VERSION "HNNBNNNYNNNNNNNNNNNNNNNNNNNNNNNNNNNNNNNNNN/4/%%%/4/'%**4NNN///"

NS_ :

BS_:

BU_: Airbag_MQB BAP_Tester_MQB BMS_MQB Datenlogger_MQB Gateway_MQB Getriebe_DQ_Hybrid_MQB Getriebe_DQ_MQB LEH_MQB Motor_Diesel_MQB Motor_Hybrid_MQB Motor_Otto_MQB SAK_MQB Waehlhebel_MQB

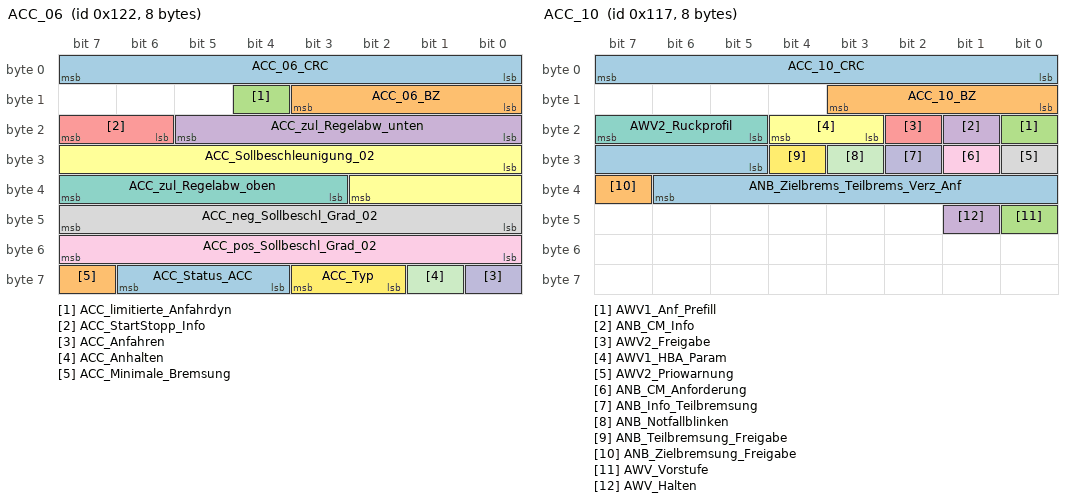
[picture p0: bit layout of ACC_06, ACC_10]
BO_ 290 ACC_06: 8 Gateway_MQB
 SG_ ACC_06_CRC : 0|8@1+ (1,0) [0|255] ""  Getriebe_DQ_Hybrid_MQB,Getriebe_DQ_MQB,Motor_Diesel_MQB,Motor_Hybrid_MQB,Motor_Otto_MQB
 SG_ ACC_06_BZ : 8|4@1+ (1,0) [0|15] ""  Getriebe_DQ_Hybrid_MQB,Getriebe_DQ_MQB,Motor_Diesel_MQB,Motor_Hybrid_MQB,Motor_Otto_MQB
 SG_ ACC_limitierte_Anfahrdyn : 12|1@1+ (1,0) [0|1] ""  Motor_Diesel_MQB,Motor_Hybrid_MQB,Motor_Otto_MQB
 SG_ ACC_zul_Regelabw_unten : 16|6@1+ (0.024,0) [0|1.512] "Unit_MeterPerSeconSquar"  Getriebe_DQ_Hybrid_MQB,Getriebe_DQ_MQB,Motor_Diesel_MQB,Motor_Hybrid_MQB,Motor_Otto_MQB
 SG_ ACC_StartStopp_Info : 22|2@1+ (1,0) [0|3] ""  Motor_Diesel_MQB,Motor_Otto_MQB
 SG_ ACC_Sollbeschleunigung_02 : 24|11@1+ (0.005,-7.22) [-7.22|3.005] "Unit_MeterPerSeconSquar"  Getriebe_DQ_Hybrid_MQB,Getriebe_DQ_MQB,Motor_Diesel_MQB,Motor_Hybrid_MQB,Motor_Otto_MQB
 SG_ ACC_zul_Regelabw_oben : 35|5@1+ (0.0625,0) [0|1.9375] "Unit_MeterPerSeconSquar"  Getriebe_DQ_Hybrid_MQB,Getriebe_DQ_MQB,Motor_Diesel_MQB,Motor_Hybrid_MQB,Motor_Otto_MQB
 SG_ ACC_neg_Sollbeschl_Grad_02 : 40|8@1+ (0.05,0) [0|12.75] "Unit_MeterPerCubicSecon"  Motor_Diesel_MQB,Motor_Hybrid_MQB,Motor_Otto_MQB
 SG_ ACC_pos_Sollbeschl_Grad_02 : 48|8@1+ (0.05,0) [0|12.75] "Unit_MeterPerCubicSecon"  Motor_Diesel_MQB,Motor_Hybrid_MQB,Motor_Otto_MQB
 SG_ ACC_Anfahren : 56|1@1+ (1,0) [0|1] ""  Getriebe_DQ_Hybrid_MQB,Getriebe_DQ_MQB,Motor_Diesel_MQB,Motor_Hybrid_MQB,Motor_Otto_MQB
 SG_ ACC_Anhalten : 57|1@1+ (1,0) [0|1] ""  Getriebe_DQ_Hybrid_MQB,Getriebe_DQ_MQB,Motor_Diesel_MQB,Motor_Hybrid_MQB,Motor_Otto_MQB
 SG_ ACC_Typ : 58|2@1+ (1,0) [0|3] ""  Motor_Diesel_MQB,Motor_Hybrid_MQB,Motor_Otto_MQB
 SG_ ACC_Status_ACC : 60|3@1+ (1,0) [0|7] ""  Getriebe_DQ_Hybrid_MQB,Getriebe_DQ_MQB,Motor_Diesel_MQB,Motor_Hybrid_MQB,Motor_Otto_MQB
 SG_ ACC_Minimale_Bremsung : 63|1@1+ (1,0) [0|1] ""  Motor_Diesel_MQB,Motor_Hybrid_MQB,Motor_Otto_MQB

BO_ 279 ACC_10: 8 Gateway_MQB
 SG_ ACC_10_CRC : 0|8@1+ (1,0) [0|255] ""  Airbag_MQB
 SG_ ACC_10_BZ : 8|4@1+ (1,0) [0|15] ""  Airbag_MQB
 SG_ AWV1_Anf_Prefill : 16|1@1+ (1,0) [0|1] ""  Airbag_MQB
 SG_ ANB_CM_Info : 17|1@1+ (1,0) [0|1] "" Vector__XXX
 SG_ AWV2_Freigabe : 18|1@1+ (1,0) [0|1] ""  Airbag_MQB
 SG_ AWV1_HBA_Param : 19|2@1+ (1,0) [0|3] "" Vector__XXX
 SG_ AWV2_Ruckprofil : 21|3@1+ (1,0) [0|7] "" Vector__XXX
 SG_ AWV2_Priowarnung : 24|1@1+ (1,0) [0|1] "" Vector__XXX
 SG_ ANB_CM_Anforderung : 25|1@1+ (1,0) [0|1] ""  Airbag_MQB
 SG_ ANB_Info_Teilbremsung : 26|1@1+ (1,0) [0|1] "" Vector__XXX
 SG_ ANB_Notfallblinken : 27|1@1+ (1,0) [0|1] "" Vector__XXX
 SG_ ANB_Teilbremsung_Freigabe : 28|1@1+ (1,0) [0|1] ""  Airbag_MQB
 SG_ ANB_Zielbrems_Teilbrems_Verz_Anf : 29|10@1+ (0.024,-20.016) [-20.016|4.536] "Unit_MeterPerSeconSquar"  Airbag_MQB
 SG_ ANB_Zielbremsung_Freigabe : 39|1@1+ (1,0) [0|1] ""  Airbag_MQB
 SG_ AWV_Vorstufe : 40|1@1+ (1,0) [0|1] "" Vector__XXX
 SG_ AWV_Halten : 41|1@1+ (1,0) [0|1] "" Vector__XXX

BO_ 64 Airbag_01: 8 Airbag_MQB
 SG_ Airbag_01_CRC : 0|8@1+ (1,0) [0|255] ""  BMS_MQB,Gateway_MQB,LEH_MQB,Motor_Diesel_MQB,Motor_Hybrid_MQB,Motor_Otto_MQB
 SG_ Airbag_01_BZ : 8|4@1+ (1,0) [0|15] ""  BMS_MQB,Gateway_MQB,LEH_MQB,Motor_Diesel_MQB,Motor_Hybrid_MQB,Motor_Otto_MQB
 SG_ AB_RGS_Anst : 12|4@1+ (1,0) [0|15] ""  Gateway_MQB
 SG_ AB_Front_Crash : 16|1@1+ (1,0) [0|1] ""  Gateway_MQB
 SG_ AB_Heck_Crash : 17|1@1+ (1,0) [0|1] ""  Gateway_MQB
 SG_ AB_SF_Crash : 18|1@1+ (1,0) [0|1] ""  Gateway_MQB
 SG_ AB_SB_Crash : 19|1@1+ (1,0) [0|1] ""  Gateway_MQB
 SG_ AB_Rollover_Crash : 20|1@1+ (1,0) [0|1] ""  Gateway_MQB
 SG_ AB_Crash_Int : 21|3@1+ (1,0) [0|7] ""  BMS_MQB,Gateway_MQB,LEH_MQB,Motor_Diesel_MQB,Motor_Hybrid_MQB,Motor_Otto_MQB
 SG_ AB_Lampe : 24|1@1+ (1,0) [0|1] ""  Gateway_MQB
 SG_ AB_Deaktiviert : 25|1@1+ (1,0) [0|1] ""  Gateway_MQB
 SG_ AB_VB_deaktiviert : 26|1@1+ (1,0) [0|1] ""  Gateway_MQB
 SG_ AB_Systemfehler : 27|1@1+ (1,0) [0|1] ""  BMS_MQB,Gateway_MQB,LEH_MQB
 SG_ AB_Diagnose : 28|1@1+ (1,0) [0|1] ""  Gateway_MQB
 SG_ AB_Stellgliedtest : 29|1@1+ (1,0) [0|1] ""  BMS_MQB,Gateway_MQB,Motor_Diesel_MQB,Motor_Hybrid_MQB,Motor_Otto_MQB
 SG_ AB_Erh_Auf_VB : 30|2@1+ (1,0) [0|3] ""  Gateway_MQB
 SG_ AB_Gurtwarn_VF : 32|1@1+ (1,0) [0|1] ""  Gateway_MQB
 SG_ AB_Gurtwarn_VB : 33|1@1+ (1,0) [0|1] ""  Gateway_MQB
 SG_ AB_Anzeige_Fussg : 34|2@1+ (1,0) [0|3] ""  Gateway_MQB
 SG_ AB_Texte_AKS : 36|2@1+ (1,0) [0|3] ""  Gateway_MQB
 SG_ AB_PAO_Leuchte_Anf : 38|1@1+ (1,0) [0|1] ""  Gateway_MQB
 SG_ AB_MKB_gueltig : 39|1@1+ (1,0) [0|1] ""  Gateway_MQB
 SG_ AB_MKB_Anforderung : 40|1@1+ (1,0) [0|1] ""  Gateway_MQB
 SG_ AB_Versorgungsspannung : 41|1@1+ (1,0) [0|1] ""  Gateway_MQB

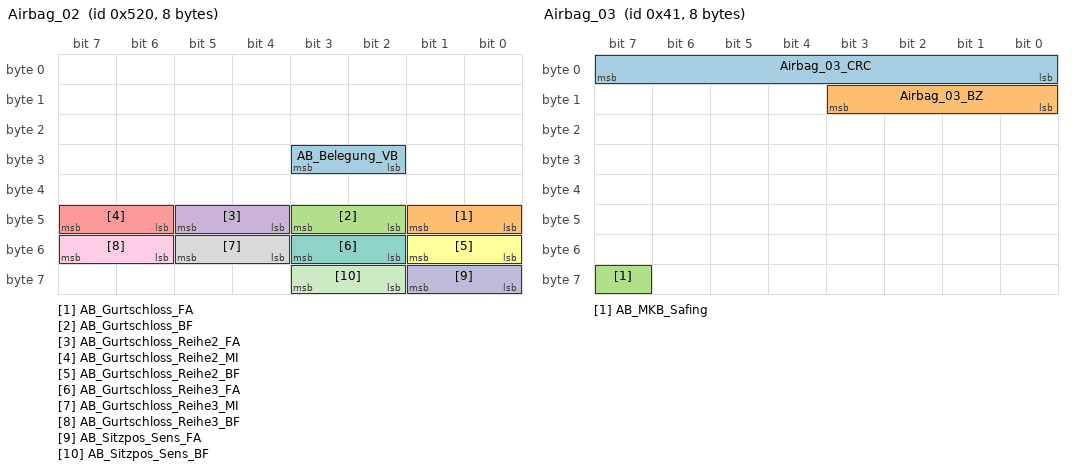
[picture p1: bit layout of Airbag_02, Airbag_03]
BO_ 1312 Airbag_02: 8 Airbag_MQB
 SG_ AB_Belegung_VB : 26|2@1+ (1,0) [0|3] ""  Gateway_MQB
 SG_ AB_Gurtschloss_FA : 40|2@1+ (1,0) [0|3] ""  Gateway_MQB,Motor_Diesel_MQB,Motor_Otto_MQB
 SG_ AB_Gurtschloss_BF : 42|2@1+ (1,0) [0|3] ""  Gateway_MQB
 SG_ AB_Gurtschloss_Reihe2_FA : 44|2@1+ (1,0) [0|3] ""  Gateway_MQB
 SG_ AB_Gurtschloss_Reihe2_MI : 46|2@1+ (1,0) [0|3] ""  Gateway_MQB
 SG_ AB_Gurtschloss_Reihe2_BF : 48|2@1+ (1,0) [0|3] ""  Gateway_MQB
 SG_ AB_Gurtschloss_Reihe3_FA : 50|2@1+ (1,0) [0|3] ""  Gateway_MQB
 SG_ AB_Gurtschloss_Reihe3_MI : 52|2@1+ (1,0) [0|3] ""  Gateway_MQB
 SG_ AB_Gurtschloss_Reihe3_BF : 54|2@1+ (1,0) [0|3] ""  Gateway_MQB
 SG_ AB_Sitzpos_Sens_FA : 56|2@1+ (1,0) [0|3] ""  Gateway_MQB
 SG_ AB_Sitzpos_Sens_BF : 58|2@1+ (1,0) [0|3] ""  Gateway_MQB

BO_ 65 Airbag_03: 8 Airbag_MQB
 SG_ Airbag_03_CRC : 0|8@1+ (1,0) [0|255] ""  Gateway_MQB
 SG_ Airbag_03_BZ : 8|4@1+ (1,0) [0|15] ""  Gateway_MQB
 SG_ AB_MKB_Safing : 63|1@1+ (1,0) [0|1] ""  Gateway_MQB

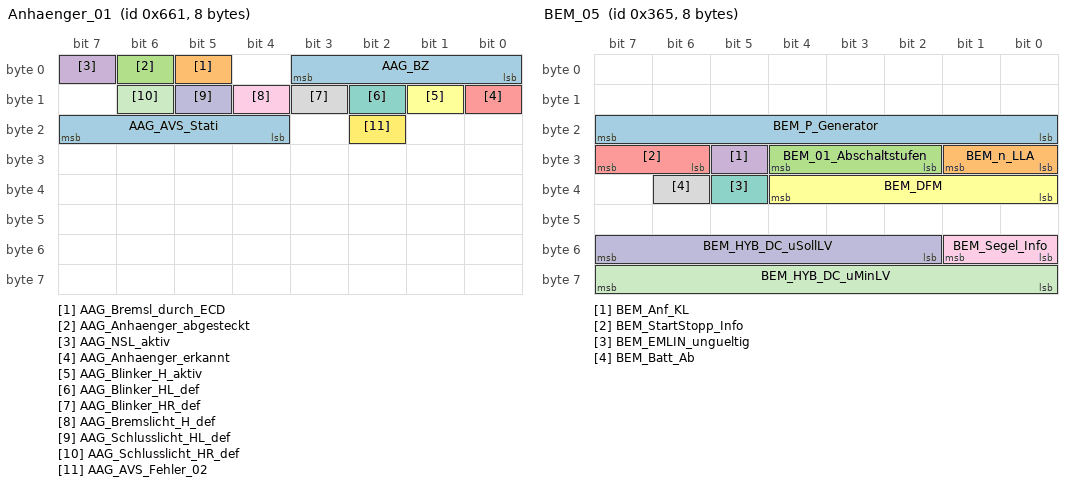
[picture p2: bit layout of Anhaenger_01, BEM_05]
BO_ 1633 Anhaenger_01: 8 Gateway_MQB
 SG_ AAG_BZ : 0|4@1+ (1,0) [0|15] ""  Motor_Diesel_MQB,Motor_Hybrid_MQB,Motor_Otto_MQB
 SG_ AAG_Bremsl_durch_ECD : 5|1@1+ (1,0) [0|1] ""  Motor_Diesel_MQB,Motor_Hybrid_MQB,Motor_Otto_MQB
 SG_ AAG_Anhaenger_abgesteckt : 6|1@1+ (1,0) [0|1] "" Vector__XXX
 SG_ AAG_NSL_aktiv : 7|1@1+ (1,0) [0|1] "" Vector__XXX
 SG_ AAG_Anhaenger_erkannt : 8|1@1+ (1,0) [0|1] ""  Motor_Diesel_MQB,Motor_Hybrid_MQB,Motor_Otto_MQB
 SG_ AAG_Blinker_H_aktiv : 9|1@1+ (1,0) [0|1] "" Vector__XXX
 SG_ AAG_Blinker_HL_def : 10|1@1+ (1,0) [0|1] "" Vector__XXX
 SG_ AAG_Blinker_HR_def : 11|1@1+ (1,0) [0|1] "" Vector__XXX
 SG_ AAG_Bremslicht_H_def : 12|1@1+ (1,0) [0|1] ""  Motor_Diesel_MQB,Motor_Hybrid_MQB,Motor_Otto_MQB
 SG_ AAG_Schlusslicht_HL_def : 13|1@1+ (1,0) [0|1] "" Vector__XXX
 SG_ AAG_Schlusslicht_HR_def : 14|1@1+ (1,0) [0|1] "" Vector__XXX
 SG_ AAG_AVS_Fehler_02 : 18|1@1+ (1,0) [0|1] "" Vector__XXX
 SG_ AAG_AVS_Stati : 20|4@1+ (1,0) [0|15] "" Vector__XXX

BO_ 2536767264 BAP_Debug_Cmd: 8 BAP_Tester_MQB
 SG_ BAP_Debug_Cmd : 0|16@1+ (1,0) [0|65535] ""  Airbag_MQB,Motor_Hybrid_MQB

BO_ 2536767280 BAP_Debug_Data: 8 Airbag_MQB
 SG_ BAP_Debug_Data : 0|64@1+ (1,0) [0|4294967295] ""  BAP_Tester_MQB

BO_ 2536709120 BAP_Hybrid_ASG_01: 8 Gateway_MQB
 SG_ BAP_Hybrid_FSG_01_Header : 0|8@1+ (1,0) [0|255] ""  Motor_Hybrid_MQB

BO_ 2536709121 BAP_Hybrid_ASG_02: 8 Gateway_MQB
 SG_ BAP_Hybrid_ASG_02_Header : 0|8@1+ (1,0) [0|255] ""  Motor_Hybrid_MQB

BO_ 2536709136 BAP_Hybrid_FSG_01: 8 Motor_Hybrid_MQB
 SG_ BAP_Hybrid_FSG_01_Header : 0|8@1+ (1,0) [0|255] ""  Gateway_MQB

BO_ 2536709888 BAP_RGS_ASG_01: 8 Gateway_MQB
 SG_ BAP_RGS_ASG_01_Header : 0|8@1+ (1,0) [0|255] ""  Airbag_MQB

BO_ 2536709904 BAP_RGS_FSG_01: 8 Airbag_MQB
 SG_ BAP_RGS_FSG_01_Header : 0|8@1+ (1,0) [0|255] ""  Gateway_MQB

BO_ 1626 BCM_01: 8 Gateway_MQB
 SG_ BCM_Bremsbelag_Sensor : 12|1@1+ (1,0) [0|1] "" Vector__XXX
 SG_ BCM_Bremsfluessigkeit_Sensor : 13|1@1+ (1,0) [0|1] "" Vector__XXX
 SG_ BCM1_Licht_Warn : 14|1@1+ (1,0) [0|1] "" Vector__XXX
 SG_ BCM_Waschwasser_Sensor : 15|1@1+ (1,0) [0|1] "" Vector__XXX
 SG_ BCM_Kuehlmittel_Sensor : 16|1@1+ (1,0) [0|1] ""  Motor_Diesel_MQB,Motor_Otto_MQB
 SG_ BCM1_Kl_15_HW_erkannt : 17|1@1+ (1,0) [0|1] "" Vector__XXX
 SG_ BCM_Eis_Offroad_Taste : 18|1@1+ (1,0) [0|1] ""  Getriebe_DQ_Hybrid_MQB,Getriebe_DQ_MQB,Motor_Diesel_MQB,Motor_Otto_MQB
 SG_ ZZH_Endlage_oben : 19|1@1+ (1,0) [0|1] "" Vector__XXX
 SG_ ZZH_Endlage_unten : 20|1@1+ (1,0) [0|1] "" Vector__XXX
 SG_ ZZH_Endlage_unplausibel : 21|1@1+ (1,0) [0|1] "" Vector__XXX
 SG_ BCM2_EZS_gedrueckt : 22|1@1+ (1,0) [0|1] "" Vector__XXX
 SG_ BCM2_SST_gedrueckt : 23|1@1+ (1,0) [0|1] "" Vector__XXX
 SG_ BCM_Hybrid_StartStopp_Taste : 24|1@1+ (1,0) [0|1] ""  Getriebe_DQ_Hybrid_MQB,Getriebe_DQ_MQB,Motor_Diesel_MQB,Motor_Hybrid_MQB,Motor_Otto_MQB
 SG_ BCM1_Warnblink_Taster : 25|1@1+ (1,0) [0|1] "" Vector__XXX
 SG_ BCM1_Valet_Parking_Taster : 26|1@1+ (1,0) [0|1] "" Vector__XXX
 SG_ BCM_Remotestart_Betrieb : 27|1@1+ (1,0) [0|1] ""  Motor_Diesel_MQB,Motor_Otto_MQB
 SG_ BCM1_HSK_Taster : 28|1@1+ (1,0) [0|1] "" Vector__XXX
 SG_ BCM1_Heckrollo_Taster : 29|1@1+ (1,0) [0|1] "" Vector__XXX
 SG_ BCM1_Rueckfahrlicht_Schalter : 30|1@1+ (1,0) [0|1] ""  Getriebe_DQ_Hybrid_MQB,Getriebe_DQ_MQB,Motor_Diesel_MQB,Motor_Hybrid_MQB,Motor_Otto_MQB
 SG_ BCM1_MH_Schalter : 31|1@1+ (1,0) [0|1] ""  Motor_Diesel_MQB,Motor_Otto_MQB
 SG_ BCM1_MH_WIV_Schalter : 32|1@1+ (1,0) [0|1] ""  Motor_Diesel_MQB,Motor_Hybrid_MQB,Motor_Otto_MQB
 SG_ BCM_Eco_Charisma_Taste : 33|1@1+ (1,0) [0|1] ""  Getriebe_DQ_Hybrid_MQB,Getriebe_DQ_MQB
 SG_ BCM_Thermomanagement : 34|2@1+ (1,0) [0|3] ""  Motor_Diesel_MQB,Motor_Hybrid_MQB,Motor_Otto_MQB
 SG_ BCM_Thermomanagement_Fehler : 36|1@1+ (1,0) [0|1] ""  Motor_Diesel_MQB,Motor_Hybrid_MQB,Motor_Otto_MQB
 SG_ BCM_Thermomanagement_gueltig : 37|1@1+ (1,0) [0|1] ""  Motor_Diesel_MQB,Motor_Hybrid_MQB,Motor_Otto_MQB
 SG_ BCM1_Lichtwarn_Texte : 38|2@1+ (1,0) [0|3] "" Vector__XXX

BO_ 869 BEM_05: 8 Gateway_MQB
 SG_ BEM_P_Generator : 16|8@1+ (50,0) [0|12700] "Unit_Watt"  Motor_Diesel_MQB,Motor_Hybrid_MQB,Motor_Otto_MQB
 SG_ BEM_n_LLA : 24|2@1+ (1,0) [0|3] ""  Motor_Diesel_MQB,Motor_Hybrid_MQB,Motor_Otto_MQB
 SG_ BEM_01_Abschaltstufen : 26|3@1+ (1,0) [0|7] ""  Motor_Diesel_MQB,Motor_Hybrid_MQB,Motor_Otto_MQB
 SG_ BEM_Anf_KL : 29|1@1+ (1,0) [0|1] ""  Motor_Diesel_MQB,Motor_Hybrid_MQB,Motor_Otto_MQB
 SG_ BEM_StartStopp_Info : 30|2@1+ (1,0) [0|3] ""  Motor_Diesel_MQB,Motor_Otto_MQB
 SG_ BEM_DFM : 32|5@1+ (3.225,0.025) [0.025|100] ""  Motor_Diesel_MQB,Motor_Hybrid_MQB,Motor_Otto_MQB
 SG_ BEM_EMLIN_ungueltig : 37|1@1+ (1,0) [0|1] ""  Motor_Diesel_MQB,Motor_Hybrid_MQB,Motor_Otto_MQB
 SG_ BEM_Batt_Ab : 38|1@1+ (1,0) [0|1] ""  Motor_Diesel_MQB,Motor_Hybrid_MQB,Motor_Otto_MQB
 SG_ BEM_Segel_Info : 48|2@1+ (1,0) [0|3] ""  Getriebe_DQ_Hybrid_MQB,Getriebe_DQ_MQB,Motor_Diesel_MQB,Motor_Hybrid_MQB,Motor_Otto_MQB
 SG_ BEM_HYB_DC_uSollLV : 50|6@1+ (0.1,10.6) [10.6|16] "Unit_Volt"  LEH_MQB
 SG_ BEM_HYB_DC_uMinLV : 56|8@1+ (0.1,0) [0|25.3] "Unit_Volt"  LEH_MQB

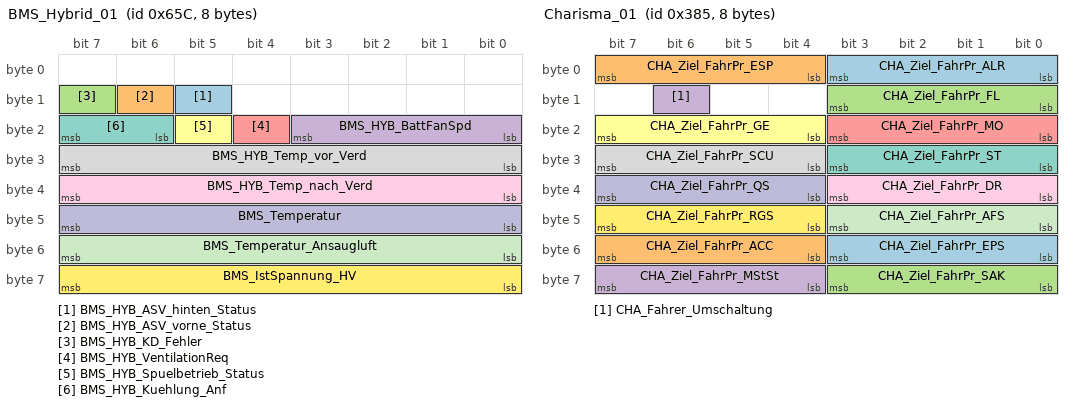
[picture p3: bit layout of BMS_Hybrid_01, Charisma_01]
BO_ 1628 BMS_Hybrid_01: 8 BMS_MQB
 SG_ BMS_HYB_ASV_hinten_Status : 13|1@1+ (1,0) [0|1] ""  Gateway_MQB
 SG_ BMS_HYB_ASV_vorne_Status : 14|1@1+ (1,0) [0|1] ""  Gateway_MQB
 SG_ BMS_HYB_KD_Fehler : 15|1@1+ (1,0) [0|1] ""  Gateway_MQB
 SG_ BMS_HYB_BattFanSpd : 16|4@1+ (10,0) [0|100] "Unit_PerCent"  Gateway_MQB
 SG_ BMS_HYB_VentilationReq : 20|1@1+ (1,0) [0|1] ""  Gateway_MQB
 SG_ BMS_HYB_Spuelbetrieb_Status : 21|1@1+ (1,0) [0|1] ""  Gateway_MQB
 SG_ BMS_HYB_Kuehlung_Anf : 22|2@1+ (1,0) [0|3] ""  Gateway_MQB
 SG_ BMS_HYB_Temp_vor_Verd : 24|8@1+ (0.5,-40) [-40|86.5] "Unit_DegreCelsi"  Gateway_MQB
 SG_ BMS_HYB_Temp_nach_Verd : 32|8@1+ (0.5,-40) [-40|86.5] "Unit_DegreCelsi"  Gateway_MQB
 SG_ BMS_Temperatur : 40|8@1+ (0.5,-40) [-40|86.5] "Unit_DegreCelsi"  Gateway_MQB
 SG_ BMS_Temperatur_Ansaugluft : 48|8@1+ (0.5,-40) [-40|86.5] "Unit_DegreCelsi"  Gateway_MQB
 SG_ BMS_IstSpannung_HV : 56|8@1+ (1,100) [100|350] "Unit_Volt"  Gateway_MQB

BO_ 2617236992 CCP_BMS_CRO_01: 8 Vector__XXX
 SG_ CCP_BMS_CRO_01_Data : 0|64@1+ (1,0) [0|1] ""  BMS_MQB

BO_ 2281692672 CCP_BMS_CRO_02: 8 Vector__XXX
 SG_ CCP_BMS_CRO_02_Data : 0|64@1+ (1,0) [0|1] ""  BMS_MQB

BO_ 2617236993 CCP_BMS_DTO_01: 8 BMS_MQB
 SG_ CCP_BMS_DTO_01_Data : 0|64@1+ (1,0) [0|1] "" Vector__XXX

BO_ 2281692673 CCP_BMS_DTO_02: 8 BMS_MQB
 SG_ CCP_BMS_DTO_02_Data : 0|64@1+ (1,0) [0|1] "" Vector__XXX

BO_ 2281684480 CCP_Getriebe_CRO_01: 8 Vector__XXX
 SG_ CCP_Getriebe_CRO_01_Data : 0|64@1+ (1,0) [0|4294967295] ""  Getriebe_DQ_Hybrid_MQB,Getriebe_DQ_MQB

BO_ 2281684481 CCP_Getriebe_DTO_01: 8 Getriebe_DQ_Hybrid_MQB
 SG_ CCP_Getriebe_DTO_01_Data : 0|64@1+ (1,0) [0|4294967295] "" Vector__XXX

BO_ 2281684482 CCP_Getriebe_DTO_02: 8 Getriebe_DQ_Hybrid_MQB
 SG_ CCP_Getriebe_DTO_02_Data : 0|64@1+ (1,0) [0|4294967295] "" Vector__XXX

BO_ 2281684483 CCP_Getriebe_DTO_03: 8 Getriebe_DQ_Hybrid_MQB
 SG_ CCP_Getriebe_DTO_03_Data : 0|64@1+ (1,0) [0|4294967295] "" Vector__XXX

BO_ 2281684484 CCP_Getriebe_DTO_04: 8 Getriebe_DQ_Hybrid_MQB
 SG_ CCP_Getriebe_DTO_04_Data : 0|64@1+ (1,0) [0|4294967295] "" Vector__XXX

BO_ 2617226752 CCP_Motor_CRO_01: 8 Gateway_MQB
 SG_ CCP_Motor_CRO_01_Data : 0|64@1+ (1,0) [0|4294967295] ""  Motor_Diesel_MQB,Motor_Hybrid_MQB,Motor_Otto_MQB

BO_ 2617226753 CCP_Motor_DTO_01: 8 Motor_Diesel_MQB
 SG_ CCP_Motor_DTO_01_Data : 0|64@1+ (1,0) [0|4294967295] ""  Gateway_MQB

BO_ 2617226754 CCP_Motor_DTO_02: 8 Motor_Diesel_MQB
 SG_ CCP_Motor_DTO_02_Data : 0|64@1+ (1,0) [0|4294967295] ""  Gateway_MQB

BO_ 2617226755 CCP_Motor_DTO_03: 8 Motor_Diesel_MQB
 SG_ CCP_Motor_DTO_03_Data : 0|64@1+ (1,0) [0|4294967295] ""  Gateway_MQB

BO_ 2617042432 CCP_Soundaktor_CRO_01: 8 Gateway_MQB
 SG_ CCP_Soundaktor_CRO_01_Data : 0|64@1+ (1,0) [0|4294967295] ""  SAK_MQB

BO_ 2617042433 CCP_Soundaktor_DTO_01: 8 SAK_MQB
 SG_ CCP_Soundaktor_DTO_01_Data : 0|64@1+ (1,0) [0|4294967295] ""  Gateway_MQB

BO_ 901 Charisma_01: 8 Gateway_MQB
 SG_ CHA_Ziel_FahrPr_ALR : 0|4@1+ (1,0) [0|15] "" Vector__XXX
 SG_ CHA_Ziel_FahrPr_ESP : 4|4@1+ (1,0) [0|15] "" Vector__XXX
 SG_ CHA_Ziel_FahrPr_FL : 8|4@1+ (1,0) [0|15] "" Vector__XXX
 SG_ CHA_Fahrer_Umschaltung : 14|1@1+ (1,0) [0|1] ""  Airbag_MQB,Getriebe_DQ_Hybrid_MQB,Getriebe_DQ_MQB,Motor_Diesel_MQB,Motor_Hybrid_MQB,Motor_Otto_MQB,SAK_MQB
 SG_ CHA_Ziel_FahrPr_MO : 16|4@1+ (1,0) [0|15] ""  Motor_Diesel_MQB,Motor_Hybrid_MQB,Motor_Otto_MQB
 SG_ CHA_Ziel_FahrPr_GE : 20|4@1+ (1,0) [0|15] ""  Getriebe_DQ_Hybrid_MQB,Getriebe_DQ_MQB
 SG_ CHA_Ziel_FahrPr_ST : 24|4@1+ (1,0) [0|15] "" Vector__XXX
 SG_ CHA_Ziel_FahrPr_SCU : 28|4@1+ (1,0) [0|15] "" Vector__XXX
 SG_ CHA_Ziel_FahrPr_DR : 32|4@1+ (1,0) [0|15] "" Vector__XXX
 SG_ CHA_Ziel_FahrPr_QS : 36|4@1+ (1,0) [0|15] "" Vector__XXX
 SG_ CHA_Ziel_FahrPr_AFS : 40|4@1+ (1,0) [0|15] "" Vector__XXX
 SG_ CHA_Ziel_FahrPr_RGS : 44|4@1+ (1,0) [0|15] ""  Airbag_MQB
 SG_ CHA_Ziel_FahrPr_EPS : 48|4@1+ (1,0) [0|15] "" Vector__XXX
 SG_ CHA_Ziel_FahrPr_ACC : 52|4@1+ (1,0) [0|15] "" Vector__XXX
 SG_ CHA_Ziel_FahrPr_SAK : 56|4@1+ (1,0) [0|15] ""  SAK_MQB
 SG_ CHA_Ziel_FahrPr_MStSt : 60|4@1+ (1,0) [0|15] "" Vector__XXX

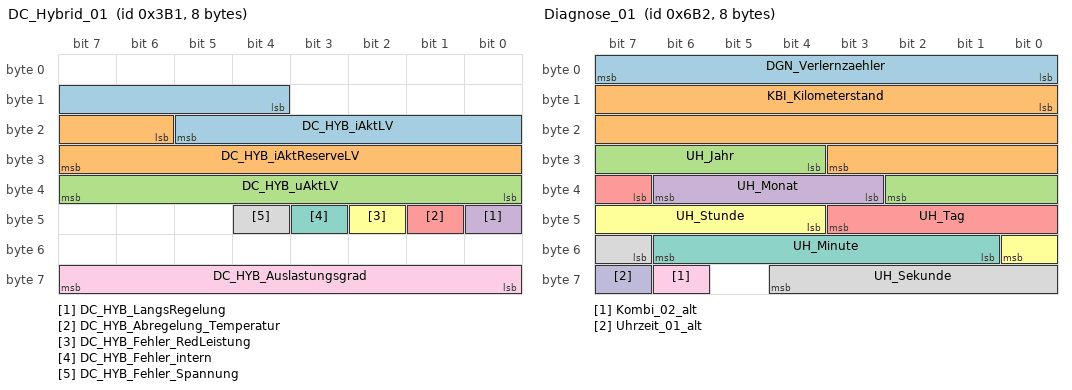
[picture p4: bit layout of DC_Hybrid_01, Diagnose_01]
BO_ 945 DC_Hybrid_01: 8 LEH_MQB
 SG_ DC_HYB_iAktLV : 12|10@1+ (1,-511) [-511|510] "Unit_Amper"  Gateway_MQB
 SG_ DC_HYB_iAktReserveLV : 22|10@1+ (1,-511) [-511|510] "Unit_Amper"  Gateway_MQB
 SG_ DC_HYB_uAktLV : 32|8@1+ (0.1,0) [0|25.3] "Unit_Volt"  Gateway_MQB
 SG_ DC_HYB_LangsRegelung : 40|1@1+ (1,0) [0|1] ""  Gateway_MQB
 SG_ DC_HYB_Abregelung_Temperatur : 41|1@1+ (1,0) [0|1] ""  Gateway_MQB
 SG_ DC_HYB_Fehler_RedLeistung : 42|1@1+ (1,0) [0|1] ""  Gateway_MQB
 SG_ DC_HYB_Fehler_intern : 43|1@1+ (1,0) [0|1] ""  Gateway_MQB
 SG_ DC_HYB_Fehler_Spannung : 44|1@1+ (1,0) [0|1] ""  Gateway_MQB
 SG_ DC_HYB_Auslastungsgrad : 56|8@1+ (0.4,0) [0|100] "Unit_PerCent"  Gateway_MQB

BO_ 2617235968 DEV_BMS_Resp_00: 8 BMS_MQB
 SG_ DEV_BMS_Resp_00_Data : 0|64@1+ (1,0) [0|4294967295] "" Vector__XXX

BO_ 2617235969 DEV_BMS_Resp_01: 8 BMS_MQB
 SG_ DEV_BMS_Resp_01_Data : 0|64@1+ (1,0) [0|4294967295] "" Vector__XXX

BO_ 2617235970 DEV_BMS_Resp_02: 8 BMS_MQB
 SG_ DEV_BMS_Resp_02_Data : 0|64@1+ (1,0) [0|4294967295] "" Vector__XXX

BO_ 2617235971 DEV_BMS_Resp_03: 8 BMS_MQB
 SG_ DEV_BMS_Resp_03_Data : 0|64@1+ (1,0) [0|4294967295] "" Vector__XXX

BO_ 2617235972 DEV_BMS_Resp_04: 8 BMS_MQB
 SG_ DEV_BMS_Resp_04_Data : 0|64@1+ (1,0) [0|4294967295] "" Vector__XXX

BO_ 2617235973 DEV_BMS_Resp_05: 8 BMS_MQB
 SG_ DEV_BMS_Resp_05_Data : 0|64@1+ (1,0) [0|4294967295] "" Vector__XXX

BO_ 2617235974 DEV_BMS_Resp_06: 8 BMS_MQB
 SG_ DEV_BMS_Resp_06_Data : 0|64@1+ (1,0) [0|4294967295] "" Vector__XXX

BO_ 2617235975 DEV_BMS_Resp_07: 8 BMS_MQB
 SG_ DEV_BMS_Resp_07_Data : 0|64@1+ (1,0) [0|4294967295] "" Vector__XXX

BO_ 2617227776 DEV_Getriebe_Resp_00: 8 Getriebe_DQ_Hybrid_MQB
 SG_ DEV_Getriebe_Resp_00_Data : 0|64@1+ (1,0) [0|4294967295] "" Vector__XXX

BO_ 2617227777 DEV_Getriebe_Resp_01: 8 Getriebe_DQ_Hybrid_MQB
 SG_ DEV_Getriebe_Resp_01_Data : 0|64@1+ (1,0) [0|4294967295] "" Vector__XXX

BO_ 2617227778 DEV_Getriebe_Resp_02: 8 Getriebe_DQ_Hybrid_MQB
 SG_ DEV_Getriebe_Resp_02_Data : 0|64@1+ (1,0) [0|4294967295] "" Vector__XXX

BO_ 2617227779 DEV_Getriebe_Resp_03: 8 Getriebe_DQ_Hybrid_MQB
 SG_ DEV_Getriebe_Resp_03_Data : 0|64@1+ (1,0) [0|4294967295] "" Vector__XXX

BO_ 2617227780 DEV_Getriebe_Resp_04: 8 Getriebe_DQ_Hybrid_MQB
 SG_ DEV_Getriebe_Resp_04_Data : 0|64@1+ (1,0) [0|4294967295] "" Vector__XXX

BO_ 2617227781 DEV_Getriebe_Resp_05: 8 Getriebe_DQ_Hybrid_MQB
 SG_ DEV_Getriebe_Resp_05_Data : 0|64@1+ (1,0) [0|4294967295] "" Vector__XXX

BO_ 2617227782 DEV_Getriebe_Resp_06: 8 Getriebe_DQ_Hybrid_MQB
 SG_ DEV_Getriebe_Resp_06_Data : 0|64@1+ (1,0) [0|4294967295] "" Vector__XXX

BO_ 2617227783 DEV_Getriebe_Resp_07: 8 Getriebe_DQ_Hybrid_MQB
 SG_ DEV_Getriebe_Resp_07_Data : 0|64@1+ (1,0) [0|4294967295] "" Vector__XXX

BO_ 2617154048 DEV_Waehlhebel_Resp_00: 8 Waehlhebel_MQB
 SG_ DEV_Waehlhebel_Resp_00_Data : 0|64@1+ (1,0) [0|4294967295] "" Vector__XXX

BO_ 2617154049 DEV_Waehlhebel_Resp_01: 8 Waehlhebel_MQB
 SG_ DEV_Waehlhebel_Resp_01_Data : 0|64@1+ (1,0) [0|4294967295] "" Vector__XXX

BO_ 2617154050 DEV_Waehlhebel_Resp_02: 8 Waehlhebel_MQB
 SG_ DEV_Waehlhebel_Resp_02_Data : 0|64@1+ (1,0) [0|4294967295] "" Vector__XXX

BO_ 2617154051 DEV_Waehlhebel_Resp_03: 8 Waehlhebel_MQB
 SG_ DEV_Waehlhebel_Resp_03_Data : 0|64@1+ (1,0) [0|4294967295] "" Vector__XXX

BO_ 2617154052 DEV_Waehlhebel_Resp_04: 8 Waehlhebel_MQB
 SG_ DEV_Waehlhebel_Resp_04_Data : 0|64@1+ (1,0) [0|4294967295] "" Vector__XXX

BO_ 2617154053 DEV_Waehlhebel_Resp_05: 8 Waehlhebel_MQB
 SG_ DEV_Waehlhebel_Resp_05_Data : 0|64@1+ (1,0) [0|4294967295] "" Vector__XXX

BO_ 1714 Diagnose_01: 8 Gateway_MQB
 SG_ DGN_Verlernzaehler : 0|8@1+ (1,0) [0|254] ""  Airbag_MQB,BMS_MQB,Getriebe_DQ_Hybrid_MQB,Getriebe_DQ_MQB,LEH_MQB,SAK_MQB
 SG_ KBI_Kilometerstand : 8|20@1+ (1,0) [0|1048573] "Unit_KiloMeter"  Airbag_MQB,BMS_MQB,Getriebe_DQ_Hybrid_MQB,Getriebe_DQ_MQB,LEH_MQB,Motor_Diesel_MQB,Motor_Hybrid_MQB,Motor_Otto_MQB,SAK_MQB
 SG_ UH_Jahr : 28|7@1+ (1,2000) [2000|2127] "Unit_Year"  Airbag_MQB,BMS_MQB,Getriebe_DQ_Hybrid_MQB,Getriebe_DQ_MQB,LEH_MQB,Motor_Diesel_MQB,Motor_Hybrid_MQB,Motor_Otto_MQB,SAK_MQB
 SG_ UH_Monat : 35|4@1+ (1,0) [1|12] "Unit_Month"  Airbag_MQB,BMS_MQB,Getriebe_DQ_Hybrid_MQB,Getriebe_DQ_MQB,LEH_MQB,Motor_Diesel_MQB,Motor_Hybrid_MQB,Motor_Otto_MQB,SAK_MQB
 SG_ UH_Tag : 39|5@1+ (1,0) [1|31] "Unit_Day"  Airbag_MQB,BMS_MQB,Getriebe_DQ_Hybrid_MQB,Getriebe_DQ_MQB,LEH_MQB,Motor_Diesel_MQB,Motor_Hybrid_MQB,Motor_Otto_MQB,SAK_MQB
 SG_ UH_Stunde : 44|5@1+ (1,0) [0|23] "Unit_Hours"  Airbag_MQB,BMS_MQB,Getriebe_DQ_Hybrid_MQB,Getriebe_DQ_MQB,LEH_MQB,Motor_Diesel_MQB,Motor_Hybrid_MQB,Motor_Otto_MQB,SAK_MQB
 SG_ UH_Minute : 49|6@1+ (1,0) [0|59] "Unit_Minut"  Airbag_MQB,BMS_MQB,Getriebe_DQ_Hybrid_MQB,Getriebe_DQ_MQB,LEH_MQB,Motor_Diesel_MQB,Motor_Hybrid_MQB,Motor_Otto_MQB,SAK_MQB
 SG_ UH_Sekunde : 55|6@1+ (1,0) [0|59] "Unit_Secon"  Airbag_MQB,BMS_MQB,Getriebe_DQ_Hybrid_MQB,Getriebe_DQ_MQB,LEH_MQB,Motor_Diesel_MQB,Motor_Hybrid_MQB,Motor_Otto_MQB,SAK_MQB
 SG_ Kombi_02_alt : 62|1@1+ (1,0) [0|1] ""  Airbag_MQB,BMS_MQB,LEH_MQB
 SG_ Uhrzeit_01_alt : 63|1@1+ (1,0) [0|1] ""  Airbag_MQB,BMS_MQB,LEH_MQB

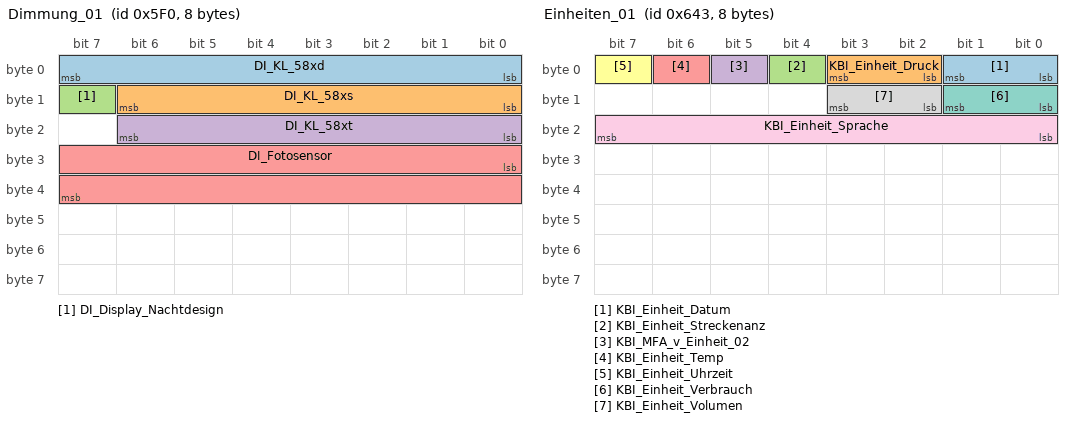
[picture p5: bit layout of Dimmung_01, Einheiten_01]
BO_ 1520 Dimmung_01: 8 Gateway_MQB
 SG_ DI_KL_58xd : 0|8@1+ (1,0) [0|253] ""  Airbag_MQB
 SG_ DI_KL_58xs : 8|7@1+ (1,0) [0|100] "Unit_PerCent" Vector__XXX
 SG_ DI_Display_Nachtdesign : 15|1@1+ (1,0) [0|1] "" Vector__XXX
 SG_ DI_KL_58xt : 16|7@1+ (1,0) [0|100] "Unit_PerCent" Vector__XXX
 SG_ DI_Fotosensor : 24|16@1+ (1,0) [0|65535] "" Vector__XXX

BO_ 1603 Einheiten_01: 8 Gateway_MQB
 SG_ KBI_Einheit_Datum : 0|2@1+ (1,0) [0|3] "" Vector__XXX
 SG_ KBI_Einheit_Druck : 2|2@1+ (1,0) [0|3] "" Vector__XXX
 SG_ KBI_Einheit_Streckenanz : 4|1@1+ (1,0) [0|1] ""  Motor_Diesel_MQB
 SG_ KBI_MFA_v_Einheit_02 : 5|1@1+ (1,0) [0|1] "" Vector__XXX
 SG_ KBI_Einheit_Temp : 6|1@1+ (1,0) [0|1] "" Vector__XXX
 SG_ KBI_Einheit_Uhrzeit : 7|1@1+ (1,0) [0|1] "" Vector__XXX
 SG_ KBI_Einheit_Verbrauch : 8|2@1+ (1,0) [0|3] "" Vector__XXX
 SG_ KBI_Einheit_Volumen : 10|2@1+ (1,0) [0|3] "" Vector__XXX
 SG_ KBI_Einheit_Sprache : 16|8@1+ (1,0) [0|255] "" Vector__XXX

BO_ 260 EPB_01: 8 Gateway_MQB
 SG_ EPB_01_CRC : 0|8@1+ (1,0) [0|255] ""  Getriebe_DQ_Hybrid_MQB,Getriebe_DQ_MQB,Motor_Diesel_MQB,Motor_Hybrid_MQB,Motor_Otto_MQB
 SG_ EPB_01_BZ : 8|4@1+ (1,0) [0|15] ""  Getriebe_DQ_Hybrid_MQB,Getriebe_DQ_MQB,Motor_Diesel_MQB,Motor_Hybrid_MQB,Motor_Otto_MQB
 SG_ EPB_QBit_Laengsbeschleunigung : 12|1@1+ (1,0) [0|1] "" Vector__XXX
 SG_ EPB_QBit_Pedalweg_Kuppl : 13|1@1+ (1,0) [0|1] "" Vector__XXX
 SG_ EPB_BCM2_Motor_Wakeup : 14|1@1+ (1,0) [0|1] "" Vector__XXX
 SG_ EPB_Freig_Verzoeg_Anf : 15|1@1+ (1,0) [0|1] ""  Motor_Diesel_MQB,Motor_Hybrid_MQB,Motor_Otto_MQB
 SG_ EPB_Verzoeg_Anf : 16|8@1+ (0.048,-7.968) [-7.968|4.224] "Unit_MeterPerSeconSquar" Vector__XXX
 SG_ EPB_Laengsbeschleunigung : 24|8@1+ (1,-128) [-128|126] "Unit_PerCentOfForceOfGravi" Vector__XXX
 SG_ EPB_Pedalweg_Kuppl : 32|8@1+ (0.4,0) [8|92] "Unit_PerCent" Vector__XXX
 SG_ EPB_Anfahrwunsch_erkannt : 48|1@1+ (1,0) [0|1] "" Vector__XXX
 SG_ EPB_DAA_Randbed_erf : 49|1@1+ (1,0) [0|1] ""  Getriebe_DQ_Hybrid_MQB,Getriebe_DQ_MQB
 SG_ EPB_Fehlerstatus : 50|2@1+ (1,0) [0|3] "" Vector__XXX
 SG_ EPB_Schalterposition : 52|2@1+ (1,0) [0|3] ""  Motor_Diesel_MQB,Motor_Hybrid_MQB,Motor_Otto_MQB
 SG_ EPB_QBit_Schalterpos : 54|1@1+ (1,0) [0|1] ""  Motor_Diesel_MQB,Motor_Hybrid_MQB,Motor_Otto_MQB
 SG_ EPB_Konsistenz_ACC : 55|1@1+ (1,0) [0|1] "" Vector__XXX
 SG_ EPB_Spannkraft : 56|5@1+ (1,0) [0|29] "Unit_KiloNewto"  Getriebe_DQ_Hybrid_MQB,Getriebe_DQ_MQB
 SG_ EPB_Status : 61|2@1+ (1,0) [0|3] ""  Getriebe_DQ_Hybrid_MQB,Getriebe_DQ_MQB,Motor_Diesel_MQB,Motor_Hybrid_MQB,Motor_Otto_MQB

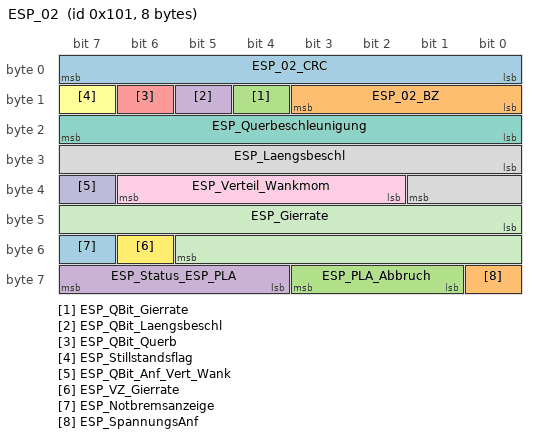
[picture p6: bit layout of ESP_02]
BO_ 257 ESP_02: 8 Gateway_MQB
 SG_ ESP_02_CRC : 0|8@1+ (1,0) [0|255] ""  Airbag_MQB,Getriebe_DQ_Hybrid_MQB,Getriebe_DQ_MQB,Motor_Diesel_MQB,Motor_Hybrid_MQB,Motor_Otto_MQB
 SG_ ESP_02_BZ : 8|4@1+ (1,0) [0|15] ""  Airbag_MQB,Getriebe_DQ_Hybrid_MQB,Getriebe_DQ_MQB,Motor_Diesel_MQB,Motor_Hybrid_MQB,Motor_Otto_MQB
 SG_ ESP_QBit_Gierrate : 12|1@1+ (1,0) [0|1] ""  Airbag_MQB,Getriebe_DQ_Hybrid_MQB,Getriebe_DQ_MQB
 SG_ ESP_QBit_Laengsbeschl : 13|1@1+ (1,0) [0|1] ""  Airbag_MQB,Getriebe_DQ_Hybrid_MQB,Getriebe_DQ_MQB,Motor_Diesel_MQB,Motor_Hybrid_MQB,Motor_Otto_MQB
 SG_ ESP_QBit_Querb : 14|1@1+ (1,0) [0|1] ""  Airbag_MQB,Getriebe_DQ_Hybrid_MQB,Getriebe_DQ_MQB,Motor_Diesel_MQB,Motor_Hybrid_MQB,Motor_Otto_MQB
 SG_ ESP_Stillstandsflag : 15|1@1+ (1,0) [0|1] "" Vector__XXX
 SG_ ESP_Querbeschleunigung : 16|8@1+ (0.01,-1.27) [-1.27|1.27] "Unit_ForceOfGravi"  Airbag_MQB,Getriebe_DQ_Hybrid_MQB,Getriebe_DQ_MQB,Motor_Diesel_MQB,Motor_Hybrid_MQB,Motor_Otto_MQB
 SG_ ESP_Laengsbeschl : 24|10@1+ (0.03125,-16) [-16|15.90625] "Unit_MeterPerSeconSquar"  Airbag_MQB,Getriebe_DQ_Hybrid_MQB,Getriebe_DQ_MQB,Motor_Diesel_MQB,Motor_Hybrid_MQB,Motor_Otto_MQB
 SG_ ESP_Verteil_Wankmom : 34|5@1+ (0.1,-1) [-1|1] "" Vector__XXX
 SG_ ESP_QBit_Anf_Vert_Wank : 39|1@1+ (1,0) [0|1] "" Vector__XXX
 SG_ ESP_Gierrate : 40|14@1+ (0.01,0) [0|163.82] "Unit_DegreOfArcPerSecon"  Airbag_MQB,Getriebe_DQ_Hybrid_MQB,Getriebe_DQ_MQB
 SG_ ESP_VZ_Gierrate : 54|1@1+ (1,0) [0|1] ""  Airbag_MQB,Getriebe_DQ_Hybrid_MQB,Getriebe_DQ_MQB
 SG_ ESP_Notbremsanzeige : 55|1@1+ (1,0) [0|1] ""  Airbag_MQB
 SG_ ESP_SpannungsAnf : 56|1@1+ (1,0) [0|1] "" Vector__XXX
 SG_ ESP_PLA_Abbruch : 57|3@1+ (1,0) [0|7] "" Vector__XXX
 SG_ ESP_Status_ESP_PLA : 60|4@1+ (1,0) [0|15] ""  Getriebe_DQ_Hybrid_MQB,Getriebe_DQ_MQB

BO_TX_BU_ 2536767280 : Airbag_MQB,Motor_Hybrid_MQB;
BO_TX_BU_ 2281684481 : Getriebe_DQ_Hybrid_MQB,Getriebe_DQ_MQB;
BO_TX_BU_ 2281684482 : Getriebe_DQ_Hybrid_MQB,Getriebe_DQ_MQB;
BO_TX_BU_ 2281684483 : Getriebe_DQ_Hybrid_MQB,Getriebe_DQ_MQB;
BO_TX_BU_ 2281684484 : Getriebe_DQ_Hybrid_MQB,Getriebe_DQ_MQB;
BO_TX_BU_ 2617226753 : Motor_Diesel_MQB,Motor_Hybrid_MQB,Motor_Otto_MQB;
BO_TX_BU_ 2617226754 : Motor_Diesel_MQB,Motor_Hybrid_MQB,Motor_Otto_MQB;
BO_TX_BU_ 2617226755 : Motor_Diesel_MQB,Motor_Hybrid_MQB,Motor_Otto_MQB;
BO_TX_BU_ 2617227776 : Getriebe_DQ_Hybrid_MQB,Getriebe_DQ_MQB;
BO_TX_BU_ 2617227777 : Getriebe_DQ_Hybrid_MQB,Getriebe_DQ_MQB;
BO_TX_BU_ 2617227778 : Getriebe_DQ_Hybrid_MQB,Getriebe_DQ_MQB;
BO_TX_BU_ 2617227779 : Getriebe_DQ_Hybrid_MQB,Getriebe_DQ_MQB;
BO_TX_BU_ 2617227780 : Getriebe_DQ_Hybrid_MQB,Getriebe_DQ_MQB;
BO_TX_BU_ 2617227781 : Getriebe_DQ_Hybrid_MQB,Getriebe_DQ_MQB;
BO_TX_BU_ 2617227782 : Getriebe_DQ_Hybrid_MQB,Getriebe_DQ_MQB;
BO_TX_BU_ 2617227783 : Getriebe_DQ_Hybrid_MQB,Getriebe_DQ_MQB;

CM_ "Modified by dbc-patcher V1.0F © 2009 Ingo Müller";
CM_ BO_ 290 "ab MQB";
CM_ SG_ 290 ACC_06_CRC "Für MLB:
Berechnung siehe Lastenheft 'Kommunikationsabsicherung für FlexRay und CAN''

Ab MQB und MLBevo:
Berechnung siehe Lastenheft 'End-to-End Kommunikationsabsicherung''

Endwerte siehe Begleitdokument 'S-PDU Kennungsfolgen'";
CM_ SG_ 290 ACC_limitierte_Anfahrdyn "Info für den Motor, dass beim ACC-Anfahren mit Zielfahrzeug seitens ACC eine limitierte Fahrpedalkennlinie gefordert wird.";
CM_ SG_ 290 ACC_zul_Regelabw_unten "Anforderung an den Triebstrangkoordinator. Zulässiger Betrag der Abweichung zwischen angeforderter 'ACC_Sollbeschleunigung(_02)' und umzusetzender Sollbeschleunigung  im TSK. Im TSK wird, abhängig vom Arbeitspunkt die Toleranz und die Sollbeschleunigung f";
CM_ SG_ 290 ACC_StartStopp_Info "Freigabe bzw. Startanforderung für Start/Stopp";
CM_ SG_ 290 ACC_Sollbeschleunigung_02 "Anforderung an den Triebstrangkoordinator , eine 'ACC_Sollbeschleunigung' umzusetzen.";
CM_ SG_ 290 ACC_zul_Regelabw_oben "Anforderung an den Triebstrangkoordinator. Zulässiger Betrag der Abweichung zwischen angeforderter 'ACC_Sollbeschleunigung(_02)' und umzusetzender Sollbeschleunigung  im TSK. Im TSK wird, abhängig vom Arbeitspunkt die Toleranz und die Sollbeschleunigung f";
CM_ SG_ 290 ACC_neg_Sollbeschl_Grad_02 "Empfehlung an den Triebstrangkoordinator , mit welchem betragsmäßig maximalen negativen Gradienten eine ACC-Anforderung 'ACC_Sollbeschleunigung_02' einzuregeln ist.";
CM_ SG_ 290 ACC_pos_Sollbeschl_Grad_02 "Empfehlung an den Triebstrangkoordinator , mit welchem betragsmäßig maximalen positiven Gradienten eine ACC-Anforderung 'ACC_Sollbeschleunigung_02' einzuregeln ist.";
CM_ SG_ 290 ACC_Anfahren "Anforderung Anfahren";
CM_ SG_ 290 ACC_Anhalten "Im Falle eines gesetzten Bits wird vom ACC ein Anhalten bis in den Stand gewünscht. Das Bit wird von ACC nur unterhalb einer appl. Geschwindigkeitsschwelle gesetzt. Notwendig für die ACCplus-Funktionalität. Nicht für B8 relevant, jedoch im Vorgriff auf di";
CM_ SG_ 290 ACC_Typ "Motor plausibilisiert seine eigene Kodierung";
CM_ SG_ 290 ACC_Status_ACC "ACC-Status für Handshake mit Triebstrangkoordinator.
";
CM_ SG_ 290 ACC_Minimale_Bremsung "Im Falle eines gesetzten Bits wird vom ACC dem TSK angezeigt, dass es sich im Resume_Suspend_Mode befindet. In diesem Mode darf der TSK keine ECD-Bremsung anfordern, unabhängig von der 'ACC_Sollbeschleunigungsanforderung'. Eine Fahrzeugverzögerung darf nu";
CM_ BO_ 279 "ersetzt AWV_01";
CM_ SG_ 279 ACC_10_CRC "Für MLB:
Berechnung siehe Lastenheft 'Kommunikationsabsicherung für FlexRay und CAN''

Ab MQB und MLBevo:
Berechnung siehe Lastenheft 'End-to-End Kommunikationsabsicherung''

Endwerte siehe Begleitdokument 'S-PDU Kennungsfolgen'";
CM_ SG_ 279 AWV1_Anf_Prefill "Anforderung an ESP, dass die Prefill-Funktion aktiviert werden soll.
Nur Audi B8: Umsetzung der Prefill-Anforderung im ESP nur in Verbindung mit gesetztem Bit 'AWV1_Freigabe'.";
CM_ SG_ 279 ANB_CM_Info "Information über die ANB_CM-Ausprägung";
CM_ SG_ 279 AWV2_Freigabe "Freigabit für die Warnruck-Anforderung an das ESP";
CM_ SG_ 279 AWV1_HBA_Param "Anforderung an ESP, welcher HBA-Parametersatz verwendet werden soll. Die Festlegung der Empfindlichkeitsschwellen der verschiedenen Parametersätze erfolgt mit der Applikation des Gesamtsystems ESP/ACC bzw. des HBA.
Nur Audi B8: Umsetzung der Anforderung ";
CM_ SG_ 279 AWV2_Ruckprofil "Anforderung an ESP, welcher Ruck aus einer Auswahl von max. 7 verschiedenen Ruckprofilen verwendet werden soll. Eine Umsetzung der Ruckanforderung im ESP erfolgt nur mit gesetztem Bit 'AWV2 Freigabe'.";
CM_ SG_ 279 AWV2_Priowarnung "Im Falle einer AWV2-Vorwarnung (optisch/akustisch) oder eines AWV2-Bremsruckes soll im LDW eine Fahrerwarnung bzgl. Verlassen der Fahrspur unterdrückt werden. (AWV2 hat Priorität. Eine gleichzeitige LDW-Warnung könnte den Fahrer irritieren.) 
";
CM_ SG_ 279 ANB_CM_Anforderung "ANB_CM-Anforderungsbit an das ESP";
CM_ SG_ 279 ANB_Info_Teilbremsung "Über das Signal s_ANB_Info_Teilbremsung muss das ACC-SG dem ESP-SG dauerhaft beginnend mit einer Teilbremsung-Anforderung mitteilen welche Ausprägung angefordert wird.

Signaldefinition: 
0x0 = Ausprägung 'Standard'
0x1 = Ausprägung 'Erweitert'";
CM_ SG_ 279 ANB_Notfallblinken "Info an das BCM_2 die Warnblinkanlage anzusteuern";
CM_ SG_ 279 ANB_Teilbremsung_Freigabe "Freigabe-Bit der Teilbremsung an das ESP";
CM_ SG_ 279 ANB_Zielbrems_Teilbrems_Verz_Anf "Verzögerungsanforderung der Funktionen Zielbremsung und Teibremsung an das ESP";
CM_ SG_ 279 ANB_Zielbremsung_Freigabe "Freigabe-Bit der Zielbremsung an das ESP";
CM_ SG_ 279 AWV_Vorstufe "Info an das Restfahrzeug, dass in Kürze eine Notbremsung/schnelles Ausweichmanöver erfolgt (Info wird u.a. in Dämpferregelung zur Anpassung der Regelung verwendet)";
CM_ SG_ 279 AWV_Halten "Anforderung an das ESP, das Fahrzeug nach erfolgter automatischer Bremsung bis in den Stillstand im Stillstand zu halten und eine Fahrer-Überwachung zu aktivieren.";
CM_ BO_ 64 "ab MQB mit CRC-8";
CM_ SG_ 64 Airbag_01_CRC "Für MLB:
Berechnung siehe Lastenheft 'Kommunikationsabsicherung für FlexRay und CAN''

Ab MQB und MLBevo:
Berechnung siehe Lastenheft 'End-to-End Kommunikationsabsicherung''

Endwerte siehe Begleitdokument 'S-PDU Kennungsfolgen'";
CM_ SG_ 64 AB_RGS_Anst "PreCrash-Ansteuerung reversibler Gurtstraffer (Aktivierung und Kraftniveau)

10xx = deaktiviert";
CM_ SG_ 64 AB_Front_Crash "Bit wird bei Überschreitung der Gurtstraffer-, US- und RdW-Schwelle gesetzt";
CM_ SG_ 64 AB_Heck_Crash "Wird für alle neu anlaufenden Projekte umgesetzt: AB8.4, Audi8/VW8";
CM_ SG_ 64 AB_SF_Crash "Z.Zt. nur in Verbindung mit Crash-Intensität >= 100b (Kraftstoffpumpenabschaltung) verwendet.";
CM_ SG_ 64 AB_SB_Crash "Z.Zt. nur in Verbindung mit Crash-Intensität >= 100b (Kraftstoffpumpenabschaltung) verwendet.
";
CM_ SG_ 64 AB_Rollover_Crash "Wird im B6/B7 Cabrio und New Beetle Cabrio bedient. ";
CM_ SG_ 64 AB_Crash_Int "Crash_Intensität_1 = fahrzeugabhängige Reaktionen im Crash
Crash_Intensität_2 = fahrzeugabhängige Reaktionen im Crash
Crash_Intensität_3 = fahrzeugabhängige Reaktionen im Crash

Die jeweiligen fahrzeugabhängigen Reaktionen im Crash sind in einem separ";
CM_ SG_ 64 AB_Lampe "Sicherheitswarnlampe im Kombi wird vom Airbag-SG angesteuert; Zustand der Lampe wird auf dem CAN-Bus ausgegeben (auch Blinkinformation).";
CM_ SG_ 64 AB_Deaktiviert "Airbag oder Gurtstraffer wurden per Anpassung deaktiviert: Aktualisierung erst nach Selbsttest";
CM_ SG_ 64 AB_VB_deaktiviert "Als Option vorgehalten, Beifahrerairbag wurden per Schlüsselschalter oder Insassenerkennung deaktiviert";
CM_ SG_ 64 AB_Systemfehler "Systemfehler Ggf. wird Warnlampe dauernd eingeschaltet.";
CM_ SG_ 64 AB_Diagnose "Airbag in Diagnose";
CM_ SG_ 64 AB_Stellgliedtest "Information, ob Airbag im Stellgliedtest ist, um eine Notrufauflösung beim Stellgliedtest zu verhindern";
CM_ SG_ 64 AB_Erh_Auf_VB "Der Fahrer soll bei einem Statuswechsel des Beifahrerairbags (ausgelöst durch die Beifahrerinsassenerkennung oder den Schlüsselschloßschalter) aufmerksam gemacht werden durch eine Anzeige im Kombi. Nur Audi: gültig für: AB2 (4-Türer AU352), B7, C6, D3";
CM_ SG_ 64 AB_Gurtwarn_VF "Fahrer hat Gurt nicht gesteckt, Anzeige im Kombi";
CM_ SG_ 64 AB_Gurtwarn_VB "Beifahrer hat Gurt nicht gesteckt, Anzeige im Kombi";
CM_ SG_ 64 AB_Anzeige_Fussg "Anzeige für ausgelöste Fussgängerschutz-Aktuatorik";
CM_ SG_ 64 AB_Texte_AKS "Textanzeige für pyrotechnische Auslösung der aktiven Kopfstütze (AKS)";
CM_ SG_ 64 AB_PAO_Leuchte_Anf "Anforderung an die Passenger-Airbag-Off Leuchte in der Dachkonsole (ein / aus), Einsatz nur bei PAG";
CM_ SG_ 64 AB_MKB_gueltig "Multi-Kollisions-Bremsung im Airbag freigeschaltet";
CM_ SG_ 64 AB_MKB_Anforderung "Anforderung Multi-Kollisions-Bremsung";
CM_ SG_ 64 AB_Versorgungsspannung "Übertragung der Plausibilitätsinformation Kl.15-Last vs. Kl.15-CAN.
Bedienung im Fall Kl.15-Last 'EIN' und Kl.15-CAN 'AUS' mit Ausgabe Warnung/Akustik im Kombi.";
CM_ SG_ 1312 AB_Belegung_VB "Belegungserkennung vorne Beifahrer. Wird in US-Steuergeräten über Bladder-Matte bedient, optional bei RdW, falls SBE_EuroNCAP entschieden wird.";
CM_ SG_ 1312 AB_Gurtschloss_FA "Gurtschlosstatatus Fahrerseite";
CM_ SG_ 1312 AB_Gurtschloss_BF "Gurtschlossstatus Beifahrerseite";
CM_ SG_ 1312 AB_Gurtschloss_Reihe2_FA "Gurtschlossstatus 2. Reihe Fahrerseite, Mehrausstattung";
CM_ SG_ 1312 AB_Gurtschloss_Reihe2_MI "Gurtschlossstatus 2. Reihe Mitte,  Mehrausstattung";
CM_ SG_ 1312 AB_Gurtschloss_Reihe2_BF "Gurtschlossstatus 2. Reihe Beifahrerseite,  Mehrausstattung";
CM_ SG_ 1312 AB_Gurtschloss_Reihe3_FA "Gurtschlossstatus 3. Reihe Fahrerseite,  Mehrausstattung";
CM_ SG_ 1312 AB_Gurtschloss_Reihe3_MI "Gurtschlossstatus 3. Reihe Mitte,  Mehrausstattung";
CM_ SG_ 1312 AB_Gurtschloss_Reihe3_BF "Gurtschlossstatus 3. Reihe Beifahrerseite,  Mehrausstattung";
CM_ SG_ 1312 AB_Sitzpos_Sens_FA "Ausgabe Sitzposition Fahrer";
CM_ SG_ 1312 AB_Sitzpos_Sens_BF "Ausgabe Sitzposition Beifahrer";
CM_ SG_ 65 Airbag_03_CRC "Für MLB:
Berechnung siehe Lastenheft 'Kommunikationsabsicherung für FlexRay und CAN''

Ab MQB und MLBevo:
Berechnung siehe Lastenheft 'End-to-End Kommunikationsabsicherung''

Endwerte siehe Begleitdokument 'S-PDU Kennungsfolgen'";
CM_ SG_ 65 AB_MKB_Safing "Safing für Multi-Kollisions-Bremsung";
CM_ BO_ 1633 "ab MQB 7.2";
CM_ SG_ 1633 AAG_BZ "4bit-Botschaftszaehler, wird in jeder Sendebotschaft inkrementiert

";
CM_ SG_ 1633 AAG_Bremsl_durch_ECD "Bremslicht durch ECD aktiv";
CM_ SG_ 1633 AAG_Anhaenger_abgesteckt "Anhaenger wurde bei Kl. 15 aus abgesteckt";
CM_ SG_ 1633 AAG_NSL_aktiv "Anhaenger Nebelschlusslicht aktiv";
CM_ SG_ 1633 AAG_Anhaenger_erkannt "Erkennung Anhaenger ";
CM_ SG_ 1633 AAG_Blinker_H_aktiv "Status: Anhaenger Blinker aktiv";
CM_ SG_ 1633 AAG_Blinker_HL_def "Anhaenger Blinker links defekt";
CM_ SG_ 1633 AAG_Blinker_HR_def "Anhaenger Blinker rechts defekt";
CM_ SG_ 1633 AAG_Bremslicht_H_def "Anhaenger Bremslicht defekt";
CM_ SG_ 1633 AAG_Schlusslicht_HL_def "Anhaenger Schlußlicht links defekt";
CM_ SG_ 1633 AAG_Schlusslicht_HR_def "Anhaenger Schlußlicht rechts defekt";
CM_ SG_ 1633 AAG_AVS_Fehler_02 "Fehler AVS";
CM_ SG_ 1633 AAG_AVS_Stati "Status AVS (bei abnehmbarer oder mech.schwenkbarer Anhängerkupplung ist der Status immer 0)
";
CM_ BO_ 2536767264 "BAP-Msg vom Funktionssteuergerät";
CM_ BO_ 2536767280 "BAP-Msg vom Funktionssteuergerät";
CM_ SG_ 1626 BCM_Bremsbelag_Sensor "Sensorsignal der Stromschleife  für Bremsbelagverschleiß aktuell, entstört, unbewertet";
CM_ SG_ 1626 BCM_Bremsfluessigkeit_Sensor "Kontaktsignal des Sensorschalters für die Bremsflüssigkeitsreserve aktuell, entstört, unbewertet";
CM_ SG_ 1626 BCM1_Licht_Warn "Lichtwarnung";
CM_ SG_ 1626 BCM_Waschwasser_Sensor "Signal der Sensorelektroden für die Waschwasserreserve aktuell, entstört, bewertet (OK/Mangel)";
CM_ SG_ 1626 BCM_Kuehlmittel_Sensor "Signal der Sensorelektroden für die Kühlmittelreserve aktuell, entstört, bewertet (OK/Mangel)";
CM_ SG_ 1626 BCM1_Kl_15_HW_erkannt "Erkennung Klemme 15 (Hardware) vom BCM1
";
CM_ SG_ 1626 BCM_Eis_Offroad_Taste "Betaetigung Taste 'Eis' oder alternativ Taste 'Offroad'";
CM_ SG_ 1626 ZZH_Endlage_oben "obere Endlagenerkennung ZZH
";
CM_ SG_ 1626 ZZH_Endlage_unten "untere Endlagenerkennung ZZH
";
CM_ SG_ 1626 ZZH_Endlage_unplausibel "Erkennungung unplausible Endlage ZZH
";
CM_ SG_ 1626 BCM2_EZS_gedrueckt "Betätigung EZS";
CM_ SG_ 1626 BCM2_SST_gedrueckt "Betätigung Start-Stop-Taster (Kessy-Fahrzeug)";
CM_ SG_ 1626 BCM_Hybrid_StartStopp_Taste "Betaetigung Taster 'Hybrid' oder alternativ Taster 'Start/Stopp Deaktivierung', je nach Verbau";
CM_ SG_ 1626 BCM1_Warnblink_Taster "Warnblinktaster";
CM_ SG_ 1626 BCM1_Valet_Parking_Taster "Valet Parking Taster ";
CM_ SG_ 1626 BCM_Remotestart_Betrieb "Anforderung Remotestartbetrieb";
CM_ SG_ 1626 BCM1_HSK_Taster "Taster für Entriegelung Handschuhkasten
";
CM_ SG_ 1626 BCM1_Heckrollo_Taster "Betätigung Taster Heckrollo
";
CM_ SG_ 1626 BCM1_Rueckfahrlicht_Schalter "Rückfahrlichtschalter
Die Ganginformation wird unentprellt übertragen, im AT-Getriebe wird evtl. kurzzeitig der R-Gang angezeigt.
Eine Entprellung muß im Empfänger erfolgen (typisch 400ms).";
CM_ SG_ 1626 BCM1_MH_Schalter "Motorhaubenkontakt";
CM_ SG_ 1626 BCM1_MH_WIV_Schalter "Bewerteter Motorhaubenkontakt fuer WIV";
CM_ SG_ 1626 BCM_Eco_Charisma_Taste "Betätigung Taster ECO alias BlueKey oder Charisma";
CM_ SG_ 1626 BCM_Thermomanagement "Nur bei Verbau eines unvernetzten Heizungsbedienteil: Heizungsanforderung zur Berücksichtigung im Thermomanagement (Stellung des Kalt-Warm-Stellers wird in diesem Fall vom BCM eingelesen)";
CM_ SG_ 1626 BCM_Thermomanagement_Fehler "Fehler-Bit: Das BCM hat bei Verbau eines Heizungsbedienteils einen Fehler im Spannungssignal des Kalt-Warm-Stellers erkannt (Out-of-Range)
";
CM_ SG_ 1626 BCM_Thermomanagement_gueltig "Gueltig-Bit, mit dem das BCM  den Verbau eines Heizungsbedienteils kennzeichnet. Die Heizungsanforderung wird dann in BCM_Thermomanagement übertragen.";
CM_ SG_ 1626 BCM1_Lichtwarn_Texte "Anforderung von Lichtwarnungen vom BCM1 zum Kombi";
CM_ BO_ 869 "ab MQB";
CM_ SG_ 869 BEM_P_Generator "Es gilt: Signalspec BEM_P_Generator v1.0

Mechanische Generatorleistung dient dem Motorsteuergerät zur Berechnung der Motorlast; Genauigkeit ca. +/- (500W + 20% vom Messwert)";
CM_ SG_ 869 BEM_n_LLA "Es gilt: Signalspec BEM_n_LLA v1.0

Anforderung einer Leerlaufdrehzahlanhebung in drei Stufen. Die Höhe der jeweiligen LL-Drehzahlstufe ist im Motorsteuergerät appliziert.



";
CM_ SG_ 869 BEM_01_Abschaltstufen "Signal inhaltlich identisch mit BEM_02_Abschaltstufen. Namentliche Umbenennung wegen Standard-SW im Gateway-BEM im B8 (Handling gleicher Signalnamen im Source-Code).
Abschaltstufen des Ruhestrommanagements 
(Initialisierungswert aus EEPROM)";
CM_ SG_ 869 BEM_Anf_KL "Es gilt: Signalspec BEM_Anf_KL v1.1
Das BEM fordert über das MSG den Kühlerlüfter-Betrieb an; hierzu wird ein minimaler Leistungswert im MSG appliziert. 
Szenario: bei erkannter abgetrennten Batterie soll durch Ansteuerung des Kühlerlüfters das Energien";
CM_ SG_ 869 BEM_StartStopp_Info "Stopp-Freigabe und Start-Anforderung an den Start-Stopp-Koordinator";
CM_ SG_ 869 BEM_DFM "Generatorauslastungsgrad, vom Generator über LIN an das Gateway gesandt. Das Motorsteuergerät regelt auf dieses Signal die PTC, das Energiemanagement im BSG/BCM kalkuliert die Bordnetzauslastung";
CM_ SG_ 869 BEM_EMLIN_ungueltig "Energie-Lin - Signale sind ungültig vom Slave Batteriedatenmodul oder Generator
0 = Signale gültig
1 = Signale ungültig";
CM_ SG_ 869 BEM_Batt_Ab "Batterieverbindungskontrolle:
0x0: Batterie am Bordnetz
0x1: Batterie ab erkannt";
CM_ SG_ 869 BEM_Segel_Info "0: keine Anforderung 
(Segeln ist ohne Einschänkung erlaubt)
1: Mindestdrehzahl 1 
(Segeln ist mit Einschänkung erlaubt)
2: Mindestdrehzahl 2
(Segeln ist mit Einschänkung erlaubt)
3: Segelveto
(Segeln ist nicht  erlaubt)";
CM_ SG_ 869 BEM_HYB_DC_uSollLV "Sollwert für die Bordnetzspannung im Tiefsetzbetrieb vom Traktionsnetz ins Bordnetz (Hybrid)";
CM_ SG_ 869 BEM_HYB_DC_uMinLV "Abregelgrenze: minimal erlaubte Bordnetzspannung im Hochsetzbetrieb (Hybrid)";
CM_ SG_ 1628 BMS_HYB_ASV_hinten_Status "Status Absperrventil des Kältemittelkreislaufs zur Batteriekühlung";
CM_ SG_ 1628 BMS_HYB_ASV_vorne_Status "Status Absperrventil des Kältemittelkreislaufs zur Innenraumklimatisierung";
CM_ SG_ 1628 BMS_HYB_KD_Fehler "Bei gesetztem Bit ist mindestens ein Kundendienstfehler eingetragen";
CM_ SG_ 1628 BMS_HYB_BattFanSpd "Relativwert der Batterielüfter-Ansteuerung bezogen auf Maximalwert";
CM_ SG_ 1628 BMS_HYB_VentilationReq "BMS fordert bei Climatronic die Öffnung der Umluftklappe an";
CM_ SG_ 1628 BMS_HYB_Spuelbetrieb_Status "Status Betriebsart der Batterielüftung (Umluft-/Spülbetrieb)";
CM_ SG_ 1628 BMS_HYB_Kuehlung_Anf "Anforderung für aktive Batteriekühlung in vier Stufen:
Stufe 0: keine Kühlanforderung
Stufe 1: 10 °C Verdampfertemperatur Klima
Stufe 2: 3 °C Verdampfertemperatur Klima
Stufe 3: maximale Kühlleistung Klima";
CM_ SG_ 1628 BMS_HYB_Temp_vor_Verd "Lufttemperatur im Klimagerät BMS vor Verdampfer";
CM_ SG_ 1628 BMS_HYB_Temp_nach_Verd "Lufttemperatur im Klimagerät BMS nach Verdampfer";
CM_ SG_ 1628 BMS_Temperatur "battery temperature / Momentanwert: Temperatur der Traktionsbatterie";
CM_ SG_ 1628 BMS_Temperatur_Ansaugluft "Temperature of inlet air / Momentanwert: Ansauglufttemperatur der Batteriekühlung";
CM_ SG_ 1628 BMS_IstSpannung_HV "HV Spannungswert";
CM_ BO_ 901 "ab MQB ohne CHK und mit geänderter Sendeart";
CM_ SG_ 901 CHA_Ziel_FahrPr_ALR "Anforderung Ziel-Fahrprogramm Allrad";
CM_ SG_ 901 CHA_Ziel_FahrPr_ESP "Anforderung Ziel-Fahrprogramm ESP";
CM_ SG_ 901 CHA_Ziel_FahrPr_FL "Anforderung Ziel-Fahrprogramm Funktion Freilauf";
CM_ SG_ 901 CHA_Fahrer_Umschaltung "Die manuelle Umschaltung durch den Fahrer soll signalisiert werden, um zu automatischen Umschaltungen (z.B. Retries) differenzieren zu können.";
CM_ SG_ 901 CHA_Ziel_FahrPr_MO "Anforderung Ziel-Fahrprogramm Motor";
CM_ SG_ 901 CHA_Ziel_FahrPr_GE "Anforderung Ziel-Fahrprogramm Getriebe";
CM_ SG_ 901 CHA_Ziel_FahrPr_ST "Anforderung Ziel-Fahrprogramm ServoTronic";
CM_ SG_ 901 CHA_Ziel_FahrPr_SCU "Anforderung Ziel-Fahrprogramm SCU";
CM_ SG_ 901 CHA_Ziel_FahrPr_DR "Anforderung Ziel-Fahrprogramm Dämpfer";
CM_ SG_ 901 CHA_Ziel_FahrPr_QS "Anforderung Ziel-Fahrprogramm Quattro Sport";
CM_ SG_ 901 CHA_Ziel_FahrPr_AFS "Anforderung Ziel-Fahrprogramm AFS";
CM_ SG_ 901 CHA_Ziel_FahrPr_RGS "Anforderung Ziel-Fahrprogramm Funktion Reversibler Gurtstraffer";
CM_ SG_ 901 CHA_Ziel_FahrPr_EPS "Anforderung Ziel-Fahrprogramm Elekrische Lenkhilfe";
CM_ SG_ 901 CHA_Ziel_FahrPr_ACC "Anforderung Ziel-Fahrprogramm ACC";
CM_ SG_ 901 CHA_Ziel_FahrPr_SAK "Anforderung Ziel-Fahrprogramm Soundaktuator";
CM_ SG_ 901 CHA_Ziel_FahrPr_MStSt "Anforderung Ziel-Fahrprogramm Funktion Motor Start-Stopp";
CM_ SG_ 945 DC_HYB_iAktLV "Momentanwert: Strom vom DC/DC-Wandler in das Bordnetz";
CM_ SG_ 945 DC_HYB_iAktReserveLV "Momentanwert: Stromreserve vom DC/DC-Wandler in Richtung 12V-Bordnetz";
CM_ SG_ 945 DC_HYB_uAktLV "Momentanwert: NV-Bordnetzspannung am DC/DC-Wandler";
CM_ SG_ 945 DC_HYB_LangsRegelung "aktueller Regelmode des DC/DC-Wandlers.
0: normale Regelung
1: langsame Regelung";
CM_ SG_ 945 DC_HYB_Abregelung_Temperatur "Abregelung aufgrund Übertemperatur im Leistungsteil (Hochtemperatur-Abregelung)";
CM_ SG_ 945 DC_HYB_Fehler_RedLeistung "Fehler: eingeschränkte Leistungsfähigkeit des DC/DC-Wandlers aufgrund eines internen Fehlers";
CM_ SG_ 945 DC_HYB_Fehler_intern "Fehler: DC/DC-Wandler ist aufgrund eines internen Hardware-Fehlers abgeschaltet";
CM_ SG_ 945 DC_HYB_Fehler_Spannung "Abschaltung aufgrund Unter-/Überspannung auf der Ein-/Ausgangsseite";
CM_ SG_ 945 DC_HYB_Auslastungsgrad "Momentanwert: Auslastung DC/DC (DFM Signal), entspricht I_akt / I_max
(Vorhalt für MQB)";
CM_ SG_ 1714 DGN_Verlernzaehler "wrap around 254 --> 0";
CM_ SG_ 1714 KBI_Kilometerstand "Fehler wird ausgegeben, falls Kilometerstand nicht restaurierbar
";
CM_ SG_ 1714 UH_Monat "0x0D, 0xF =  Werte ungültig
0x0E = reserviert (nur VW)";
CM_ SG_ 1714 UH_Tag "0x0: reserviert bei VW";
CM_ SG_ 1714 UH_Stunde "0x18 - 0x1F = Werte ungültig";
CM_ SG_ 1714 UH_Minute "0x3C- 0x3f = Werte ungültig";
CM_ SG_ 1714 UH_Sekunde "0x3C- 0x3f = Werte ungültig";
CM_ SG_ 1714 Kombi_02_alt "Veraltet Bit für die Signale:

Botschaft Diagnose_01:
KBI_Kilometerstand";
CM_ SG_ 1714 Uhrzeit_01_alt "Veraltet Bit für die Signale:

Botschaft Diagnose_01:
UH_Jahr
UH_Monat
UH_Tag
UH_Stunde
";
CM_ BO_ 1520 "ab MQB nach abgestimmten FLH Dimmung";
CM_ SG_ 1520 DI_KL_58xd "Klemme 58xd Display- und Funktionsbeleuchtung
Mit der Klemme 58xd wird die Helligkeit der Display- und der Funktionsbeleuchtungen der Schalter gesteuert.
Im Detail beschrieben im 'Funktionslastenheft Dimmung MQB'.";
CM_ SG_ 1520 DI_KL_58xs "Suchbeleuchtung Schalter
EIN-AUS-Schaltalgorithmus der allgemeinen Schaltersuchbeleuchtung. 
Im Detail beschrieben im 'Funktionslastenheft Dimmung MQB'.
";
CM_ SG_ 1520 DI_Display_Nachtdesign "Für Displays sind oft  automatische Umschaltungen von Tag-/Nachtdesign vorgesehen.
Es gibt jedoch Zustände, an denen auch tagsüber das Abblendlicht eingeschaltet ist.
z.B. Dauerfahrlicht, Geschwindigkeitsabhängiges 'Licht-An-Bei-Autobahn', 'Regenlicht',";
CM_ SG_ 1520 DI_KL_58xt "Timergesteuerte Suchbeleuchtung
Der EIN-AUS-Schaltalgorithmus für die vor- und nachlaufende Schaltersuchbeleuchtungen beim Ein- & Aussteigen; z.B.: Start/Stop-Taster.
Im Detail beschrieben im 'Funktionslastenheft Dimmung MQB'.";
CM_ SG_ 1520 DI_Fotosensor "Helligkeitswert Fotosensor
Für die Dimmung relevanter Wert zur Sensierung der Umgebungshelligkeit
Im Detail beschrieben im 'Funktionslastenheft Dimmung MQB'.";
CM_ BO_ 1603 "MQB mit 8 Byte";
CM_ SG_ 1603 KBI_Einheit_Datum "Anzeigevariante des Datums";
CM_ SG_ 1603 KBI_Einheit_Druck "Einheit des Druckes";
CM_ SG_ 1603 KBI_Einheit_Streckenanz "Einheit der Streckenanzeige";
CM_ SG_ 1603 KBI_MFA_v_Einheit_02 "Einheit der Geschwindigkeit, die vom Fahrer im Car-Menü gewählt wurde. Veränderliche Grösse, im Gegensatz zur Einheit des Tachokranzes.

Redundant in der Einheiten_01 Botschaft definiert, um Konsistenz zur BAP-Festlegung zu haben.";
CM_ SG_ 1603 KBI_Einheit_Temp "Einheit der Temperatur";
CM_ SG_ 1603 KBI_Einheit_Uhrzeit "Anzeigevariante der Uhrzeit";
CM_ SG_ 1603 KBI_Einheit_Verbrauch "Einheit der Verbrauchs";
CM_ SG_ 1603 KBI_Einheit_Volumen "Einheit des Volumens";
CM_ SG_ 1603 KBI_Einheit_Sprache "Siehe BAP-Datenfestlegung UnitMaster";
CM_ BO_ 260 "ab MQB mit CRC-8";
CM_ SG_ 260 EPB_01_CRC "Für MLB:
Berechnung siehe Lastenheft 'Kommunikationsabsicherung für FlexRay und CAN''

Ab MQB und MLBevo:
Berechnung siehe Lastenheft 'End-to-End Kommunikationsabsicherung''

Endwerte siehe Begleitdokument 'S-PDU Kennungsfolgen'";
CM_ SG_ 260 EPB_QBit_Laengsbeschleunigung "Mitteilung z.Zt. für ACC, um unter bestimmten Zuständen mitzuteilen, daß Längsbeschleunigung temporär ungültig ist. Bsp.: Selbsttest Längsbeschleunigungssensor.";
CM_ SG_ 260 EPB_BCM2_Motor_Wakeup "EPB setzt dieses Bit, wenn EPB ein Nachwecken des ACAN fordert. Die Wakeup-Ursache des Car-Wakeup wird im NM high von den SG nicht ausgewertet, weswegen die Car-Wakeup-Information in einer konventionellen Applikationsbotschaft zum BCM2 gesendet werden. Da";
CM_ SG_ 260 EPB_Freig_Verzoeg_Anf "Verzögerungsanforderung	";
CM_ SG_ 260 EPB_Verzoeg_Anf "Steuerungsanforderung an andere Systeme (z.B. ESP), um während der Fahrt, durch den Handbremsschalter ausgelöst, zu bremsen (ECD-Funktion)";
CM_ SG_ 260 EPB_Laengsbeschleunigung "Längsbeschleunigungssignal (Sensor im AUDI D4 entfallen)
Achtung misst auch die Erdebeschleuinigung (stehend am Hang Wert !=0)

Entspricht bei kleinen Winkel dem Neigungswinkelsignal (<30%).

";
CM_ SG_ 260 EPB_Pedalweg_Kuppl "Signal entspricht Tastverhältnis des PWM. Gesamtweg Kupplungspedal 10% bis 90%, damit zu erwartende Werte 25 bis 225. 25 bei Kupplungspedal nicht getreten, 225 bei Kupplungspedal voll durchgetreten.
2% Toleranz wird im Wertebereich ermöglicht (8%-92%).
";
CM_ SG_ 260 EPB_Anfahrwunsch_erkannt "Nur im Colorado_NF zu verwenden: Die EPB zeigt mit diesem Signal einen erkannten Anfahrwunsch an. Das Signal kann genutzt werden um einem SG, welches ein Spannen über CAN anfordert (z.B. ESP-SG), mitzuteilen, dass ein Anfahrwunsch besteht und die EPB löse";
CM_ SG_ 260 EPB_DAA_Randbed_erf "Die Randbedingungen zum automatischen Öffnen der EPB (Funktion DAA) sind erfüllt und ein Betätigen des Fahrpedals führt zum Öffnen der EPB.";
CM_ SG_ 260 EPB_Schalterposition "Spiegelt die Schalterstellung wieder.

0x3 = Schalterfehler ";
CM_ SG_ 260 EPB_Konsistenz_ACC "EPB hat einen Fehler erkannt bzgl. der ACC-Botschaften (Timeout, BZ, CHK, DLC)";
CM_ SG_ 260 EPB_Spannkraft "Erzeugte Spannkraft. Bezieht sich auf die Aktuatoren.";
CM_ SG_ 260 EPB_Status "Gibt den Zustand der EPB-Aktuatoren an.

";
CM_ BO_ 257 "ab MQB wg. CRC8";
CM_ SG_ 257 ESP_02_CRC "Für MLB:
Berechnung siehe Lastenheft 'Kommunikationsabsicherung für FlexRay und CAN''

Ab MQB und MLBevo:
Berechnung siehe Lastenheft 'End-to-End Kommunikationsabsicherung''

Endwerte siehe Begleitdokument 'S-PDU Kennungsfolgen'";
CM_ SG_ 257 ESP_QBit_Gierrate "QBit der Gierrate. Gesetzt bei Ersatzwert, Init oder Fehler. 
";
CM_ SG_ 257 ESP_QBit_Laengsbeschl "QBit der Längsbeschleunigung. Gesetzt bei Ersatzwert, Init oder Fehler. 
";
CM_ SG_ 257 ESP_QBit_Querb "QBit der Querbeschleunigung. Gesetzt bei Ersatzwert, Init oder Fehler. ";
CM_ SG_ 257 ESP_Stillstandsflag "Bei RB-Projekten wird das Stillstandsflag gesetzt, wenn der absolute Stillstand der Raddrehzahlsensoren erkannt wurde, d.h. kein Zahn bewegt sich mehr. Dieses Bit wird bspw. im MOST für TV-Tuner-Abschaltung Australien verwendet, d.h. leichte Erschütterung";
CM_ SG_ 257 ESP_Querbeschleunigung "Beschleunigungswert in y-Achse

MLB: Gemessener Wert
0xFF = Fehler (wie bereits im Wertebereich spezifizert)
Bei ESP-Abschaltung durch modellgestützte Überwachung wird das Signal weiterhin ausgegeben.
Im AU64x und AU57x erfolgt die Bereitstellung der";
CM_ SG_ 257 ESP_Laengsbeschl "Beschleunigungswert in x-Achse

MLB: Im AU64x und AU57x erfolgt die Bereitstellung der Sensorwerte durch SARA-SG! Im AU64x und AU57x wird bei ESP-Abschaltung durch modellgestützte Überwachung das Signal weiterhin ausgegeben.

MQB: Sensorrohwert Längsb";
CM_ SG_ 257 ESP_Verteil_Wankmom "Anforderung einer Wankmomentenverteilung an CDC (Exklusivnutzung!)

-1...-0,1 = Fahrzeug untersteuernd (Anforderung Dämpfer vorne weich / hinten hart)
0 = Fahrzeug neutral, keine Dämpferansteuerung erforderlich
+0,1...+1 = Fahrzeug übersteuernd: Anfor";
CM_ SG_ 257 ESP_QBit_Anf_Vert_Wank "QBit der Wankmomentenverteilung. Gesetzt bei Ersatzwert, Init oder Fehler.";
CM_ SG_ 257 ESP_Gierrate "Winkelgeschwindigkeit um die z-Achse

MLB: gemessener Wert
tatsächliche Auflösung Bosch ESP: 0,27 Grad/s

Ab Au64x Auflösung wie die tatsächliche Skalierung 0,01. Im AU64x und AU57x wird bei ESP-Abschaltung durch modellgestützte Überwachung das Signa";
CM_ SG_ 257 ESP_VZ_Gierrate "Vorzeichen der Gierrate";
CM_ SG_ 257 ESP_Notbremsanzeige "ABS/ASR oder ESP hat Notbremssituation erkannt.
Weiterführende Informationen im Lastenheft spezifiziert und in der entsprechenden Fachabteilung zu erfragen.

";
CM_ SG_ 257 ESP_SpannungsAnf "Die Rekuperation kann mit der Anforderung einer höheren Spannung eingeschränkt werden.";
CM_ SG_ 257 ESP_PLA_Abbruch "Wenn der Bremseingriff abgebrochen wurde, wird in diesem Signal der Grund des Abbruchs dargestellt.
Dies ist nur gültig, wenn der Status ESP_Status_ESP_PLA = '0xA' ist.";
CM_ SG_ 257 ESP_Status_ESP_PLA "Zustand der Statusmaschine der Bremse für die korrespondierende Statusmaschien in dem PLA-SG";
BA_DEF_  "GenNWMApBusSleep" STRING ;
BA_DEF_  "GenNWMApCanNormal" STRING ;
BA_DEF_  "GenNWMApCanOff" STRING ;
BA_DEF_  "GenNWMApCanOn" STRING ;
BA_DEF_  "GenNWMApCanSleep" STRING ;
BA_DEF_  "GenNWMApCanWakeUp" STRING ;
BA_DEF_  "GenNWMGotoMode_Awake" STRING ;
BA_DEF_  "GenNWMGotoMode_BusSleep" STRING ;
BA_DEF_  "GenNWMSleepTime" INT 0 1000000;
BA_DEF_  "GenNWMTalkNM" STRING ;
BA_DEF_  "Manufacturer" STRING ;
BA_DEF_  "NmhBaseAddress" HEX 0 536870911;
BA_DEF_  "NmhMessageCount" INT 0 256;
BA_DEF_  "NmType" STRING ;
BA_DEF_  "VAGTP20_SetupMessageCount" INT 0 255;
BA_DEF_  "VAGTP20_SetupStartAddress" HEX 0 2047;
BA_DEF_  "VersionDay" INT 1 31;
BA_DEF_  "VersionMonth" INT 1 12;
BA_DEF_  "VersionWeek" INT 1 52;
BA_DEF_  "VersionYear" INT 0 99;
BA_DEF_  "VersionNumber" INT 0 65535;
BA_DEF_  "Baudrate" INT 0 1000000;
BA_DEF_  "SamplePointMin" INT 1 100;
BA_DEF_  "SamplePointMax" INT 1 100;
BA_DEF_  "SyncJumpWidthMin" INT 1 4;
BA_DEF_  "SyncJumpWidthMax" INT 1 4;
BA_DEF_  "NmhTimeoutTimer" INT 0 65535;
BA_DEF_  "NmhWaitBusSleepTimer" INT 0 65535;
BA_DEF_  "NmhPrepareBusSleepTimer" INT 0 65535;
BA_DEF_  "NmhLongTimer" INT 0 65535;
BA_DEF_  "NmhNStart" INT 0 255;
BA_DEF_ BU_  "GenNodAutoGenDsp" ENUM  "No","Yes";
BA_DEF_ BU_  "GenNodAutoGenSnd" ENUM  "No","Yes";
BA_DEF_ BU_  "GenNodSleepTime" INT 0 1000000;
BA_DEF_ BU_  "ILUsed" ENUM  "No","Yes";
BA_DEF_ BU_  "ECUVariantDefault" ENUM  "No","Yes";
BA_DEF_ BU_  "ECUVariantGroup" STRING ;
BA_DEF_ BU_  "NodeLayerModules" STRING ;
BA_DEF_ BU_  "NmhNode" ENUM  "No","Yes";
BA_DEF_ BU_  "NmNode" ENUM  "No","Yes";
BA_DEF_ BO_  "GenMsgPDUConstants" STRING ;
BA_DEF_ BO_  "GenMsgAutoGenDsp" ENUM  "No","Yes";
BA_DEF_ BO_  "GenMsgAutoGenSnd" ENUM  "No","Yes";
BA_DEF_ BO_  "GenMsgCycleTime" INT 0 65535;
BA_DEF_ BO_  "GenMsgCycleTimeFast" INT 0 65535;
BA_DEF_ BO_  "GenMsgDelayTime" INT 0 100000;
BA_DEF_ BO_  "GenMsgILSupport" ENUM  "No","Yes";
BA_DEF_ BO_  "GenMsgNrOfRepetition" INT 0 100;
BA_DEF_ BO_  "GenMsgSendType" ENUM  "Cyclic","not_used","not_used","not_used","not_used","not_used","not_used","IfActive","NoMsgSendType";
BA_DEF_ BO_  "GenMsgStartDelayTime" INT 0 100000;
BA_DEF_ BO_  "NmMessage" ENUM  "No","Yes";
BA_DEF_ BO_  "NmhMessage" ENUM  "No","Yes";
BA_DEF_ BO_  "VAGTP20_API" HEX 0 255;
BA_DEF_ BO_  "VAGTP20_DynConnection" ENUM  "No","Yes";
BA_DEF_ BO_  "VAGTP20_DynSetup" ENUM  "No","Yes";
BA_DEF_ BO_  "VAGTP20_StatConnection" ENUM  "No","Yes";
BA_DEF_ BO_  "Timeoutzeit" INT 0 1000000;
BA_DEF_ BO_  "DiagRequest" ENUM  "No","Yes";
BA_DEF_ BO_  "DiagResponse" ENUM  "No","Yes";
BA_DEF_ BO_  "DiagState" ENUM  "No","Yes";
BA_DEF_ BO_  "GenMsgChkConstant" HEX 0 4095;
BA_DEF_ SG_  "GenSigAutoGenDsp" ENUM  "No","Yes";
BA_DEF_ SG_  "GenSigAutoGenSnd" ENUM  "No","Yes";
BA_DEF_ SG_  "GenSigEnvVarType" ENUM  "int","float","undef";
BA_DEF_ SG_  "GenSigInactiveValue" INT -2147483648 2147483647;
BA_DEF_ SG_  "GenSigSendType" ENUM  "Cyclic","OnWrite","OnWriteWithRepetition","OnChange","OnChangeWithRepetition","IfActive","IfActiveWithRepetition","NoSigSendType","OnChangeAndIfActive","OnChangeAndIfActiveWithRepetition";
BA_DEF_ SG_  "GenSigStartValue" INT -2147483648 2147483647;
BA_DEF_ SG_  "NWM-WakeupAllowed" ENUM  "No","Yes";
BA_DEF_ SG_  "GenSigFuncType" ENUM  "NoFunction","MsgCounter","CRC-8","XOR","XOR-2","DatedBit","SW-Kl15","CHK","Constant","Protocol";
BA_DEF_ SG_  "GenSigSwitchedByIgnition" ENUM  "No","Yes";
BA_DEF_ SG_  "Fehlerwert" HEX 0 2147483647;
BA_DEF_ SG_  "GenSigMissingSourceValue" HEX 0 2147483647;
BA_DEF_REL_ BU_SG_REL_  "GenSigTimeoutTime" INT 0 65535;
BA_DEF_DEF_  "GenNWMApBusSleep" "";
BA_DEF_DEF_  "GenNWMApCanNormal" "";
BA_DEF_DEF_  "GenNWMApCanOff" "";
BA_DEF_DEF_  "GenNWMApCanOn" "";
BA_DEF_DEF_  "GenNWMApCanSleep" "";
BA_DEF_DEF_  "GenNWMApCanWakeUp" "";
BA_DEF_DEF_  "GenNWMGotoMode_Awake" "";
BA_DEF_DEF_  "GenNWMGotoMode_BusSleep" "";
BA_DEF_DEF_  "GenNWMSleepTime" 0;
BA_DEF_DEF_  "GenNWMTalkNM" "";
BA_DEF_DEF_  "Manufacturer" "";
BA_DEF_DEF_  "NmhBaseAddress" 0;
BA_DEF_DEF_  "NmhMessageCount" 1;
BA_DEF_DEF_  "NmType" "None";
BA_DEF_DEF_  "VAGTP20_SetupMessageCount" 0;
BA_DEF_DEF_  "VAGTP20_SetupStartAddress" 0;
BA_DEF_DEF_  "VersionDay" 28;
BA_DEF_DEF_  "VersionMonth" 1;
BA_DEF_DEF_  "VersionWeek" 4;
BA_DEF_DEF_  "VersionYear" 10;
BA_DEF_DEF_  "VersionNumber" 0;
BA_DEF_DEF_  "Baudrate" 0;
BA_DEF_DEF_  "SamplePointMin" 1;
BA_DEF_DEF_  "SamplePointMax" 1;
BA_DEF_DEF_  "SyncJumpWidthMin" 1;
BA_DEF_DEF_  "SyncJumpWidthMax" 1;
BA_DEF_DEF_  "NmhTimeoutTimer" 0;
BA_DEF_DEF_  "NmhWaitBusSleepTimer" 0;
BA_DEF_DEF_  "NmhPrepareBusSleepTimer" 0;
BA_DEF_DEF_  "NmhLongTimer" 0;
BA_DEF_DEF_  "NmhNStart" 0;
BA_DEF_DEF_  "GenNodAutoGenDsp" "Yes";
BA_DEF_DEF_  "GenNodAutoGenSnd" "Yes";
BA_DEF_DEF_  "GenNodSleepTime" 0;
BA_DEF_DEF_  "ILUsed" "Yes";
BA_DEF_DEF_  "ECUVariantDefault" "Yes";
BA_DEF_DEF_  "ECUVariantGroup" "";
BA_DEF_DEF_  "NodeLayerModules" "";
BA_DEF_DEF_  "NmhNode" "Yes";
BA_DEF_DEF_  "NmNode" "No";
BA_DEF_DEF_  "GenMsgPDUConstants" "";
BA_DEF_DEF_  "GenMsgAutoGenDsp" "Yes";
BA_DEF_DEF_  "GenMsgAutoGenSnd" "Yes";
BA_DEF_DEF_  "GenMsgCycleTime" 0;
BA_DEF_DEF_  "GenMsgCycleTimeFast" 0;
BA_DEF_DEF_  "GenMsgDelayTime" 0;
BA_DEF_DEF_  "GenMsgILSupport" "No";
BA_DEF_DEF_  "GenMsgNrOfRepetition" 0;
BA_DEF_DEF_  "GenMsgSendType" "NoMsgSendType";
BA_DEF_DEF_  "GenMsgStartDelayTime" 0;
BA_DEF_DEF_  "NmMessage" "No";
BA_DEF_DEF_  "NmhMessage" "No";
BA_DEF_DEF_  "VAGTP20_API" 0;
BA_DEF_DEF_  "VAGTP20_DynConnection" "No";
BA_DEF_DEF_  "VAGTP20_DynSetup" "No";
BA_DEF_DEF_  "VAGTP20_StatConnection" "No";
BA_DEF_DEF_  "Timeoutzeit" 0;
BA_DEF_DEF_  "DiagRequest" "No";
BA_DEF_DEF_  "DiagResponse" "No";
BA_DEF_DEF_  "DiagState" "No";
BA_DEF_DEF_  "GenMsgChkConstant" 0;
BA_DEF_DEF_  "GenSigAutoGenDsp" "No";
BA_DEF_DEF_  "GenSigAutoGenSnd" "No";
BA_DEF_DEF_  "GenSigEnvVarType" "undef";
BA_DEF_DEF_  "GenSigInactiveValue" 0;
BA_DEF_DEF_  "GenSigSendType" "NoSigSendType";
BA_DEF_DEF_  "GenSigStartValue" 0;
BA_DEF_DEF_  "NWM-WakeupAllowed" "No";
BA_DEF_DEF_  "GenSigFuncType" "NoFunction";
BA_DEF_DEF_  "GenSigSwitchedByIgnition" "Yes";
BA_DEF_DEF_  "Fehlerwert" 0;
BA_DEF_DEF_  "GenSigMissingSourceValue" 0;
BA_DEF_DEF_REL_ "GenSigTimeoutTime" 0;
BA_ "NmhNStart" 20;
BA_ "NmhLongTimer" 200;
BA_ "NmhPrepareBusSleepTimer" 500;
BA_ "NmhWaitBusSleepTimer" 750;
BA_ "NmhTimeoutTimer" 1000;
BA_ "SyncJumpWidthMax" 3;
BA_ "SamplePointMax" 84;
BA_ "SamplePointMin" 80;
BA_ "Baudrate" 500000;
BA_ "VersionNumber" 4;
BA_ "VAGTP20_SetupStartAddress" 512;
BA_ "VAGTP20_SetupMessageCount" 128;
BA_ "NmType" "NM-High";
BA_ "NmhMessageCount" 256;
BA_ "NmhBaseAddress" 452984832;
BA_ "Manufacturer" "VAG";
BA_ "GenNWMTalkNM" "Nmh_ReqNetOn()";
BA_ "GenNWMSleepTime" 4000;
BA_ "GenNWMGotoMode_BusSleep" "Nmh_ReqNetOff()";
BA_ "GenNWMGotoMode_Awake" "Nmh_ReqNetOn()";
BA_ "GenNWMApCanWakeUp" "apCanWakeUp()";
BA_ "GenNWMApCanSleep" "apCanSleep()";
BA_ "GenNWMApCanOn" "NMIndnetOn()";
BA_ "GenNWMApCanOff" "NMIndnetOff()";
BA_ "GenNWMApCanNormal" "apCanNormal()";
BA_ "GenNWMApBusSleep" "NMIndNetSDN()";
BA_ "NodeLayerModules" BU_ Airbag_MQB "NMHigh.DLL";
BA_ "ECUVariantGroup" BU_ Airbag_MQB "Airbag";
BA_ "NmhNode" BU_ BAP_Tester_MQB 0;
BA_ "ECUVariantGroup" BU_ BAP_Tester_MQB "BAP";
BA_ "NodeLayerModules" BU_ BMS_MQB "NMHigh.DLL";
BA_ "ECUVariantGroup" BU_ BMS_MQB "BMS";
BA_ "GenNodSleepTime" BU_ BMS_MQB 4000;
BA_ "NmhNode" BU_ Datenlogger_MQB 0;
BA_ "ECUVariantGroup" BU_ Datenlogger_MQB "Datenlogger";
BA_ "NodeLayerModules" BU_ Gateway_MQB "NMHigh.DLL";
BA_ "ECUVariantGroup" BU_ Gateway_MQB "Gateway";
BA_ "GenNodSleepTime" BU_ Gateway_MQB 4000;
BA_ "NodeLayerModules" BU_ Getriebe_DQ_Hybrid_MQB "NMHigh.DLL";
BA_ "ECUVariantGroup" BU_ Getriebe_DQ_Hybrid_MQB "Getriebe";
BA_ "ECUVariantDefault" BU_ Getriebe_DQ_Hybrid_MQB 0;
BA_ "GenNodSleepTime" BU_ Getriebe_DQ_Hybrid_MQB 4000;
BA_ "NodeLayerModules" BU_ Getriebe_DQ_MQB "NMHigh.DLL";
BA_ "ECUVariantGroup" BU_ Getriebe_DQ_MQB "Getriebe";
BA_ "GenNodSleepTime" BU_ Getriebe_DQ_MQB 4000;
BA_ "NodeLayerModules" BU_ LEH_MQB "NMHigh.DLL";
BA_ "ECUVariantGroup" BU_ LEH_MQB "EMotor";
BA_ "ECUVariantDefault" BU_ LEH_MQB 0;
BA_ "GenNodSleepTime" BU_ LEH_MQB 4000;
BA_ "NodeLayerModules" BU_ Motor_Diesel_MQB "NMHigh.DLL";
BA_ "ECUVariantGroup" BU_ Motor_Diesel_MQB "Motor";
BA_ "GenNodSleepTime" BU_ Motor_Diesel_MQB 4000;
BA_ "NodeLayerModules" BU_ Motor_Hybrid_MQB "NMHigh.DLL";
BA_ "ECUVariantGroup" BU_ Motor_Hybrid_MQB "Motor";
BA_ "ECUVariantDefault" BU_ Motor_Hybrid_MQB 0;
BA_ "GenNodSleepTime" BU_ Motor_Hybrid_MQB 4000;
BA_ "NodeLayerModules" BU_ Motor_Otto_MQB "NMHigh.DLL";
BA_ "ECUVariantGroup" BU_ Motor_Otto_MQB "Motor";
BA_ "ECUVariantDefault" BU_ Motor_Otto_MQB 0;
BA_ "GenNodSleepTime" BU_ Motor_Otto_MQB 4000;
BA_ "NmhNode" BU_ SAK_MQB 0;
BA_ "ECUVariantGroup" BU_ SAK_MQB "SAK";
BA_ "GenNodSleepTime" BU_ SAK_MQB 4000;
BA_ "NmhNode" BU_ Waehlhebel_MQB 0;
BA_ "ECUVariantGroup" BU_ Waehlhebel_MQB "Waehlhebel";
BA_ "GenMsgPDUConstants" BO_ 290 "0x37,0x7d,0xf3,0xa9,0x18,0x46,0x6d,0x4d,0x3d,0x71,0x92,0x9c,0xe5,0x32,0x10,0xb9";
BA_ "GenMsgChkConstant" BO_ 290 8;
BA_ "GenMsgSendType" BO_ 290 0;
BA_ "GenMsgILSupport" BO_ 290 1;
BA_ "GenMsgCycleTime" BO_ 290 20;
BA_ "GenMsgPDUConstants" BO_ 279 "0x16,0x16,0x16,0x16,0x16,0x16,0x16,0x16,0x16,0x16,0x16,0x16,0x16,0x16,0x16,0x16";
BA_ "GenMsgChkConstant" BO_ 279 22;
BA_ "GenMsgSendType" BO_ 279 0;
BA_ "GenMsgILSupport" BO_ 279 1;
BA_ "GenMsgCycleTime" BO_ 279 20;
BA_ "GenMsgPDUConstants" BO_ 64 "0x40,0x40,0x40,0x40,0x40,0x40,0x40,0x40,0x40,0x40,0x40,0x40,0x40,0x40,0x40,0x40";
BA_ "GenMsgChkConstant" BO_ 64 64;
BA_ "GenMsgSendType" BO_ 64 0;
BA_ "GenMsgILSupport" BO_ 64 1;
BA_ "GenMsgDelayTime" BO_ 64 10;
BA_ "GenMsgCycleTime" BO_ 64 50;
BA_ "GenMsgSendType" BO_ 1312 0;
BA_ "GenMsgILSupport" BO_ 1312 1;
BA_ "GenMsgCycleTime" BO_ 1312 200;
BA_ "GenMsgNrOfRepetition" BO_ 65 5;
BA_ "GenMsgCycleTimeFast" BO_ 65 10;
BA_ "GenMsgPDUConstants" BO_ 65 "0x93,0xb0,0x9d,0xf1,0x09,0xe8,0x88,0x5e,0x36,0xfa,0xa8,0xa1,0x67,0x84,0xca,0x4f";
BA_ "GenMsgSendType" BO_ 65 0;
BA_ "GenMsgILSupport" BO_ 65 1;
BA_ "GenMsgDelayTime" BO_ 65 10;
BA_ "GenMsgCycleTime" BO_ 65 1000;
BA_ "GenMsgSendType" BO_ 1633 0;
BA_ "GenMsgILSupport" BO_ 1633 1;
BA_ "GenMsgCycleTime" BO_ 1633 100;
BA_ "GenMsgAutoGenSnd" BO_ 2536767264 0;
BA_ "GenMsgAutoGenDsp" BO_ 2536767264 0;
BA_ "GenMsgAutoGenSnd" BO_ 2536767280 0;
BA_ "GenMsgAutoGenDsp" BO_ 2536767280 0;
BA_ "GenMsgSendType" BO_ 2536709120 7;
BA_ "GenMsgAutoGenSnd" BO_ 2536709120 0;
BA_ "GenMsgAutoGenDsp" BO_ 2536709120 0;
BA_ "GenMsgSendType" BO_ 2536709121 7;
BA_ "GenMsgAutoGenSnd" BO_ 2536709121 0;
BA_ "GenMsgAutoGenDsp" BO_ 2536709121 0;
BA_ "GenMsgSendType" BO_ 2536709136 7;
BA_ "GenMsgAutoGenSnd" BO_ 2536709136 0;
BA_ "GenMsgAutoGenDsp" BO_ 2536709136 0;
BA_ "GenMsgSendType" BO_ 2536709888 7;
BA_ "GenMsgAutoGenSnd" BO_ 2536709888 0;
BA_ "GenMsgAutoGenDsp" BO_ 2536709888 0;
BA_ "GenMsgSendType" BO_ 2536709904 7;
BA_ "GenMsgAutoGenSnd" BO_ 2536709904 0;
BA_ "GenMsgAutoGenDsp" BO_ 2536709904 0;
BA_ "GenMsgSendType" BO_ 1626 0;
BA_ "GenMsgILSupport" BO_ 1626 1;
BA_ "GenMsgDelayTime" BO_ 1626 100;
BA_ "GenMsgCycleTime" BO_ 1626 1000;
BA_ "GenMsgSendType" BO_ 869 0;
BA_ "GenMsgILSupport" BO_ 869 1;
BA_ "GenMsgCycleTime" BO_ 869 50;
BA_ "GenMsgSendType" BO_ 1628 0;
BA_ "GenMsgILSupport" BO_ 1628 1;
BA_ "GenMsgCycleTime" BO_ 1628 500;
BA_ "GenMsgSendType" BO_ 901 0;
BA_ "GenMsgILSupport" BO_ 901 1;
BA_ "GenMsgDelayTime" BO_ 901 20;
BA_ "GenMsgCycleTime" BO_ 901 1000;
BA_ "Timeoutzeit" BO_ 945 1000;
BA_ "GenMsgSendType" BO_ 945 0;
BA_ "GenMsgILSupport" BO_ 945 1;
BA_ "GenMsgCycleTime" BO_ 945 100;
BA_ "GenMsgSendType" BO_ 1714 0;
BA_ "GenMsgILSupport" BO_ 1714 1;
BA_ "GenMsgCycleTime" BO_ 1714 1000;
BA_ "GenMsgSendType" BO_ 1520 0;
BA_ "GenMsgILSupport" BO_ 1520 1;
BA_ "GenMsgDelayTime" BO_ 1520 50;
BA_ "GenMsgCycleTime" BO_ 1520 200;
BA_ "GenMsgSendType" BO_ 1603 0;
BA_ "GenMsgILSupport" BO_ 1603 1;
BA_ "GenMsgDelayTime" BO_ 1603 100;
BA_ "GenMsgCycleTime" BO_ 1603 1000;
BA_ "GenMsgPDUConstants" BO_ 260 "0x05,0x05,0x05,0x05,0x05,0x05,0x05,0x05,0x05,0x05,0x05,0x05,0x05,0x05,0x05,0x05";
BA_ "GenMsgChkConstant" BO_ 260 5;
BA_ "GenMsgSendType" BO_ 260 0;
BA_ "GenMsgILSupport" BO_ 260 1;
BA_ "GenMsgCycleTime" BO_ 260 20;
BA_ "GenMsgPDUConstants" BO_ 257 "0xaa,0xaa,0xaa,0xaa,0xaa,0xaa,0xaa,0xaa,0xaa,0xaa,0xaa,0xaa,0xaa,0xaa,0xaa,0xaa";
BA_ "GenMsgChkConstant" BO_ 257 170;
BA_ "GenMsgSendType" BO_ 257 0;
BA_ "GenMsgILSupport" BO_ 257 1;
BA_ "GenMsgCycleTime" BO_ 257 20;
BA_ "GenSigFuncType" SG_ 290 ACC_06_CRC 2;
BA_ "GenSigSendType" SG_ 290 ACC_06_CRC 0;
BA_ "GenSigEnvVarType" SG_ 290 ACC_06_CRC 0;
BA_ "GenSigAutoGenSnd" SG_ 290 ACC_06_CRC 1;
BA_ "GenSigAutoGenDsp" SG_ 290 ACC_06_CRC 1;
BA_ "GenSigFuncType" SG_ 290 ACC_06_BZ 1;
BA_ "GenSigSendType" SG_ 290 ACC_06_BZ 0;
BA_ "GenSigEnvVarType" SG_ 290 ACC_06_BZ 0;
BA_ "GenSigAutoGenSnd" SG_ 290 ACC_06_BZ 1;
BA_ "GenSigAutoGenDsp" SG_ 290 ACC_06_BZ 1;
BA_ "GenSigSendType" SG_ 290 ACC_limitierte_Anfahrdyn 0;
BA_ "GenSigAutoGenSnd" SG_ 290 ACC_limitierte_Anfahrdyn 1;
BA_ "GenSigAutoGenDsp" SG_ 290 ACC_limitierte_Anfahrdyn 1;
BA_ "GenSigSendType" SG_ 290 ACC_zul_Regelabw_unten 0;
BA_ "GenSigEnvVarType" SG_ 290 ACC_zul_Regelabw_unten 1;
BA_ "GenSigAutoGenSnd" SG_ 290 ACC_zul_Regelabw_unten 1;
BA_ "GenSigAutoGenDsp" SG_ 290 ACC_zul_Regelabw_unten 1;
BA_ "GenSigSendType" SG_ 290 ACC_StartStopp_Info 0;
BA_ "GenSigAutoGenSnd" SG_ 290 ACC_StartStopp_Info 1;
BA_ "GenSigAutoGenDsp" SG_ 290 ACC_StartStopp_Info 1;
BA_ "Fehlerwert" SG_ 290 ACC_Sollbeschleunigung_02 2047;
BA_ "GenSigStartValue" SG_ 290 ACC_Sollbeschleunigung_02 2046;
BA_ "GenSigSendType" SG_ 290 ACC_Sollbeschleunigung_02 0;
BA_ "GenSigEnvVarType" SG_ 290 ACC_Sollbeschleunigung_02 1;
BA_ "GenSigAutoGenSnd" SG_ 290 ACC_Sollbeschleunigung_02 1;
BA_ "GenSigAutoGenDsp" SG_ 290 ACC_Sollbeschleunigung_02 1;
BA_ "GenSigSendType" SG_ 290 ACC_zul_Regelabw_oben 0;
BA_ "GenSigEnvVarType" SG_ 290 ACC_zul_Regelabw_oben 1;
BA_ "GenSigAutoGenSnd" SG_ 290 ACC_zul_Regelabw_oben 1;
BA_ "GenSigAutoGenDsp" SG_ 290 ACC_zul_Regelabw_oben 1;
BA_ "GenSigSendType" SG_ 290 ACC_neg_Sollbeschl_Grad_02 0;
BA_ "GenSigEnvVarType" SG_ 290 ACC_neg_Sollbeschl_Grad_02 1;
BA_ "GenSigAutoGenSnd" SG_ 290 ACC_neg_Sollbeschl_Grad_02 1;
BA_ "GenSigAutoGenDsp" SG_ 290 ACC_neg_Sollbeschl_Grad_02 1;
BA_ "GenSigSendType" SG_ 290 ACC_pos_Sollbeschl_Grad_02 0;
BA_ "GenSigEnvVarType" SG_ 290 ACC_pos_Sollbeschl_Grad_02 1;
BA_ "GenSigAutoGenSnd" SG_ 290 ACC_pos_Sollbeschl_Grad_02 1;
BA_ "GenSigAutoGenDsp" SG_ 290 ACC_pos_Sollbeschl_Grad_02 1;
BA_ "GenSigSendType" SG_ 290 ACC_Anfahren 0;
BA_ "GenSigAutoGenSnd" SG_ 290 ACC_Anfahren 1;
BA_ "GenSigAutoGenDsp" SG_ 290 ACC_Anfahren 1;
BA_ "GenSigSendType" SG_ 290 ACC_Anhalten 0;
BA_ "GenSigEnvVarType" SG_ 290 ACC_Anhalten 0;
BA_ "GenSigAutoGenSnd" SG_ 290 ACC_Anhalten 1;
BA_ "GenSigAutoGenDsp" SG_ 290 ACC_Anhalten 1;
BA_ "GenSigFuncType" SG_ 290 ACC_Typ 8;
BA_ "GenSigSendType" SG_ 290 ACC_Typ 0;
BA_ "GenSigAutoGenSnd" SG_ 290 ACC_Typ 1;
BA_ "GenSigAutoGenDsp" SG_ 290 ACC_Typ 1;
BA_ "GenSigSendType" SG_ 290 ACC_Status_ACC 0;
BA_ "GenSigEnvVarType" SG_ 290 ACC_Status_ACC 0;
BA_ "GenSigAutoGenSnd" SG_ 290 ACC_Status_ACC 1;
BA_ "GenSigAutoGenDsp" SG_ 290 ACC_Status_ACC 1;
BA_ "GenSigSendType" SG_ 290 ACC_Minimale_Bremsung 0;
BA_ "GenSigEnvVarType" SG_ 290 ACC_Minimale_Bremsung 0;
BA_ "GenSigAutoGenSnd" SG_ 290 ACC_Minimale_Bremsung 1;
BA_ "GenSigAutoGenDsp" SG_ 290 ACC_Minimale_Bremsung 1;
BA_ "GenSigFuncType" SG_ 279 ACC_10_CRC 2;
BA_ "GenSigSendType" SG_ 279 ACC_10_CRC 0;
BA_ "GenSigEnvVarType" SG_ 279 ACC_10_CRC 0;
BA_ "GenSigAutoGenSnd" SG_ 279 ACC_10_CRC 1;
BA_ "GenSigAutoGenDsp" SG_ 279 ACC_10_CRC 1;
BA_ "GenSigFuncType" SG_ 279 ACC_10_BZ 1;
BA_ "GenSigSendType" SG_ 279 ACC_10_BZ 0;
BA_ "GenSigEnvVarType" SG_ 279 ACC_10_BZ 0;
BA_ "GenSigAutoGenSnd" SG_ 279 ACC_10_BZ 1;
BA_ "GenSigAutoGenDsp" SG_ 279 ACC_10_BZ 1;
BA_ "GenSigSendType" SG_ 279 AWV1_Anf_Prefill 0;
BA_ "GenSigEnvVarType" SG_ 279 AWV1_Anf_Prefill 0;
BA_ "GenSigAutoGenSnd" SG_ 279 AWV1_Anf_Prefill 1;
BA_ "GenSigAutoGenDsp" SG_ 279 AWV1_Anf_Prefill 1;
BA_ "GenSigSwitchedByIgnition" SG_ 279 ANB_CM_Info 0;
BA_ "GenSigSendType" SG_ 279 ANB_CM_Info 0;
BA_ "GenSigSendType" SG_ 279 AWV2_Freigabe 0;
BA_ "GenSigEnvVarType" SG_ 279 AWV2_Freigabe 0;
BA_ "GenSigAutoGenSnd" SG_ 279 AWV2_Freigabe 1;
BA_ "GenSigAutoGenDsp" SG_ 279 AWV2_Freigabe 1;
BA_ "GenSigSendType" SG_ 279 AWV1_HBA_Param 0;
BA_ "GenSigEnvVarType" SG_ 279 AWV1_HBA_Param 0;
BA_ "GenSigAutoGenSnd" SG_ 279 AWV1_HBA_Param 1;
BA_ "GenSigAutoGenDsp" SG_ 279 AWV1_HBA_Param 1;
BA_ "GenSigSendType" SG_ 279 AWV2_Ruckprofil 0;
BA_ "GenSigEnvVarType" SG_ 279 AWV2_Ruckprofil 0;
BA_ "GenSigAutoGenSnd" SG_ 279 AWV2_Ruckprofil 1;
BA_ "GenSigAutoGenDsp" SG_ 279 AWV2_Ruckprofil 1;
BA_ "GenSigSendType" SG_ 279 AWV2_Priowarnung 0;
BA_ "GenSigEnvVarType" SG_ 279 AWV2_Priowarnung 0;
BA_ "GenSigAutoGenSnd" SG_ 279 AWV2_Priowarnung 1;
BA_ "GenSigAutoGenDsp" SG_ 279 AWV2_Priowarnung 1;
BA_ "GenSigSendType" SG_ 279 ANB_CM_Anforderung 0;
BA_ "GenSigAutoGenSnd" SG_ 279 ANB_CM_Anforderung 1;
BA_ "GenSigAutoGenDsp" SG_ 279 ANB_CM_Anforderung 1;
BA_ "GenSigSendType" SG_ 279 ANB_Info_Teilbremsung 0;
BA_ "GenSigAutoGenSnd" SG_ 279 ANB_Info_Teilbremsung 1;
BA_ "GenSigAutoGenDsp" SG_ 279 ANB_Info_Teilbremsung 1;
BA_ "GenSigSendType" SG_ 279 ANB_Notfallblinken 0;
BA_ "GenSigAutoGenSnd" SG_ 279 ANB_Notfallblinken 1;
BA_ "GenSigAutoGenDsp" SG_ 279 ANB_Notfallblinken 1;
BA_ "GenSigSendType" SG_ 279 ANB_Teilbremsung_Freigabe 0;
BA_ "GenSigAutoGenSnd" SG_ 279 ANB_Teilbremsung_Freigabe 1;
BA_ "GenSigAutoGenDsp" SG_ 279 ANB_Teilbremsung_Freigabe 1;
BA_ "GenSigStartValue" SG_ 279 ANB_Zielbrems_Teilbrems_Verz_Anf 834;
BA_ "GenSigSendType" SG_ 279 ANB_Zielbrems_Teilbrems_Verz_Anf 0;
BA_ "GenSigAutoGenSnd" SG_ 279 ANB_Zielbrems_Teilbrems_Verz_Anf 1;
BA_ "GenSigAutoGenDsp" SG_ 279 ANB_Zielbrems_Teilbrems_Verz_Anf 1;
BA_ "GenSigSendType" SG_ 279 ANB_Zielbremsung_Freigabe 0;
BA_ "GenSigAutoGenSnd" SG_ 279 ANB_Zielbremsung_Freigabe 1;
BA_ "GenSigAutoGenDsp" SG_ 279 ANB_Zielbremsung_Freigabe 1;
BA_ "GenSigSendType" SG_ 279 AWV_Vorstufe 0;
BA_ "GenSigAutoGenSnd" SG_ 279 AWV_Vorstufe 1;
BA_ "GenSigAutoGenDsp" SG_ 279 AWV_Vorstufe 1;
BA_ "GenSigSendType" SG_ 279 AWV_Halten 0;
BA_ "GenSigFuncType" SG_ 64 Airbag_01_CRC 2;
BA_ "GenSigSendType" SG_ 64 Airbag_01_CRC 0;
BA_ "GenSigEnvVarType" SG_ 64 Airbag_01_CRC 0;
BA_ "GenSigAutoGenSnd" SG_ 64 Airbag_01_CRC 1;
BA_ "GenSigAutoGenDsp" SG_ 64 Airbag_01_CRC 1;
BA_ "GenSigFuncType" SG_ 64 Airbag_01_BZ 1;
BA_ "GenSigSendType" SG_ 64 Airbag_01_BZ 0;
BA_ "GenSigEnvVarType" SG_ 64 Airbag_01_BZ 0;
BA_ "GenSigAutoGenSnd" SG_ 64 Airbag_01_BZ 1;
BA_ "GenSigAutoGenDsp" SG_ 64 Airbag_01_BZ 1;
BA_ "GenSigStartValue" SG_ 64 AB_RGS_Anst 8;
BA_ "GenSigSendType" SG_ 64 AB_RGS_Anst 3;
BA_ "GenSigEnvVarType" SG_ 64 AB_RGS_Anst 0;
BA_ "GenSigAutoGenSnd" SG_ 64 AB_RGS_Anst 1;
BA_ "GenSigAutoGenDsp" SG_ 64 AB_RGS_Anst 1;
BA_ "GenSigSendType" SG_ 64 AB_Front_Crash 3;
BA_ "GenSigEnvVarType" SG_ 64 AB_Front_Crash 0;
BA_ "GenSigAutoGenSnd" SG_ 64 AB_Front_Crash 1;
BA_ "GenSigAutoGenDsp" SG_ 64 AB_Front_Crash 1;
BA_ "GenSigSendType" SG_ 64 AB_Heck_Crash 3;
BA_ "GenSigEnvVarType" SG_ 64 AB_Heck_Crash 0;
BA_ "GenSigAutoGenSnd" SG_ 64 AB_Heck_Crash 1;
BA_ "GenSigAutoGenDsp" SG_ 64 AB_Heck_Crash 1;
BA_ "GenSigSendType" SG_ 64 AB_SF_Crash 3;
BA_ "GenSigEnvVarType" SG_ 64 AB_SF_Crash 0;
BA_ "GenSigAutoGenSnd" SG_ 64 AB_SF_Crash 1;
BA_ "GenSigAutoGenDsp" SG_ 64 AB_SF_Crash 1;
BA_ "GenSigSendType" SG_ 64 AB_SB_Crash 3;
BA_ "GenSigEnvVarType" SG_ 64 AB_SB_Crash 0;
BA_ "GenSigAutoGenSnd" SG_ 64 AB_SB_Crash 1;
BA_ "GenSigAutoGenDsp" SG_ 64 AB_SB_Crash 1;
BA_ "GenSigSendType" SG_ 64 AB_Rollover_Crash 3;
BA_ "GenSigEnvVarType" SG_ 64 AB_Rollover_Crash 0;
BA_ "GenSigAutoGenSnd" SG_ 64 AB_Rollover_Crash 1;
BA_ "GenSigAutoGenDsp" SG_ 64 AB_Rollover_Crash 1;
BA_ "GenSigSendType" SG_ 64 AB_Crash_Int 3;
BA_ "GenSigEnvVarType" SG_ 64 AB_Crash_Int 0;
BA_ "GenSigAutoGenSnd" SG_ 64 AB_Crash_Int 1;
BA_ "GenSigAutoGenDsp" SG_ 64 AB_Crash_Int 1;
BA_ "GenSigStartValue" SG_ 64 AB_Lampe 1;
BA_ "GenSigSendType" SG_ 64 AB_Lampe 0;
BA_ "GenSigEnvVarType" SG_ 64 AB_Lampe 0;
BA_ "GenSigAutoGenSnd" SG_ 64 AB_Lampe 1;
BA_ "GenSigAutoGenDsp" SG_ 64 AB_Lampe 1;
BA_ "GenSigSendType" SG_ 64 AB_Deaktiviert 0;
BA_ "GenSigEnvVarType" SG_ 64 AB_Deaktiviert 0;
BA_ "GenSigAutoGenSnd" SG_ 64 AB_Deaktiviert 1;
BA_ "GenSigAutoGenDsp" SG_ 64 AB_Deaktiviert 1;
BA_ "GenSigStartValue" SG_ 64 AB_VB_deaktiviert 1;
BA_ "GenSigSendType" SG_ 64 AB_VB_deaktiviert 0;
BA_ "GenSigEnvVarType" SG_ 64 AB_VB_deaktiviert 0;
BA_ "GenSigAutoGenSnd" SG_ 64 AB_VB_deaktiviert 1;
BA_ "GenSigAutoGenDsp" SG_ 64 AB_VB_deaktiviert 1;
BA_ "GenSigSendType" SG_ 64 AB_Systemfehler 0;
BA_ "GenSigEnvVarType" SG_ 64 AB_Systemfehler 0;
BA_ "GenSigAutoGenSnd" SG_ 64 AB_Systemfehler 1;
BA_ "GenSigAutoGenDsp" SG_ 64 AB_Systemfehler 1;
BA_ "GenSigSendType" SG_ 64 AB_Diagnose 0;
BA_ "GenSigEnvVarType" SG_ 64 AB_Diagnose 0;
BA_ "GenSigAutoGenSnd" SG_ 64 AB_Diagnose 1;
BA_ "GenSigAutoGenDsp" SG_ 64 AB_Diagnose 1;
BA_ "GenSigSendType" SG_ 64 AB_Stellgliedtest 0;
BA_ "GenSigEnvVarType" SG_ 64 AB_Stellgliedtest 0;
BA_ "GenSigAutoGenSnd" SG_ 64 AB_Stellgliedtest 1;
BA_ "GenSigAutoGenDsp" SG_ 64 AB_Stellgliedtest 1;
BA_ "GenSigSendType" SG_ 64 AB_Erh_Auf_VB 0;
BA_ "GenSigEnvVarType" SG_ 64 AB_Erh_Auf_VB 0;
BA_ "GenSigAutoGenSnd" SG_ 64 AB_Erh_Auf_VB 1;
BA_ "GenSigAutoGenDsp" SG_ 64 AB_Erh_Auf_VB 1;
BA_ "GenSigSendType" SG_ 64 AB_Gurtwarn_VF 0;
BA_ "GenSigEnvVarType" SG_ 64 AB_Gurtwarn_VF 0;
BA_ "GenSigAutoGenSnd" SG_ 64 AB_Gurtwarn_VF 1;
BA_ "GenSigAutoGenDsp" SG_ 64 AB_Gurtwarn_VF 1;
BA_ "GenSigSendType" SG_ 64 AB_Gurtwarn_VB 0;
BA_ "GenSigEnvVarType" SG_ 64 AB_Gurtwarn_VB 0;
BA_ "GenSigAutoGenSnd" SG_ 64 AB_Gurtwarn_VB 1;
BA_ "GenSigAutoGenDsp" SG_ 64 AB_Gurtwarn_VB 1;
BA_ "GenSigSendType" SG_ 64 AB_Anzeige_Fussg 0;
BA_ "GenSigEnvVarType" SG_ 64 AB_Anzeige_Fussg 0;
BA_ "GenSigAutoGenSnd" SG_ 64 AB_Anzeige_Fussg 1;
BA_ "GenSigAutoGenDsp" SG_ 64 AB_Anzeige_Fussg 1;
BA_ "GenSigSendType" SG_ 64 AB_Texte_AKS 0;
BA_ "GenSigAutoGenSnd" SG_ 64 AB_Texte_AKS 1;
BA_ "GenSigAutoGenDsp" SG_ 64 AB_Texte_AKS 1;
BA_ "GenSigStartValue" SG_ 64 AB_PAO_Leuchte_Anf 1;
BA_ "GenSigSendType" SG_ 64 AB_PAO_Leuchte_Anf 0;
BA_ "GenSigAutoGenSnd" SG_ 64 AB_PAO_Leuchte_Anf 1;
BA_ "GenSigAutoGenDsp" SG_ 64 AB_PAO_Leuchte_Anf 1;
BA_ "GenSigSendType" SG_ 64 AB_MKB_gueltig 0;
BA_ "GenSigSendType" SG_ 64 AB_MKB_Anforderung 3;
BA_ "GenSigSendType" SG_ 64 AB_Versorgungsspannung 0;
BA_ "Fehlerwert" SG_ 1312 AB_Belegung_VB 1;
BA_ "GenSigSendType" SG_ 1312 AB_Belegung_VB 0;
BA_ "GenSigEnvVarType" SG_ 1312 AB_Belegung_VB 0;
BA_ "GenSigAutoGenSnd" SG_ 1312 AB_Belegung_VB 1;
BA_ "GenSigAutoGenDsp" SG_ 1312 AB_Belegung_VB 1;
BA_ "GenSigStartValue" SG_ 1312 AB_Gurtschloss_FA 1;
BA_ "GenSigSendType" SG_ 1312 AB_Gurtschloss_FA 0;
BA_ "GenSigAutoGenSnd" SG_ 1312 AB_Gurtschloss_FA 1;
BA_ "GenSigAutoGenDsp" SG_ 1312 AB_Gurtschloss_FA 1;
BA_ "GenSigStartValue" SG_ 1312 AB_Gurtschloss_BF 1;
BA_ "GenSigSendType" SG_ 1312 AB_Gurtschloss_BF 0;
BA_ "GenSigAutoGenSnd" SG_ 1312 AB_Gurtschloss_BF 1;
BA_ "GenSigAutoGenDsp" SG_ 1312 AB_Gurtschloss_BF 1;
BA_ "GenSigStartValue" SG_ 1312 AB_Gurtschloss_Reihe2_FA 1;
BA_ "GenSigSendType" SG_ 1312 AB_Gurtschloss_Reihe2_FA 0;
BA_ "GenSigAutoGenSnd" SG_ 1312 AB_Gurtschloss_Reihe2_FA 1;
BA_ "GenSigAutoGenDsp" SG_ 1312 AB_Gurtschloss_Reihe2_FA 1;
BA_ "GenSigStartValue" SG_ 1312 AB_Gurtschloss_Reihe2_MI 1;
BA_ "GenSigSendType" SG_ 1312 AB_Gurtschloss_Reihe2_MI 0;
BA_ "GenSigAutoGenSnd" SG_ 1312 AB_Gurtschloss_Reihe2_MI 1;
BA_ "GenSigAutoGenDsp" SG_ 1312 AB_Gurtschloss_Reihe2_MI 1;
BA_ "GenSigStartValue" SG_ 1312 AB_Gurtschloss_Reihe2_BF 1;
BA_ "GenSigSendType" SG_ 1312 AB_Gurtschloss_Reihe2_BF 0;
BA_ "GenSigAutoGenSnd" SG_ 1312 AB_Gurtschloss_Reihe2_BF 1;
BA_ "GenSigAutoGenDsp" SG_ 1312 AB_Gurtschloss_Reihe2_BF 1;
BA_ "GenSigStartValue" SG_ 1312 AB_Gurtschloss_Reihe3_FA 1;
BA_ "GenSigSendType" SG_ 1312 AB_Gurtschloss_Reihe3_FA 0;
BA_ "GenSigAutoGenSnd" SG_ 1312 AB_Gurtschloss_Reihe3_FA 1;
BA_ "GenSigAutoGenDsp" SG_ 1312 AB_Gurtschloss_Reihe3_FA 1;
BA_ "GenSigStartValue" SG_ 1312 AB_Gurtschloss_Reihe3_MI 1;
BA_ "GenSigSendType" SG_ 1312 AB_Gurtschloss_Reihe3_MI 0;
BA_ "GenSigAutoGenSnd" SG_ 1312 AB_Gurtschloss_Reihe3_MI 1;
BA_ "GenSigAutoGenDsp" SG_ 1312 AB_Gurtschloss_Reihe3_MI 1;
BA_ "GenSigStartValue" SG_ 1312 AB_Gurtschloss_Reihe3_BF 1;
BA_ "GenSigSendType" SG_ 1312 AB_Gurtschloss_Reihe3_BF 0;
BA_ "GenSigAutoGenSnd" SG_ 1312 AB_Gurtschloss_Reihe3_BF 1;
BA_ "GenSigAutoGenDsp" SG_ 1312 AB_Gurtschloss_Reihe3_BF 1;
BA_ "Fehlerwert" SG_ 1312 AB_Sitzpos_Sens_FA 1;
BA_ "GenSigSendType" SG_ 1312 AB_Sitzpos_Sens_FA 0;
BA_ "GenSigEnvVarType" SG_ 1312 AB_Sitzpos_Sens_FA 0;
BA_ "GenSigAutoGenSnd" SG_ 1312 AB_Sitzpos_Sens_FA 1;
BA_ "GenSigAutoGenDsp" SG_ 1312 AB_Sitzpos_Sens_FA 1;
BA_ "Fehlerwert" SG_ 1312 AB_Sitzpos_Sens_BF 1;
BA_ "GenSigSendType" SG_ 1312 AB_Sitzpos_Sens_BF 0;
BA_ "GenSigEnvVarType" SG_ 1312 AB_Sitzpos_Sens_BF 0;
BA_ "GenSigAutoGenSnd" SG_ 1312 AB_Sitzpos_Sens_BF 1;
BA_ "GenSigAutoGenDsp" SG_ 1312 AB_Sitzpos_Sens_BF 1;
BA_ "GenSigFuncType" SG_ 65 Airbag_03_CRC 2;
BA_ "GenSigSendType" SG_ 65 Airbag_03_CRC 0;
BA_ "GenSigEnvVarType" SG_ 65 Airbag_03_CRC 0;
BA_ "GenSigAutoGenSnd" SG_ 65 Airbag_03_CRC 1;
BA_ "GenSigAutoGenDsp" SG_ 65 Airbag_03_CRC 1;
BA_ "GenSigFuncType" SG_ 65 Airbag_03_BZ 1;
BA_ "GenSigSendType" SG_ 65 Airbag_03_BZ 0;
BA_ "GenSigEnvVarType" SG_ 65 Airbag_03_BZ 0;
BA_ "GenSigAutoGenSnd" SG_ 65 Airbag_03_BZ 1;
BA_ "GenSigAutoGenDsp" SG_ 65 Airbag_03_BZ 1;
BA_ "GenSigSendType" SG_ 65 AB_MKB_Safing 4;
BA_ "GenSigSwitchedByIgnition" SG_ 1633 AAG_BZ 0;
BA_ "GenSigFuncType" SG_ 1633 AAG_BZ 1;
BA_ "GenSigSendType" SG_ 1633 AAG_BZ 0;
BA_ "GenSigEnvVarType" SG_ 1633 AAG_BZ 0;
BA_ "GenSigAutoGenSnd" SG_ 1633 AAG_BZ 1;
BA_ "GenSigAutoGenDsp" SG_ 1633 AAG_BZ 1;
BA_ "GenSigSwitchedByIgnition" SG_ 1633 AAG_Bremsl_durch_ECD 0;
BA_ "GenSigSendType" SG_ 1633 AAG_Bremsl_durch_ECD 0;
BA_ "GenSigEnvVarType" SG_ 1633 AAG_Bremsl_durch_ECD 0;
BA_ "GenSigAutoGenSnd" SG_ 1633 AAG_Bremsl_durch_ECD 1;
BA_ "GenSigAutoGenDsp" SG_ 1633 AAG_Bremsl_durch_ECD 1;
BA_ "GenSigSwitchedByIgnition" SG_ 1633 AAG_Anhaenger_abgesteckt 0;
BA_ "GenSigSendType" SG_ 1633 AAG_Anhaenger_abgesteckt 0;
BA_ "GenSigEnvVarType" SG_ 1633 AAG_Anhaenger_abgesteckt 0;
BA_ "GenSigAutoGenSnd" SG_ 1633 AAG_Anhaenger_abgesteckt 1;
BA_ "GenSigAutoGenDsp" SG_ 1633 AAG_Anhaenger_abgesteckt 1;
BA_ "GenSigSwitchedByIgnition" SG_ 1633 AAG_NSL_aktiv 0;
BA_ "GenSigSendType" SG_ 1633 AAG_NSL_aktiv 0;
BA_ "GenSigEnvVarType" SG_ 1633 AAG_NSL_aktiv 0;
BA_ "GenSigAutoGenSnd" SG_ 1633 AAG_NSL_aktiv 1;
BA_ "GenSigAutoGenDsp" SG_ 1633 AAG_NSL_aktiv 1;
BA_ "GenSigSwitchedByIgnition" SG_ 1633 AAG_Anhaenger_erkannt 0;
BA_ "GenSigSendType" SG_ 1633 AAG_Anhaenger_erkannt 0;
BA_ "GenSigEnvVarType" SG_ 1633 AAG_Anhaenger_erkannt 0;
BA_ "GenSigAutoGenSnd" SG_ 1633 AAG_Anhaenger_erkannt 1;
BA_ "GenSigAutoGenDsp" SG_ 1633 AAG_Anhaenger_erkannt 1;
BA_ "GenSigSwitchedByIgnition" SG_ 1633 AAG_Blinker_H_aktiv 0;
BA_ "GenSigSendType" SG_ 1633 AAG_Blinker_H_aktiv 0;
BA_ "GenSigEnvVarType" SG_ 1633 AAG_Blinker_H_aktiv 0;
BA_ "GenSigAutoGenSnd" SG_ 1633 AAG_Blinker_H_aktiv 1;
BA_ "GenSigAutoGenDsp" SG_ 1633 AAG_Blinker_H_aktiv 1;
BA_ "GenSigSwitchedByIgnition" SG_ 1633 AAG_Blinker_HL_def 0;
BA_ "GenSigSendType" SG_ 1633 AAG_Blinker_HL_def 0;
BA_ "GenSigEnvVarType" SG_ 1633 AAG_Blinker_HL_def 0;
BA_ "GenSigAutoGenSnd" SG_ 1633 AAG_Blinker_HL_def 1;
BA_ "GenSigAutoGenDsp" SG_ 1633 AAG_Blinker_HL_def 1;
BA_ "GenSigSwitchedByIgnition" SG_ 1633 AAG_Blinker_HR_def 0;
BA_ "GenSigSendType" SG_ 1633 AAG_Blinker_HR_def 0;
BA_ "GenSigEnvVarType" SG_ 1633 AAG_Blinker_HR_def 0;
BA_ "GenSigAutoGenSnd" SG_ 1633 AAG_Blinker_HR_def 1;
BA_ "GenSigAutoGenDsp" SG_ 1633 AAG_Blinker_HR_def 1;
BA_ "GenSigSwitchedByIgnition" SG_ 1633 AAG_Bremslicht_H_def 0;
BA_ "GenSigSendType" SG_ 1633 AAG_Bremslicht_H_def 0;
BA_ "GenSigEnvVarType" SG_ 1633 AAG_Bremslicht_H_def 0;
BA_ "GenSigAutoGenSnd" SG_ 1633 AAG_Bremslicht_H_def 1;
BA_ "GenSigAutoGenDsp" SG_ 1633 AAG_Bremslicht_H_def 1;
BA_ "GenSigSwitchedByIgnition" SG_ 1633 AAG_Schlusslicht_HL_def 0;
BA_ "GenSigSendType" SG_ 1633 AAG_Schlusslicht_HL_def 0;
BA_ "GenSigEnvVarType" SG_ 1633 AAG_Schlusslicht_HL_def 0;
BA_ "GenSigAutoGenSnd" SG_ 1633 AAG_Schlusslicht_HL_def 1;
BA_ "GenSigAutoGenDsp" SG_ 1633 AAG_Schlusslicht_HL_def 1;
BA_ "GenSigSwitchedByIgnition" SG_ 1633 AAG_Schlusslicht_HR_def 0;
BA_ "GenSigSendType" SG_ 1633 AAG_Schlusslicht_HR_def 0;
BA_ "GenSigEnvVarType" SG_ 1633 AAG_Schlusslicht_HR_def 0;
BA_ "GenSigAutoGenSnd" SG_ 1633 AAG_Schlusslicht_HR_def 1;
BA_ "GenSigAutoGenDsp" SG_ 1633 AAG_Schlusslicht_HR_def 1;
BA_ "GenSigSwitchedByIgnition" SG_ 1633 AAG_AVS_Fehler_02 0;
BA_ "GenSigSendType" SG_ 1633 AAG_AVS_Fehler_02 0;
BA_ "GenSigEnvVarType" SG_ 1633 AAG_AVS_Fehler_02 0;
BA_ "GenSigAutoGenSnd" SG_ 1633 AAG_AVS_Fehler_02 1;
BA_ "GenSigAutoGenDsp" SG_ 1633 AAG_AVS_Fehler_02 1;
BA_ "GenSigSwitchedByIgnition" SG_ 1633 AAG_AVS_Stati 0;
BA_ "GenSigSendType" SG_ 1633 AAG_AVS_Stati 0;
BA_ "GenSigEnvVarType" SG_ 1633 AAG_AVS_Stati 0;
BA_ "GenSigAutoGenSnd" SG_ 1633 AAG_AVS_Stati 1;
BA_ "GenSigAutoGenDsp" SG_ 1633 AAG_AVS_Stati 1;
BA_ "GenSigSwitchedByIgnition" SG_ 2536767264 BAP_Debug_Cmd 0;
BA_ "GenSigSendType" SG_ 2536767264 BAP_Debug_Cmd 3;
BA_ "GenSigEnvVarType" SG_ 2536767264 BAP_Debug_Cmd 0;
BA_ "GenSigSwitchedByIgnition" SG_ 2536767280 BAP_Debug_Data 0;
BA_ "GenSigSendType" SG_ 2536767280 BAP_Debug_Data 3;
BA_ "GenSigEnvVarType" SG_ 2536767280 BAP_Debug_Data 0;
BA_ "GenSigSwitchedByIgnition" SG_ 2536709120 BAP_Hybrid_FSG_01_Header 0;
BA_ "GenSigSendType" SG_ 2536709120 BAP_Hybrid_FSG_01_Header 3;
BA_ "GenSigEnvVarType" SG_ 2536709120 BAP_Hybrid_FSG_01_Header 0;
BA_ "GenSigSwitchedByIgnition" SG_ 2536709121 BAP_Hybrid_ASG_02_Header 0;
BA_ "GenSigSendType" SG_ 2536709121 BAP_Hybrid_ASG_02_Header 3;
BA_ "GenSigEnvVarType" SG_ 2536709121 BAP_Hybrid_ASG_02_Header 0;
BA_ "GenSigSwitchedByIgnition" SG_ 2536709136 BAP_Hybrid_FSG_01_Header 0;
BA_ "GenSigSendType" SG_ 2536709136 BAP_Hybrid_FSG_01_Header 3;
BA_ "GenSigEnvVarType" SG_ 2536709136 BAP_Hybrid_FSG_01_Header 0;
BA_ "GenSigSwitchedByIgnition" SG_ 2536709888 BAP_RGS_ASG_01_Header 0;
BA_ "GenSigSendType" SG_ 2536709888 BAP_RGS_ASG_01_Header 3;
BA_ "GenSigEnvVarType" SG_ 2536709888 BAP_RGS_ASG_01_Header 0;
BA_ "GenSigSwitchedByIgnition" SG_ 2536709904 BAP_RGS_FSG_01_Header 0;
BA_ "GenSigSendType" SG_ 2536709904 BAP_RGS_FSG_01_Header 3;
BA_ "GenSigEnvVarType" SG_ 2536709904 BAP_RGS_FSG_01_Header 0;
BA_ "GenSigSwitchedByIgnition" SG_ 1626 BCM_Bremsbelag_Sensor 0;
BA_ "GenSigSendType" SG_ 1626 BCM_Bremsbelag_Sensor 3;
BA_ "GenSigEnvVarType" SG_ 1626 BCM_Bremsbelag_Sensor 0;
BA_ "GenSigAutoGenSnd" SG_ 1626 BCM_Bremsbelag_Sensor 1;
BA_ "GenSigAutoGenDsp" SG_ 1626 BCM_Bremsbelag_Sensor 1;
BA_ "GenSigSwitchedByIgnition" SG_ 1626 BCM_Bremsfluessigkeit_Sensor 0;
BA_ "GenSigSendType" SG_ 1626 BCM_Bremsfluessigkeit_Sensor 3;
BA_ "GenSigEnvVarType" SG_ 1626 BCM_Bremsfluessigkeit_Sensor 0;
BA_ "GenSigAutoGenSnd" SG_ 1626 BCM_Bremsfluessigkeit_Sensor 1;
BA_ "GenSigAutoGenDsp" SG_ 1626 BCM_Bremsfluessigkeit_Sensor 1;
BA_ "GenSigSwitchedByIgnition" SG_ 1626 BCM1_Licht_Warn 0;
BA_ "GenSigSendType" SG_ 1626 BCM1_Licht_Warn 3;
BA_ "GenSigEnvVarType" SG_ 1626 BCM1_Licht_Warn 0;
BA_ "GenSigAutoGenSnd" SG_ 1626 BCM1_Licht_Warn 1;
BA_ "GenSigAutoGenDsp" SG_ 1626 BCM1_Licht_Warn 1;
BA_ "GenSigSwitchedByIgnition" SG_ 1626 BCM_Waschwasser_Sensor 0;
BA_ "GenSigSendType" SG_ 1626 BCM_Waschwasser_Sensor 3;
BA_ "GenSigEnvVarType" SG_ 1626 BCM_Waschwasser_Sensor 0;
BA_ "GenSigAutoGenSnd" SG_ 1626 BCM_Waschwasser_Sensor 1;
BA_ "GenSigAutoGenDsp" SG_ 1626 BCM_Waschwasser_Sensor 1;
BA_ "GenSigSwitchedByIgnition" SG_ 1626 BCM_Kuehlmittel_Sensor 0;
BA_ "GenSigSendType" SG_ 1626 BCM_Kuehlmittel_Sensor 3;
BA_ "GenSigEnvVarType" SG_ 1626 BCM_Kuehlmittel_Sensor 0;
BA_ "GenSigAutoGenSnd" SG_ 1626 BCM_Kuehlmittel_Sensor 1;
BA_ "GenSigAutoGenDsp" SG_ 1626 BCM_Kuehlmittel_Sensor 1;
BA_ "GenSigSwitchedByIgnition" SG_ 1626 BCM1_Kl_15_HW_erkannt 0;
BA_ "GenSigSendType" SG_ 1626 BCM1_Kl_15_HW_erkannt 3;
BA_ "GenSigEnvVarType" SG_ 1626 BCM1_Kl_15_HW_erkannt 0;
BA_ "GenSigAutoGenSnd" SG_ 1626 BCM1_Kl_15_HW_erkannt 1;
BA_ "GenSigAutoGenDsp" SG_ 1626 BCM1_Kl_15_HW_erkannt 1;
BA_ "GenSigSwitchedByIgnition" SG_ 1626 BCM_Eis_Offroad_Taste 0;
BA_ "GenSigSendType" SG_ 1626 BCM_Eis_Offroad_Taste 3;
BA_ "GenSigEnvVarType" SG_ 1626 BCM_Eis_Offroad_Taste 0;
BA_ "GenSigAutoGenSnd" SG_ 1626 BCM_Eis_Offroad_Taste 1;
BA_ "GenSigAutoGenDsp" SG_ 1626 BCM_Eis_Offroad_Taste 1;
BA_ "GenSigSwitchedByIgnition" SG_ 1626 ZZH_Endlage_oben 0;
BA_ "GenSigSendType" SG_ 1626 ZZH_Endlage_oben 3;
BA_ "GenSigEnvVarType" SG_ 1626 ZZH_Endlage_oben 0;
BA_ "GenSigAutoGenSnd" SG_ 1626 ZZH_Endlage_oben 1;
BA_ "GenSigAutoGenDsp" SG_ 1626 ZZH_Endlage_oben 1;
BA_ "GenSigSwitchedByIgnition" SG_ 1626 ZZH_Endlage_unten 0;
BA_ "GenSigSendType" SG_ 1626 ZZH_Endlage_unten 3;
BA_ "GenSigEnvVarType" SG_ 1626 ZZH_Endlage_unten 0;
BA_ "GenSigAutoGenSnd" SG_ 1626 ZZH_Endlage_unten 1;
BA_ "GenSigAutoGenDsp" SG_ 1626 ZZH_Endlage_unten 1;
BA_ "GenSigSwitchedByIgnition" SG_ 1626 ZZH_Endlage_unplausibel 0;
BA_ "GenSigSendType" SG_ 1626 ZZH_Endlage_unplausibel 3;
BA_ "GenSigEnvVarType" SG_ 1626 ZZH_Endlage_unplausibel 0;
BA_ "GenSigAutoGenSnd" SG_ 1626 ZZH_Endlage_unplausibel 1;
BA_ "GenSigAutoGenDsp" SG_ 1626 ZZH_Endlage_unplausibel 1;
BA_ "GenSigSwitchedByIgnition" SG_ 1626 BCM2_EZS_gedrueckt 0;
BA_ "GenSigSendType" SG_ 1626 BCM2_EZS_gedrueckt 3;
BA_ "GenSigEnvVarType" SG_ 1626 BCM2_EZS_gedrueckt 0;
BA_ "GenSigAutoGenSnd" SG_ 1626 BCM2_EZS_gedrueckt 1;
BA_ "GenSigAutoGenDsp" SG_ 1626 BCM2_EZS_gedrueckt 1;
BA_ "GenSigSwitchedByIgnition" SG_ 1626 BCM2_SST_gedrueckt 0;
BA_ "GenSigSendType" SG_ 1626 BCM2_SST_gedrueckt 3;
BA_ "GenSigEnvVarType" SG_ 1626 BCM2_SST_gedrueckt 0;
BA_ "GenSigAutoGenSnd" SG_ 1626 BCM2_SST_gedrueckt 1;
BA_ "GenSigAutoGenDsp" SG_ 1626 BCM2_SST_gedrueckt 1;
BA_ "GenSigSwitchedByIgnition" SG_ 1626 BCM_Hybrid_StartStopp_Taste 0;
BA_ "GenSigSendType" SG_ 1626 BCM_Hybrid_StartStopp_Taste 3;
BA_ "GenSigEnvVarType" SG_ 1626 BCM_Hybrid_StartStopp_Taste 0;
BA_ "GenSigAutoGenSnd" SG_ 1626 BCM_Hybrid_StartStopp_Taste 1;
BA_ "GenSigAutoGenDsp" SG_ 1626 BCM_Hybrid_StartStopp_Taste 1;
BA_ "GenSigSwitchedByIgnition" SG_ 1626 BCM1_Warnblink_Taster 0;
BA_ "GenSigSendType" SG_ 1626 BCM1_Warnblink_Taster 3;
BA_ "GenSigEnvVarType" SG_ 1626 BCM1_Warnblink_Taster 0;
BA_ "GenSigAutoGenSnd" SG_ 1626 BCM1_Warnblink_Taster 1;
BA_ "GenSigAutoGenDsp" SG_ 1626 BCM1_Warnblink_Taster 1;
BA_ "GenSigSwitchedByIgnition" SG_ 1626 BCM1_Valet_Parking_Taster 0;
BA_ "GenSigSendType" SG_ 1626 BCM1_Valet_Parking_Taster 3;
BA_ "GenSigEnvVarType" SG_ 1626 BCM1_Valet_Parking_Taster 0;
BA_ "GenSigAutoGenSnd" SG_ 1626 BCM1_Valet_Parking_Taster 1;
BA_ "GenSigAutoGenDsp" SG_ 1626 BCM1_Valet_Parking_Taster 1;
BA_ "GenSigSwitchedByIgnition" SG_ 1626 BCM_Remotestart_Betrieb 0;
BA_ "GenSigSendType" SG_ 1626 BCM_Remotestart_Betrieb 3;
BA_ "GenSigSwitchedByIgnition" SG_ 1626 BCM1_HSK_Taster 0;
BA_ "GenSigSendType" SG_ 1626 BCM1_HSK_Taster 3;
BA_ "GenSigEnvVarType" SG_ 1626 BCM1_HSK_Taster 0;
BA_ "GenSigAutoGenSnd" SG_ 1626 BCM1_HSK_Taster 1;
BA_ "GenSigAutoGenDsp" SG_ 1626 BCM1_HSK_Taster 1;
BA_ "GenSigSwitchedByIgnition" SG_ 1626 BCM1_Heckrollo_Taster 0;
BA_ "GenSigSendType" SG_ 1626 BCM1_Heckrollo_Taster 3;
BA_ "GenSigEnvVarType" SG_ 1626 BCM1_Heckrollo_Taster 0;
BA_ "GenSigAutoGenSnd" SG_ 1626 BCM1_Heckrollo_Taster 1;
BA_ "GenSigAutoGenDsp" SG_ 1626 BCM1_Heckrollo_Taster 1;
BA_ "GenSigSwitchedByIgnition" SG_ 1626 BCM1_Rueckfahrlicht_Schalter 0;
BA_ "GenSigSendType" SG_ 1626 BCM1_Rueckfahrlicht_Schalter 3;
BA_ "GenSigEnvVarType" SG_ 1626 BCM1_Rueckfahrlicht_Schalter 0;
BA_ "GenSigAutoGenSnd" SG_ 1626 BCM1_Rueckfahrlicht_Schalter 1;
BA_ "GenSigAutoGenDsp" SG_ 1626 BCM1_Rueckfahrlicht_Schalter 1;
BA_ "GenSigSwitchedByIgnition" SG_ 1626 BCM1_MH_Schalter 0;
BA_ "GenSigSendType" SG_ 1626 BCM1_MH_Schalter 3;
BA_ "GenSigEnvVarType" SG_ 1626 BCM1_MH_Schalter 0;
BA_ "GenSigAutoGenSnd" SG_ 1626 BCM1_MH_Schalter 1;
BA_ "GenSigAutoGenDsp" SG_ 1626 BCM1_MH_Schalter 1;
BA_ "GenSigSwitchedByIgnition" SG_ 1626 BCM1_MH_WIV_Schalter 0;
BA_ "GenSigSendType" SG_ 1626 BCM1_MH_WIV_Schalter 3;
BA_ "GenSigEnvVarType" SG_ 1626 BCM1_MH_WIV_Schalter 0;
BA_ "GenSigAutoGenSnd" SG_ 1626 BCM1_MH_WIV_Schalter 1;
BA_ "GenSigAutoGenDsp" SG_ 1626 BCM1_MH_WIV_Schalter 1;
BA_ "GenSigSwitchedByIgnition" SG_ 1626 BCM_Eco_Charisma_Taste 0;
BA_ "GenSigSendType" SG_ 1626 BCM_Eco_Charisma_Taste 3;
BA_ "GenSigEnvVarType" SG_ 1626 BCM_Eco_Charisma_Taste 0;
BA_ "GenSigAutoGenSnd" SG_ 1626 BCM_Eco_Charisma_Taste 1;
BA_ "GenSigAutoGenDsp" SG_ 1626 BCM_Eco_Charisma_Taste 1;
BA_ "GenSigSwitchedByIgnition" SG_ 1626 BCM_Thermomanagement 0;
BA_ "GenSigSendType" SG_ 1626 BCM_Thermomanagement 3;
BA_ "GenSigEnvVarType" SG_ 1626 BCM_Thermomanagement 0;
BA_ "GenSigAutoGenSnd" SG_ 1626 BCM_Thermomanagement 1;
BA_ "GenSigAutoGenDsp" SG_ 1626 BCM_Thermomanagement 1;
BA_ "GenSigSwitchedByIgnition" SG_ 1626 BCM_Thermomanagement_Fehler 0;
BA_ "GenSigSendType" SG_ 1626 BCM_Thermomanagement_Fehler 3;
BA_ "GenSigEnvVarType" SG_ 1626 BCM_Thermomanagement_Fehler 0;
BA_ "GenSigAutoGenSnd" SG_ 1626 BCM_Thermomanagement_Fehler 1;
BA_ "GenSigAutoGenDsp" SG_ 1626 BCM_Thermomanagement_Fehler 1;
BA_ "GenSigSwitchedByIgnition" SG_ 1626 BCM_Thermomanagement_gueltig 0;
BA_ "GenSigSendType" SG_ 1626 BCM_Thermomanagement_gueltig 3;
BA_ "GenSigEnvVarType" SG_ 1626 BCM_Thermomanagement_gueltig 0;
BA_ "GenSigAutoGenSnd" SG_ 1626 BCM_Thermomanagement_gueltig 1;
BA_ "GenSigAutoGenDsp" SG_ 1626 BCM_Thermomanagement_gueltig 1;
BA_ "GenSigSwitchedByIgnition" SG_ 1626 BCM1_Lichtwarn_Texte 0;
BA_ "GenSigSendType" SG_ 1626 BCM1_Lichtwarn_Texte 3;
BA_ "Fehlerwert" SG_ 869 BEM_P_Generator 255;
BA_ "GenSigSwitchedByIgnition" SG_ 869 BEM_P_Generator 0;
BA_ "GenSigSendType" SG_ 869 BEM_P_Generator 0;
BA_ "GenSigEnvVarType" SG_ 869 BEM_P_Generator 0;
BA_ "GenSigAutoGenSnd" SG_ 869 BEM_P_Generator 1;
BA_ "GenSigAutoGenDsp" SG_ 869 BEM_P_Generator 1;
BA_ "GenSigSwitchedByIgnition" SG_ 869 BEM_n_LLA 0;
BA_ "GenSigSendType" SG_ 869 BEM_n_LLA 0;
BA_ "GenSigEnvVarType" SG_ 869 BEM_n_LLA 0;
BA_ "GenSigAutoGenSnd" SG_ 869 BEM_n_LLA 1;
BA_ "GenSigAutoGenDsp" SG_ 869 BEM_n_LLA 1;
BA_ "GenSigSwitchedByIgnition" SG_ 869 BEM_01_Abschaltstufen 0;
BA_ "GenSigSendType" SG_ 869 BEM_01_Abschaltstufen 0;
BA_ "GenSigEnvVarType" SG_ 869 BEM_01_Abschaltstufen 0;
BA_ "GenSigAutoGenSnd" SG_ 869 BEM_01_Abschaltstufen 1;
BA_ "GenSigAutoGenDsp" SG_ 869 BEM_01_Abschaltstufen 1;
BA_ "GenSigSwitchedByIgnition" SG_ 869 BEM_Anf_KL 0;
BA_ "GenSigSendType" SG_ 869 BEM_Anf_KL 0;
BA_ "GenSigEnvVarType" SG_ 869 BEM_Anf_KL 0;
BA_ "GenSigAutoGenSnd" SG_ 869 BEM_Anf_KL 1;
BA_ "GenSigAutoGenDsp" SG_ 869 BEM_Anf_KL 1;
BA_ "GenSigSwitchedByIgnition" SG_ 869 BEM_StartStopp_Info 0;
BA_ "GenSigSendType" SG_ 869 BEM_StartStopp_Info 0;
BA_ "GenSigAutoGenSnd" SG_ 869 BEM_StartStopp_Info 1;
BA_ "GenSigAutoGenDsp" SG_ 869 BEM_StartStopp_Info 1;
BA_ "GenSigSwitchedByIgnition" SG_ 869 BEM_DFM 0;
BA_ "GenSigSendType" SG_ 869 BEM_DFM 0;
BA_ "GenSigAutoGenSnd" SG_ 869 BEM_DFM 1;
BA_ "GenSigAutoGenDsp" SG_ 869 BEM_DFM 1;
BA_ "GenSigSwitchedByIgnition" SG_ 869 BEM_EMLIN_ungueltig 0;
BA_ "GenSigSendType" SG_ 869 BEM_EMLIN_ungueltig 0;
BA_ "GenSigEnvVarType" SG_ 869 BEM_EMLIN_ungueltig 0;
BA_ "GenSigAutoGenSnd" SG_ 869 BEM_EMLIN_ungueltig 1;
BA_ "GenSigAutoGenDsp" SG_ 869 BEM_EMLIN_ungueltig 1;
BA_ "GenSigSwitchedByIgnition" SG_ 869 BEM_Batt_Ab 0;
BA_ "GenSigSendType" SG_ 869 BEM_Batt_Ab 0;
BA_ "GenSigAutoGenSnd" SG_ 869 BEM_Batt_Ab 1;
BA_ "GenSigAutoGenDsp" SG_ 869 BEM_Batt_Ab 1;
BA_ "GenSigSendType" SG_ 869 BEM_Segel_Info 0;
BA_ "GenSigStartValue" SG_ 869 BEM_HYB_DC_uSollLV 37;
BA_ "GenSigSendType" SG_ 869 BEM_HYB_DC_uSollLV 0;
BA_ "GenSigAutoGenSnd" SG_ 869 BEM_HYB_DC_uSollLV 1;
BA_ "GenSigAutoGenDsp" SG_ 869 BEM_HYB_DC_uSollLV 1;
BA_ "Fehlerwert" SG_ 869 BEM_HYB_DC_uMinLV 255;
BA_ "GenSigStartValue" SG_ 869 BEM_HYB_DC_uMinLV 254;
BA_ "GenSigSendType" SG_ 869 BEM_HYB_DC_uMinLV 0;
BA_ "GenSigAutoGenSnd" SG_ 869 BEM_HYB_DC_uMinLV 1;
BA_ "GenSigAutoGenDsp" SG_ 869 BEM_HYB_DC_uMinLV 1;
BA_ "GenSigSendType" SG_ 1628 BMS_HYB_ASV_hinten_Status 0;
BA_ "GenSigAutoGenSnd" SG_ 1628 BMS_HYB_ASV_hinten_Status 1;
BA_ "GenSigAutoGenDsp" SG_ 1628 BMS_HYB_ASV_hinten_Status 1;
BA_ "GenSigSendType" SG_ 1628 BMS_HYB_ASV_vorne_Status 0;
BA_ "GenSigAutoGenSnd" SG_ 1628 BMS_HYB_ASV_vorne_Status 1;
BA_ "GenSigAutoGenDsp" SG_ 1628 BMS_HYB_ASV_vorne_Status 1;
BA_ "GenSigSwitchedByIgnition" SG_ 1628 BMS_HYB_KD_Fehler 0;
BA_ "GenSigSendType" SG_ 1628 BMS_HYB_KD_Fehler 0;
BA_ "GenSigEnvVarType" SG_ 1628 BMS_HYB_KD_Fehler 0;
BA_ "GenSigAutoGenSnd" SG_ 1628 BMS_HYB_KD_Fehler 1;
BA_ "GenSigAutoGenDsp" SG_ 1628 BMS_HYB_KD_Fehler 1;
BA_ "Fehlerwert" SG_ 1628 BMS_HYB_BattFanSpd 15;
BA_ "GenSigStartValue" SG_ 1628 BMS_HYB_BattFanSpd 14;
BA_ "GenSigSendType" SG_ 1628 BMS_HYB_BattFanSpd 0;
BA_ "GenSigAutoGenSnd" SG_ 1628 BMS_HYB_BattFanSpd 1;
BA_ "GenSigAutoGenDsp" SG_ 1628 BMS_HYB_BattFanSpd 1;
BA_ "GenSigSendType" SG_ 1628 BMS_HYB_VentilationReq 0;
BA_ "GenSigAutoGenSnd" SG_ 1628 BMS_HYB_VentilationReq 1;
BA_ "GenSigAutoGenDsp" SG_ 1628 BMS_HYB_VentilationReq 1;
BA_ "GenSigSendType" SG_ 1628 BMS_HYB_Spuelbetrieb_Status 0;
BA_ "GenSigAutoGenSnd" SG_ 1628 BMS_HYB_Spuelbetrieb_Status 1;
BA_ "GenSigAutoGenDsp" SG_ 1628 BMS_HYB_Spuelbetrieb_Status 1;
BA_ "GenSigSendType" SG_ 1628 BMS_HYB_Kuehlung_Anf 0;
BA_ "GenSigAutoGenSnd" SG_ 1628 BMS_HYB_Kuehlung_Anf 1;
BA_ "GenSigAutoGenDsp" SG_ 1628 BMS_HYB_Kuehlung_Anf 1;
BA_ "Fehlerwert" SG_ 1628 BMS_HYB_Temp_vor_Verd 255;
BA_ "GenSigStartValue" SG_ 1628 BMS_HYB_Temp_vor_Verd 254;
BA_ "GenSigSendType" SG_ 1628 BMS_HYB_Temp_vor_Verd 0;
BA_ "GenSigAutoGenSnd" SG_ 1628 BMS_HYB_Temp_vor_Verd 1;
BA_ "GenSigAutoGenDsp" SG_ 1628 BMS_HYB_Temp_vor_Verd 1;
BA_ "Fehlerwert" SG_ 1628 BMS_HYB_Temp_nach_Verd 255;
BA_ "GenSigStartValue" SG_ 1628 BMS_HYB_Temp_nach_Verd 254;
BA_ "GenSigSendType" SG_ 1628 BMS_HYB_Temp_nach_Verd 0;
BA_ "GenSigAutoGenSnd" SG_ 1628 BMS_HYB_Temp_nach_Verd 1;
BA_ "GenSigAutoGenDsp" SG_ 1628 BMS_HYB_Temp_nach_Verd 1;
BA_ "Fehlerwert" SG_ 1628 BMS_Temperatur 255;
BA_ "GenSigSwitchedByIgnition" SG_ 1628 BMS_Temperatur 0;
BA_ "GenSigStartValue" SG_ 1628 BMS_Temperatur 254;
BA_ "GenSigSendType" SG_ 1628 BMS_Temperatur 0;
BA_ "GenSigAutoGenSnd" SG_ 1628 BMS_Temperatur 1;
BA_ "GenSigAutoGenDsp" SG_ 1628 BMS_Temperatur 1;
BA_ "Fehlerwert" SG_ 1628 BMS_Temperatur_Ansaugluft 255;
BA_ "GenSigSwitchedByIgnition" SG_ 1628 BMS_Temperatur_Ansaugluft 0;
BA_ "GenSigStartValue" SG_ 1628 BMS_Temperatur_Ansaugluft 254;
BA_ "GenSigSendType" SG_ 1628 BMS_Temperatur_Ansaugluft 0;
BA_ "GenSigAutoGenSnd" SG_ 1628 BMS_Temperatur_Ansaugluft 1;
BA_ "GenSigAutoGenDsp" SG_ 1628 BMS_Temperatur_Ansaugluft 1;
BA_ "Fehlerwert" SG_ 1628 BMS_IstSpannung_HV 255;
BA_ "GenSigSwitchedByIgnition" SG_ 1628 BMS_IstSpannung_HV 0;
BA_ "GenSigStartValue" SG_ 1628 BMS_IstSpannung_HV 254;
BA_ "GenSigSendType" SG_ 1628 BMS_IstSpannung_HV 0;
BA_ "GenSigAutoGenSnd" SG_ 1628 BMS_IstSpannung_HV 1;
BA_ "GenSigAutoGenDsp" SG_ 1628 BMS_IstSpannung_HV 1;
BA_ "GenSigSwitchedByIgnition" SG_ 2617236992 CCP_BMS_CRO_01_Data 0;
BA_ "GenSigEnvVarType" SG_ 2617236992 CCP_BMS_CRO_01_Data 0;
BA_ "GenSigAutoGenSnd" SG_ 2617236992 CCP_BMS_CRO_01_Data 1;
BA_ "GenSigAutoGenDsp" SG_ 2617236992 CCP_BMS_CRO_01_Data 1;
BA_ "GenSigSwitchedByIgnition" SG_ 2281692672 CCP_BMS_CRO_02_Data 0;
BA_ "GenSigEnvVarType" SG_ 2281692672 CCP_BMS_CRO_02_Data 0;
BA_ "GenSigAutoGenSnd" SG_ 2281692672 CCP_BMS_CRO_02_Data 1;
BA_ "GenSigAutoGenDsp" SG_ 2281692672 CCP_BMS_CRO_02_Data 1;
BA_ "GenSigSwitchedByIgnition" SG_ 2617236993 CCP_BMS_DTO_01_Data 0;
BA_ "GenSigEnvVarType" SG_ 2617236993 CCP_BMS_DTO_01_Data 0;
BA_ "GenSigAutoGenSnd" SG_ 2617236993 CCP_BMS_DTO_01_Data 1;
BA_ "GenSigAutoGenDsp" SG_ 2617236993 CCP_BMS_DTO_01_Data 1;
BA_ "GenSigSwitchedByIgnition" SG_ 2281692673 CCP_BMS_DTO_02_Data 0;
BA_ "GenSigEnvVarType" SG_ 2281692673 CCP_BMS_DTO_02_Data 0;
BA_ "GenSigAutoGenSnd" SG_ 2281692673 CCP_BMS_DTO_02_Data 1;
BA_ "GenSigAutoGenDsp" SG_ 2281692673 CCP_BMS_DTO_02_Data 1;
BA_ "GenSigSwitchedByIgnition" SG_ 2281684480 CCP_Getriebe_CRO_01_Data 0;
BA_ "GenSigEnvVarType" SG_ 2281684480 CCP_Getriebe_CRO_01_Data 0;
BA_ "GenSigAutoGenSnd" SG_ 2281684480 CCP_Getriebe_CRO_01_Data 1;
BA_ "GenSigAutoGenDsp" SG_ 2281684480 CCP_Getriebe_CRO_01_Data 1;
BA_ "GenSigSwitchedByIgnition" SG_ 2281684481 CCP_Getriebe_DTO_01_Data 0;
BA_ "GenSigEnvVarType" SG_ 2281684481 CCP_Getriebe_DTO_01_Data 0;
BA_ "GenSigAutoGenSnd" SG_ 2281684481 CCP_Getriebe_DTO_01_Data 1;
BA_ "GenSigAutoGenDsp" SG_ 2281684481 CCP_Getriebe_DTO_01_Data 1;
BA_ "GenSigSwitchedByIgnition" SG_ 2281684482 CCP_Getriebe_DTO_02_Data 0;
BA_ "GenSigEnvVarType" SG_ 2281684482 CCP_Getriebe_DTO_02_Data 0;
BA_ "GenSigAutoGenSnd" SG_ 2281684482 CCP_Getriebe_DTO_02_Data 1;
BA_ "GenSigAutoGenDsp" SG_ 2281684482 CCP_Getriebe_DTO_02_Data 1;
BA_ "GenSigSwitchedByIgnition" SG_ 2281684483 CCP_Getriebe_DTO_03_Data 0;
BA_ "GenSigEnvVarType" SG_ 2281684483 CCP_Getriebe_DTO_03_Data 0;
BA_ "GenSigAutoGenSnd" SG_ 2281684483 CCP_Getriebe_DTO_03_Data 1;
BA_ "GenSigAutoGenDsp" SG_ 2281684483 CCP_Getriebe_DTO_03_Data 1;
BA_ "GenSigSwitchedByIgnition" SG_ 2281684484 CCP_Getriebe_DTO_04_Data 0;
BA_ "GenSigEnvVarType" SG_ 2281684484 CCP_Getriebe_DTO_04_Data 0;
BA_ "GenSigAutoGenSnd" SG_ 2281684484 CCP_Getriebe_DTO_04_Data 1;
BA_ "GenSigAutoGenDsp" SG_ 2281684484 CCP_Getriebe_DTO_04_Data 1;
BA_ "GenSigSwitchedByIgnition" SG_ 2617226752 CCP_Motor_CRO_01_Data 0;
BA_ "GenSigEnvVarType" SG_ 2617226752 CCP_Motor_CRO_01_Data 0;
BA_ "GenSigAutoGenSnd" SG_ 2617226752 CCP_Motor_CRO_01_Data 1;
BA_ "GenSigAutoGenDsp" SG_ 2617226752 CCP_Motor_CRO_01_Data 1;
BA_ "GenSigSwitchedByIgnition" SG_ 2617226753 CCP_Motor_DTO_01_Data 0;
BA_ "GenSigEnvVarType" SG_ 2617226753 CCP_Motor_DTO_01_Data 0;
BA_ "GenSigAutoGenSnd" SG_ 2617226753 CCP_Motor_DTO_01_Data 1;
BA_ "GenSigAutoGenDsp" SG_ 2617226753 CCP_Motor_DTO_01_Data 1;
BA_ "GenSigSwitchedByIgnition" SG_ 2617226754 CCP_Motor_DTO_02_Data 0;
BA_ "GenSigEnvVarType" SG_ 2617226754 CCP_Motor_DTO_02_Data 0;
BA_ "GenSigAutoGenSnd" SG_ 2617226754 CCP_Motor_DTO_02_Data 1;
BA_ "GenSigAutoGenDsp" SG_ 2617226754 CCP_Motor_DTO_02_Data 1;
BA_ "GenSigSwitchedByIgnition" SG_ 2617226755 CCP_Motor_DTO_03_Data 0;
BA_ "GenSigEnvVarType" SG_ 2617226755 CCP_Motor_DTO_03_Data 0;
BA_ "GenSigAutoGenSnd" SG_ 2617226755 CCP_Motor_DTO_03_Data 1;
BA_ "GenSigAutoGenDsp" SG_ 2617226755 CCP_Motor_DTO_03_Data 1;
BA_ "GenSigSwitchedByIgnition" SG_ 2617042432 CCP_Soundaktor_CRO_01_Data 0;
BA_ "GenSigEnvVarType" SG_ 2617042432 CCP_Soundaktor_CRO_01_Data 0;
BA_ "GenSigAutoGenSnd" SG_ 2617042432 CCP_Soundaktor_CRO_01_Data 1;
BA_ "GenSigAutoGenDsp" SG_ 2617042432 CCP_Soundaktor_CRO_01_Data 1;
BA_ "GenSigSwitchedByIgnition" SG_ 2617042433 CCP_Soundaktor_DTO_01_Data 0;
BA_ "GenSigEnvVarType" SG_ 2617042433 CCP_Soundaktor_DTO_01_Data 0;
BA_ "GenSigAutoGenSnd" SG_ 2617042433 CCP_Soundaktor_DTO_01_Data 1;
BA_ "GenSigAutoGenDsp" SG_ 2617042433 CCP_Soundaktor_DTO_01_Data 1;
BA_ "GenSigSwitchedByIgnition" SG_ 901 CHA_Ziel_FahrPr_ALR 0;
BA_ "GenSigSendType" SG_ 901 CHA_Ziel_FahrPr_ALR 1;
BA_ "GenSigEnvVarType" SG_ 901 CHA_Ziel_FahrPr_ALR 0;
BA_ "GenSigAutoGenSnd" SG_ 901 CHA_Ziel_FahrPr_ALR 1;
BA_ "GenSigAutoGenDsp" SG_ 901 CHA_Ziel_FahrPr_ALR 1;
BA_ "GenSigSwitchedByIgnition" SG_ 901 CHA_Ziel_FahrPr_ESP 0;
BA_ "GenSigSendType" SG_ 901 CHA_Ziel_FahrPr_ESP 1;
BA_ "GenSigEnvVarType" SG_ 901 CHA_Ziel_FahrPr_ESP 0;
BA_ "GenSigAutoGenSnd" SG_ 901 CHA_Ziel_FahrPr_ESP 1;
BA_ "GenSigAutoGenDsp" SG_ 901 CHA_Ziel_FahrPr_ESP 1;
BA_ "GenSigSwitchedByIgnition" SG_ 901 CHA_Ziel_FahrPr_FL 0;
BA_ "GenSigSendType" SG_ 901 CHA_Ziel_FahrPr_FL 1;
BA_ "GenSigEnvVarType" SG_ 901 CHA_Ziel_FahrPr_FL 0;
BA_ "GenSigAutoGenSnd" SG_ 901 CHA_Ziel_FahrPr_FL 1;
BA_ "GenSigAutoGenDsp" SG_ 901 CHA_Ziel_FahrPr_FL 1;
BA_ "GenSigSwitchedByIgnition" SG_ 901 CHA_Fahrer_Umschaltung 0;
BA_ "GenSigSendType" SG_ 901 CHA_Fahrer_Umschaltung 1;
BA_ "GenSigSwitchedByIgnition" SG_ 901 CHA_Ziel_FahrPr_MO 0;
BA_ "GenSigSendType" SG_ 901 CHA_Ziel_FahrPr_MO 1;
BA_ "GenSigEnvVarType" SG_ 901 CHA_Ziel_FahrPr_MO 0;
BA_ "GenSigAutoGenSnd" SG_ 901 CHA_Ziel_FahrPr_MO 1;
BA_ "GenSigAutoGenDsp" SG_ 901 CHA_Ziel_FahrPr_MO 1;
BA_ "GenSigSwitchedByIgnition" SG_ 901 CHA_Ziel_FahrPr_GE 0;
BA_ "GenSigSendType" SG_ 901 CHA_Ziel_FahrPr_GE 1;
BA_ "GenSigEnvVarType" SG_ 901 CHA_Ziel_FahrPr_GE 0;
BA_ "GenSigAutoGenSnd" SG_ 901 CHA_Ziel_FahrPr_GE 1;
BA_ "GenSigAutoGenDsp" SG_ 901 CHA_Ziel_FahrPr_GE 1;
BA_ "GenSigSwitchedByIgnition" SG_ 901 CHA_Ziel_FahrPr_ST 0;
BA_ "GenSigSendType" SG_ 901 CHA_Ziel_FahrPr_ST 1;
BA_ "GenSigEnvVarType" SG_ 901 CHA_Ziel_FahrPr_ST 0;
BA_ "GenSigAutoGenSnd" SG_ 901 CHA_Ziel_FahrPr_ST 1;
BA_ "GenSigAutoGenDsp" SG_ 901 CHA_Ziel_FahrPr_ST 1;
BA_ "GenSigSwitchedByIgnition" SG_ 901 CHA_Ziel_FahrPr_SCU 0;
BA_ "GenSigSendType" SG_ 901 CHA_Ziel_FahrPr_SCU 1;
BA_ "GenSigEnvVarType" SG_ 901 CHA_Ziel_FahrPr_SCU 0;
BA_ "GenSigAutoGenSnd" SG_ 901 CHA_Ziel_FahrPr_SCU 1;
BA_ "GenSigAutoGenDsp" SG_ 901 CHA_Ziel_FahrPr_SCU 1;
BA_ "GenSigSwitchedByIgnition" SG_ 901 CHA_Ziel_FahrPr_DR 0;
BA_ "GenSigSendType" SG_ 901 CHA_Ziel_FahrPr_DR 1;
BA_ "GenSigEnvVarType" SG_ 901 CHA_Ziel_FahrPr_DR 0;
BA_ "GenSigAutoGenSnd" SG_ 901 CHA_Ziel_FahrPr_DR 1;
BA_ "GenSigAutoGenDsp" SG_ 901 CHA_Ziel_FahrPr_DR 1;
BA_ "GenSigSwitchedByIgnition" SG_ 901 CHA_Ziel_FahrPr_QS 0;
BA_ "GenSigSendType" SG_ 901 CHA_Ziel_FahrPr_QS 1;
BA_ "GenSigEnvVarType" SG_ 901 CHA_Ziel_FahrPr_QS 0;
BA_ "GenSigAutoGenSnd" SG_ 901 CHA_Ziel_FahrPr_QS 1;
BA_ "GenSigAutoGenDsp" SG_ 901 CHA_Ziel_FahrPr_QS 1;
BA_ "GenSigSwitchedByIgnition" SG_ 901 CHA_Ziel_FahrPr_AFS 0;
BA_ "GenSigSendType" SG_ 901 CHA_Ziel_FahrPr_AFS 1;
BA_ "GenSigEnvVarType" SG_ 901 CHA_Ziel_FahrPr_AFS 0;
BA_ "GenSigAutoGenSnd" SG_ 901 CHA_Ziel_FahrPr_AFS 1;
BA_ "GenSigAutoGenDsp" SG_ 901 CHA_Ziel_FahrPr_AFS 1;
BA_ "GenSigSwitchedByIgnition" SG_ 901 CHA_Ziel_FahrPr_RGS 0;
BA_ "GenSigSendType" SG_ 901 CHA_Ziel_FahrPr_RGS 1;
BA_ "GenSigEnvVarType" SG_ 901 CHA_Ziel_FahrPr_RGS 0;
BA_ "GenSigAutoGenSnd" SG_ 901 CHA_Ziel_FahrPr_RGS 1;
BA_ "GenSigAutoGenDsp" SG_ 901 CHA_Ziel_FahrPr_RGS 1;
BA_ "GenSigSwitchedByIgnition" SG_ 901 CHA_Ziel_FahrPr_EPS 0;
BA_ "GenSigSendType" SG_ 901 CHA_Ziel_FahrPr_EPS 1;
BA_ "GenSigEnvVarType" SG_ 901 CHA_Ziel_FahrPr_EPS 0;
BA_ "GenSigAutoGenSnd" SG_ 901 CHA_Ziel_FahrPr_EPS 1;
BA_ "GenSigAutoGenDsp" SG_ 901 CHA_Ziel_FahrPr_EPS 1;
BA_ "GenSigSwitchedByIgnition" SG_ 901 CHA_Ziel_FahrPr_ACC 0;
BA_ "GenSigSendType" SG_ 901 CHA_Ziel_FahrPr_ACC 1;
BA_ "GenSigEnvVarType" SG_ 901 CHA_Ziel_FahrPr_ACC 0;
BA_ "GenSigAutoGenSnd" SG_ 901 CHA_Ziel_FahrPr_ACC 1;
BA_ "GenSigAutoGenDsp" SG_ 901 CHA_Ziel_FahrPr_ACC 1;
BA_ "GenSigSwitchedByIgnition" SG_ 901 CHA_Ziel_FahrPr_SAK 0;
BA_ "GenSigSendType" SG_ 901 CHA_Ziel_FahrPr_SAK 1;
BA_ "GenSigEnvVarType" SG_ 901 CHA_Ziel_FahrPr_SAK 0;
BA_ "GenSigAutoGenSnd" SG_ 901 CHA_Ziel_FahrPr_SAK 1;
BA_ "GenSigAutoGenDsp" SG_ 901 CHA_Ziel_FahrPr_SAK 1;
BA_ "GenSigSwitchedByIgnition" SG_ 901 CHA_Ziel_FahrPr_MStSt 0;
BA_ "GenSigSendType" SG_ 901 CHA_Ziel_FahrPr_MStSt 1;
BA_ "GenSigEnvVarType" SG_ 901 CHA_Ziel_FahrPr_MStSt 0;
BA_ "GenSigAutoGenSnd" SG_ 901 CHA_Ziel_FahrPr_MStSt 1;
BA_ "GenSigAutoGenDsp" SG_ 901 CHA_Ziel_FahrPr_MStSt 1;
BA_ "Fehlerwert" SG_ 945 DC_HYB_iAktLV 1023;
BA_ "GenSigSwitchedByIgnition" SG_ 945 DC_HYB_iAktLV 0;
BA_ "GenSigStartValue" SG_ 945 DC_HYB_iAktLV 1022;
BA_ "GenSigSendType" SG_ 945 DC_HYB_iAktLV 0;
BA_ "GenSigAutoGenSnd" SG_ 945 DC_HYB_iAktLV 1;
BA_ "GenSigAutoGenDsp" SG_ 945 DC_HYB_iAktLV 1;
BA_ "Fehlerwert" SG_ 945 DC_HYB_iAktReserveLV 1023;
BA_ "GenSigSwitchedByIgnition" SG_ 945 DC_HYB_iAktReserveLV 0;
BA_ "GenSigStartValue" SG_ 945 DC_HYB_iAktReserveLV 1022;
BA_ "GenSigSendType" SG_ 945 DC_HYB_iAktReserveLV 0;
BA_ "GenSigAutoGenSnd" SG_ 945 DC_HYB_iAktReserveLV 1;
BA_ "GenSigAutoGenDsp" SG_ 945 DC_HYB_iAktReserveLV 1;
BA_ "Fehlerwert" SG_ 945 DC_HYB_uAktLV 255;
BA_ "GenSigSwitchedByIgnition" SG_ 945 DC_HYB_uAktLV 0;
BA_ "GenSigStartValue" SG_ 945 DC_HYB_uAktLV 254;
BA_ "GenSigSendType" SG_ 945 DC_HYB_uAktLV 0;
BA_ "GenSigAutoGenSnd" SG_ 945 DC_HYB_uAktLV 1;
BA_ "GenSigAutoGenDsp" SG_ 945 DC_HYB_uAktLV 1;
BA_ "GenSigSwitchedByIgnition" SG_ 945 DC_HYB_LangsRegelung 0;
BA_ "GenSigSendType" SG_ 945 DC_HYB_LangsRegelung 0;
BA_ "GenSigAutoGenSnd" SG_ 945 DC_HYB_LangsRegelung 1;
BA_ "GenSigAutoGenDsp" SG_ 945 DC_HYB_LangsRegelung 1;
BA_ "GenSigSwitchedByIgnition" SG_ 945 DC_HYB_Abregelung_Temperatur 0;
BA_ "GenSigSendType" SG_ 945 DC_HYB_Abregelung_Temperatur 0;
BA_ "GenSigAutoGenSnd" SG_ 945 DC_HYB_Abregelung_Temperatur 1;
BA_ "GenSigAutoGenDsp" SG_ 945 DC_HYB_Abregelung_Temperatur 1;
BA_ "GenSigSwitchedByIgnition" SG_ 945 DC_HYB_Fehler_RedLeistung 0;
BA_ "GenSigSendType" SG_ 945 DC_HYB_Fehler_RedLeistung 0;
BA_ "GenSigAutoGenSnd" SG_ 945 DC_HYB_Fehler_RedLeistung 1;
BA_ "GenSigAutoGenDsp" SG_ 945 DC_HYB_Fehler_RedLeistung 1;
BA_ "GenSigSwitchedByIgnition" SG_ 945 DC_HYB_Fehler_intern 0;
BA_ "GenSigSendType" SG_ 945 DC_HYB_Fehler_intern 0;
BA_ "GenSigAutoGenSnd" SG_ 945 DC_HYB_Fehler_intern 1;
BA_ "GenSigAutoGenDsp" SG_ 945 DC_HYB_Fehler_intern 1;
BA_ "GenSigSwitchedByIgnition" SG_ 945 DC_HYB_Fehler_Spannung 0;
BA_ "GenSigSendType" SG_ 945 DC_HYB_Fehler_Spannung 0;
BA_ "GenSigAutoGenSnd" SG_ 945 DC_HYB_Fehler_Spannung 1;
BA_ "GenSigAutoGenDsp" SG_ 945 DC_HYB_Fehler_Spannung 1;
BA_ "Fehlerwert" SG_ 945 DC_HYB_Auslastungsgrad 255;
BA_ "GenSigStartValue" SG_ 945 DC_HYB_Auslastungsgrad 254;
BA_ "GenSigSendType" SG_ 945 DC_HYB_Auslastungsgrad 0;
BA_ "GenSigAutoGenSnd" SG_ 945 DC_HYB_Auslastungsgrad 1;
BA_ "GenSigAutoGenDsp" SG_ 945 DC_HYB_Auslastungsgrad 1;
BA_ "GenSigSwitchedByIgnition" SG_ 2617235968 DEV_BMS_Resp_00_Data 0;
BA_ "GenSigEnvVarType" SG_ 2617235968 DEV_BMS_Resp_00_Data 0;
BA_ "GenSigAutoGenSnd" SG_ 2617235968 DEV_BMS_Resp_00_Data 1;
BA_ "GenSigAutoGenDsp" SG_ 2617235968 DEV_BMS_Resp_00_Data 1;
BA_ "GenSigSwitchedByIgnition" SG_ 2617235969 DEV_BMS_Resp_01_Data 0;
BA_ "GenSigEnvVarType" SG_ 2617235969 DEV_BMS_Resp_01_Data 0;
BA_ "GenSigAutoGenSnd" SG_ 2617235969 DEV_BMS_Resp_01_Data 1;
BA_ "GenSigAutoGenDsp" SG_ 2617235969 DEV_BMS_Resp_01_Data 1;
BA_ "GenSigSwitchedByIgnition" SG_ 2617235970 DEV_BMS_Resp_02_Data 0;
BA_ "GenSigEnvVarType" SG_ 2617235970 DEV_BMS_Resp_02_Data 0;
BA_ "GenSigAutoGenSnd" SG_ 2617235970 DEV_BMS_Resp_02_Data 1;
BA_ "GenSigAutoGenDsp" SG_ 2617235970 DEV_BMS_Resp_02_Data 1;
BA_ "GenSigSwitchedByIgnition" SG_ 2617235971 DEV_BMS_Resp_03_Data 0;
BA_ "GenSigEnvVarType" SG_ 2617235971 DEV_BMS_Resp_03_Data 0;
BA_ "GenSigAutoGenSnd" SG_ 2617235971 DEV_BMS_Resp_03_Data 1;
BA_ "GenSigAutoGenDsp" SG_ 2617235971 DEV_BMS_Resp_03_Data 1;
BA_ "GenSigSwitchedByIgnition" SG_ 2617235972 DEV_BMS_Resp_04_Data 0;
BA_ "GenSigEnvVarType" SG_ 2617235972 DEV_BMS_Resp_04_Data 0;
BA_ "GenSigAutoGenSnd" SG_ 2617235972 DEV_BMS_Resp_04_Data 1;
BA_ "GenSigAutoGenDsp" SG_ 2617235972 DEV_BMS_Resp_04_Data 1;
BA_ "GenSigSwitchedByIgnition" SG_ 2617235973 DEV_BMS_Resp_05_Data 0;
BA_ "GenSigEnvVarType" SG_ 2617235973 DEV_BMS_Resp_05_Data 0;
BA_ "GenSigAutoGenSnd" SG_ 2617235973 DEV_BMS_Resp_05_Data 1;
BA_ "GenSigAutoGenDsp" SG_ 2617235973 DEV_BMS_Resp_05_Data 1;
BA_ "GenSigSwitchedByIgnition" SG_ 2617235974 DEV_BMS_Resp_06_Data 0;
BA_ "GenSigEnvVarType" SG_ 2617235974 DEV_BMS_Resp_06_Data 0;
BA_ "GenSigAutoGenSnd" SG_ 2617235974 DEV_BMS_Resp_06_Data 1;
BA_ "GenSigAutoGenDsp" SG_ 2617235974 DEV_BMS_Resp_06_Data 1;
BA_ "GenSigSwitchedByIgnition" SG_ 2617235975 DEV_BMS_Resp_07_Data 0;
BA_ "GenSigEnvVarType" SG_ 2617235975 DEV_BMS_Resp_07_Data 0;
BA_ "GenSigAutoGenSnd" SG_ 2617235975 DEV_BMS_Resp_07_Data 1;
BA_ "GenSigAutoGenDsp" SG_ 2617235975 DEV_BMS_Resp_07_Data 1;
BA_ "GenSigSwitchedByIgnition" SG_ 2617227776 DEV_Getriebe_Resp_00_Data 0;
BA_ "GenSigEnvVarType" SG_ 2617227776 DEV_Getriebe_Resp_00_Data 0;
BA_ "GenSigAutoGenSnd" SG_ 2617227776 DEV_Getriebe_Resp_00_Data 1;
BA_ "GenSigAutoGenDsp" SG_ 2617227776 DEV_Getriebe_Resp_00_Data 1;
BA_ "GenSigSwitchedByIgnition" SG_ 2617227777 DEV_Getriebe_Resp_01_Data 0;
BA_ "GenSigEnvVarType" SG_ 2617227777 DEV_Getriebe_Resp_01_Data 0;
BA_ "GenSigAutoGenSnd" SG_ 2617227777 DEV_Getriebe_Resp_01_Data 1;
BA_ "GenSigAutoGenDsp" SG_ 2617227777 DEV_Getriebe_Resp_01_Data 1;
BA_ "GenSigSwitchedByIgnition" SG_ 2617227778 DEV_Getriebe_Resp_02_Data 0;
BA_ "GenSigEnvVarType" SG_ 2617227778 DEV_Getriebe_Resp_02_Data 0;
BA_ "GenSigAutoGenSnd" SG_ 2617227778 DEV_Getriebe_Resp_02_Data 1;
BA_ "GenSigAutoGenDsp" SG_ 2617227778 DEV_Getriebe_Resp_02_Data 1;
BA_ "GenSigSwitchedByIgnition" SG_ 2617227779 DEV_Getriebe_Resp_03_Data 0;
BA_ "GenSigEnvVarType" SG_ 2617227779 DEV_Getriebe_Resp_03_Data 0;
BA_ "GenSigAutoGenSnd" SG_ 2617227779 DEV_Getriebe_Resp_03_Data 1;
BA_ "GenSigAutoGenDsp" SG_ 2617227779 DEV_Getriebe_Resp_03_Data 1;
BA_ "GenSigSwitchedByIgnition" SG_ 2617227780 DEV_Getriebe_Resp_04_Data 0;
BA_ "GenSigEnvVarType" SG_ 2617227780 DEV_Getriebe_Resp_04_Data 0;
BA_ "GenSigAutoGenSnd" SG_ 2617227780 DEV_Getriebe_Resp_04_Data 1;
BA_ "GenSigAutoGenDsp" SG_ 2617227780 DEV_Getriebe_Resp_04_Data 1;
BA_ "GenSigSwitchedByIgnition" SG_ 2617227781 DEV_Getriebe_Resp_05_Data 0;
BA_ "GenSigEnvVarType" SG_ 2617227781 DEV_Getriebe_Resp_05_Data 0;
BA_ "GenSigAutoGenSnd" SG_ 2617227781 DEV_Getriebe_Resp_05_Data 1;
BA_ "GenSigAutoGenDsp" SG_ 2617227781 DEV_Getriebe_Resp_05_Data 1;
BA_ "GenSigSwitchedByIgnition" SG_ 2617227782 DEV_Getriebe_Resp_06_Data 0;
BA_ "GenSigEnvVarType" SG_ 2617227782 DEV_Getriebe_Resp_06_Data 0;
BA_ "GenSigAutoGenSnd" SG_ 2617227782 DEV_Getriebe_Resp_06_Data 1;
BA_ "GenSigAutoGenDsp" SG_ 2617227782 DEV_Getriebe_Resp_06_Data 1;
BA_ "GenSigSwitchedByIgnition" SG_ 2617227783 DEV_Getriebe_Resp_07_Data 0;
BA_ "GenSigEnvVarType" SG_ 2617227783 DEV_Getriebe_Resp_07_Data 0;
BA_ "GenSigAutoGenSnd" SG_ 2617227783 DEV_Getriebe_Resp_07_Data 1;
BA_ "GenSigAutoGenDsp" SG_ 2617227783 DEV_Getriebe_Resp_07_Data 1;
BA_ "GenSigSwitchedByIgnition" SG_ 2617154048 DEV_Waehlhebel_Resp_00_Data 0;
BA_ "GenSigEnvVarType" SG_ 2617154048 DEV_Waehlhebel_Resp_00_Data 0;
BA_ "GenSigAutoGenSnd" SG_ 2617154048 DEV_Waehlhebel_Resp_00_Data 1;
BA_ "GenSigAutoGenDsp" SG_ 2617154048 DEV_Waehlhebel_Resp_00_Data 1;
BA_ "GenSigSwitchedByIgnition" SG_ 2617154049 DEV_Waehlhebel_Resp_01_Data 0;
BA_ "GenSigEnvVarType" SG_ 2617154049 DEV_Waehlhebel_Resp_01_Data 0;
BA_ "GenSigAutoGenSnd" SG_ 2617154049 DEV_Waehlhebel_Resp_01_Data 1;
BA_ "GenSigAutoGenDsp" SG_ 2617154049 DEV_Waehlhebel_Resp_01_Data 1;
BA_ "GenSigSwitchedByIgnition" SG_ 2617154050 DEV_Waehlhebel_Resp_02_Data 0;
BA_ "GenSigEnvVarType" SG_ 2617154050 DEV_Waehlhebel_Resp_02_Data 0;
BA_ "GenSigAutoGenSnd" SG_ 2617154050 DEV_Waehlhebel_Resp_02_Data 1;
BA_ "GenSigAutoGenDsp" SG_ 2617154050 DEV_Waehlhebel_Resp_02_Data 1;
BA_ "GenSigSwitchedByIgnition" SG_ 2617154051 DEV_Waehlhebel_Resp_03_Data 0;
BA_ "GenSigEnvVarType" SG_ 2617154051 DEV_Waehlhebel_Resp_03_Data 0;
BA_ "GenSigAutoGenSnd" SG_ 2617154051 DEV_Waehlhebel_Resp_03_Data 1;
BA_ "GenSigAutoGenDsp" SG_ 2617154051 DEV_Waehlhebel_Resp_03_Data 1;
BA_ "GenSigSwitchedByIgnition" SG_ 2617154052 DEV_Waehlhebel_Resp_04_Data 0;
BA_ "GenSigEnvVarType" SG_ 2617154052 DEV_Waehlhebel_Resp_04_Data 0;
BA_ "GenSigAutoGenSnd" SG_ 2617154052 DEV_Waehlhebel_Resp_04_Data 1;
BA_ "GenSigAutoGenDsp" SG_ 2617154052 DEV_Waehlhebel_Resp_04_Data 1;
BA_ "GenSigSwitchedByIgnition" SG_ 2617154053 DEV_Waehlhebel_Resp_05_Data 0;
BA_ "GenSigEnvVarType" SG_ 2617154053 DEV_Waehlhebel_Resp_05_Data 0;
BA_ "GenSigAutoGenSnd" SG_ 2617154053 DEV_Waehlhebel_Resp_05_Data 1;
BA_ "GenSigAutoGenDsp" SG_ 2617154053 DEV_Waehlhebel_Resp_05_Data 1;
BA_ "GenSigSwitchedByIgnition" SG_ 1714 DGN_Verlernzaehler 0;
BA_ "GenSigSendType" SG_ 1714 DGN_Verlernzaehler 0;
BA_ "GenSigEnvVarType" SG_ 1714 DGN_Verlernzaehler 0;
BA_ "GenSigAutoGenSnd" SG_ 1714 DGN_Verlernzaehler 1;
BA_ "GenSigAutoGenDsp" SG_ 1714 DGN_Verlernzaehler 1;
BA_ "Fehlerwert" SG_ 1714 KBI_Kilometerstand 1048575;
BA_ "GenSigSwitchedByIgnition" SG_ 1714 KBI_Kilometerstand 0;
BA_ "GenSigStartValue" SG_ 1714 KBI_Kilometerstand 1048574;
BA_ "GenSigSendType" SG_ 1714 KBI_Kilometerstand 0;
BA_ "GenSigEnvVarType" SG_ 1714 KBI_Kilometerstand 0;
BA_ "GenSigAutoGenSnd" SG_ 1714 KBI_Kilometerstand 1;
BA_ "GenSigAutoGenDsp" SG_ 1714 KBI_Kilometerstand 1;
BA_ "GenSigSwitchedByIgnition" SG_ 1714 UH_Jahr 0;
BA_ "GenSigSendType" SG_ 1714 UH_Jahr 0;
BA_ "GenSigEnvVarType" SG_ 1714 UH_Jahr 0;
BA_ "GenSigAutoGenSnd" SG_ 1714 UH_Jahr 1;
BA_ "GenSigAutoGenDsp" SG_ 1714 UH_Jahr 1;
BA_ "GenSigSwitchedByIgnition" SG_ 1714 UH_Monat 0;
BA_ "GenSigSendType" SG_ 1714 UH_Monat 0;
BA_ "GenSigEnvVarType" SG_ 1714 UH_Monat 0;
BA_ "GenSigAutoGenSnd" SG_ 1714 UH_Monat 1;
BA_ "GenSigAutoGenDsp" SG_ 1714 UH_Monat 1;
BA_ "GenSigSwitchedByIgnition" SG_ 1714 UH_Tag 0;
BA_ "GenSigSendType" SG_ 1714 UH_Tag 0;
BA_ "GenSigEnvVarType" SG_ 1714 UH_Tag 0;
BA_ "GenSigAutoGenSnd" SG_ 1714 UH_Tag 1;
BA_ "GenSigAutoGenDsp" SG_ 1714 UH_Tag 1;
BA_ "GenSigSwitchedByIgnition" SG_ 1714 UH_Stunde 0;
BA_ "GenSigSendType" SG_ 1714 UH_Stunde 0;
BA_ "GenSigEnvVarType" SG_ 1714 UH_Stunde 0;
BA_ "GenSigAutoGenSnd" SG_ 1714 UH_Stunde 1;
BA_ "GenSigAutoGenDsp" SG_ 1714 UH_Stunde 1;
BA_ "GenSigSwitchedByIgnition" SG_ 1714 UH_Minute 0;
BA_ "GenSigSendType" SG_ 1714 UH_Minute 0;
BA_ "GenSigEnvVarType" SG_ 1714 UH_Minute 0;
BA_ "GenSigAutoGenSnd" SG_ 1714 UH_Minute 1;
BA_ "GenSigAutoGenDsp" SG_ 1714 UH_Minute 1;
BA_ "GenSigSwitchedByIgnition" SG_ 1714 UH_Sekunde 0;
BA_ "GenSigSendType" SG_ 1714 UH_Sekunde 0;
BA_ "GenSigEnvVarType" SG_ 1714 UH_Sekunde 0;
BA_ "GenSigAutoGenSnd" SG_ 1714 UH_Sekunde 1;
BA_ "GenSigAutoGenDsp" SG_ 1714 UH_Sekunde 1;
BA_ "GenSigSwitchedByIgnition" SG_ 1714 Kombi_02_alt 0;
BA_ "GenSigFuncType" SG_ 1714 Kombi_02_alt 5;
BA_ "GenSigStartValue" SG_ 1714 Kombi_02_alt 1;
BA_ "GenSigSendType" SG_ 1714 Kombi_02_alt 0;
BA_ "GenSigEnvVarType" SG_ 1714 Kombi_02_alt 0;
BA_ "GenSigAutoGenSnd" SG_ 1714 Kombi_02_alt 1;
BA_ "GenSigAutoGenDsp" SG_ 1714 Kombi_02_alt 1;
BA_ "GenSigSwitchedByIgnition" SG_ 1714 Uhrzeit_01_alt 0;
BA_ "GenSigFuncType" SG_ 1714 Uhrzeit_01_alt 5;
BA_ "GenSigStartValue" SG_ 1714 Uhrzeit_01_alt 1;
BA_ "GenSigSendType" SG_ 1714 Uhrzeit_01_alt 0;
BA_ "GenSigEnvVarType" SG_ 1714 Uhrzeit_01_alt 0;
BA_ "GenSigAutoGenSnd" SG_ 1714 Uhrzeit_01_alt 1;
BA_ "GenSigAutoGenDsp" SG_ 1714 Uhrzeit_01_alt 1;
BA_ "Fehlerwert" SG_ 1520 DI_KL_58xd 255;
BA_ "GenSigSwitchedByIgnition" SG_ 1520 DI_KL_58xd 0;
BA_ "GenSigStartValue" SG_ 1520 DI_KL_58xd 254;
BA_ "GenSigSendType" SG_ 1520 DI_KL_58xd 3;
BA_ "GenSigEnvVarType" SG_ 1520 DI_KL_58xd 0;
BA_ "GenSigAutoGenSnd" SG_ 1520 DI_KL_58xd 1;
BA_ "GenSigAutoGenDsp" SG_ 1520 DI_KL_58xd 1;
BA_ "Fehlerwert" SG_ 1520 DI_KL_58xs 127;
BA_ "GenSigSwitchedByIgnition" SG_ 1520 DI_KL_58xs 0;
BA_ "GenSigStartValue" SG_ 1520 DI_KL_58xs 126;
BA_ "GenSigSendType" SG_ 1520 DI_KL_58xs 3;
BA_ "GenSigEnvVarType" SG_ 1520 DI_KL_58xs 0;
BA_ "GenSigAutoGenSnd" SG_ 1520 DI_KL_58xs 1;
BA_ "GenSigAutoGenDsp" SG_ 1520 DI_KL_58xs 1;
BA_ "GenSigSwitchedByIgnition" SG_ 1520 DI_Display_Nachtdesign 0;
BA_ "GenSigSendType" SG_ 1520 DI_Display_Nachtdesign 3;
BA_ "GenSigAutoGenSnd" SG_ 1520 DI_Display_Nachtdesign 1;
BA_ "GenSigAutoGenDsp" SG_ 1520 DI_Display_Nachtdesign 1;
BA_ "Fehlerwert" SG_ 1520 DI_KL_58xt 127;
BA_ "GenSigSwitchedByIgnition" SG_ 1520 DI_KL_58xt 0;
BA_ "GenSigStartValue" SG_ 1520 DI_KL_58xt 126;
BA_ "GenSigSendType" SG_ 1520 DI_KL_58xt 3;
BA_ "GenSigEnvVarType" SG_ 1520 DI_KL_58xt 0;
BA_ "GenSigAutoGenSnd" SG_ 1520 DI_KL_58xt 1;
BA_ "GenSigAutoGenDsp" SG_ 1520 DI_KL_58xt 1;
BA_ "GenSigSwitchedByIgnition" SG_ 1520 DI_Fotosensor 0;
BA_ "GenSigSendType" SG_ 1520 DI_Fotosensor 3;
BA_ "GenSigEnvVarType" SG_ 1520 DI_Fotosensor 0;
BA_ "GenSigAutoGenSnd" SG_ 1520 DI_Fotosensor 1;
BA_ "GenSigAutoGenDsp" SG_ 1520 DI_Fotosensor 1;
BA_ "GenSigSwitchedByIgnition" SG_ 1603 KBI_Einheit_Datum 0;
BA_ "GenSigSendType" SG_ 1603 KBI_Einheit_Datum 3;
BA_ "GenSigEnvVarType" SG_ 1603 KBI_Einheit_Datum 0;
BA_ "GenSigAutoGenSnd" SG_ 1603 KBI_Einheit_Datum 1;
BA_ "GenSigAutoGenDsp" SG_ 1603 KBI_Einheit_Datum 1;
BA_ "GenSigSwitchedByIgnition" SG_ 1603 KBI_Einheit_Druck 0;
BA_ "GenSigSendType" SG_ 1603 KBI_Einheit_Druck 3;
BA_ "GenSigEnvVarType" SG_ 1603 KBI_Einheit_Druck 0;
BA_ "GenSigAutoGenSnd" SG_ 1603 KBI_Einheit_Druck 1;
BA_ "GenSigAutoGenDsp" SG_ 1603 KBI_Einheit_Druck 1;
BA_ "GenSigSwitchedByIgnition" SG_ 1603 KBI_Einheit_Streckenanz 0;
BA_ "GenSigSendType" SG_ 1603 KBI_Einheit_Streckenanz 3;
BA_ "GenSigEnvVarType" SG_ 1603 KBI_Einheit_Streckenanz 0;
BA_ "GenSigAutoGenSnd" SG_ 1603 KBI_Einheit_Streckenanz 1;
BA_ "GenSigAutoGenDsp" SG_ 1603 KBI_Einheit_Streckenanz 1;
BA_ "GenSigSwitchedByIgnition" SG_ 1603 KBI_MFA_v_Einheit_02 0;
BA_ "GenSigSendType" SG_ 1603 KBI_MFA_v_Einheit_02 3;
BA_ "GenSigEnvVarType" SG_ 1603 KBI_MFA_v_Einheit_02 0;
BA_ "GenSigAutoGenSnd" SG_ 1603 KBI_MFA_v_Einheit_02 1;
BA_ "GenSigAutoGenDsp" SG_ 1603 KBI_MFA_v_Einheit_02 1;
BA_ "GenSigSwitchedByIgnition" SG_ 1603 KBI_Einheit_Temp 0;
BA_ "GenSigSendType" SG_ 1603 KBI_Einheit_Temp 3;
BA_ "GenSigEnvVarType" SG_ 1603 KBI_Einheit_Temp 0;
BA_ "GenSigAutoGenSnd" SG_ 1603 KBI_Einheit_Temp 1;
BA_ "GenSigAutoGenDsp" SG_ 1603 KBI_Einheit_Temp 1;
BA_ "GenSigSwitchedByIgnition" SG_ 1603 KBI_Einheit_Uhrzeit 0;
BA_ "GenSigSendType" SG_ 1603 KBI_Einheit_Uhrzeit 3;
BA_ "GenSigEnvVarType" SG_ 1603 KBI_Einheit_Uhrzeit 0;
BA_ "GenSigAutoGenSnd" SG_ 1603 KBI_Einheit_Uhrzeit 1;
BA_ "GenSigAutoGenDsp" SG_ 1603 KBI_Einheit_Uhrzeit 1;
BA_ "GenSigSwitchedByIgnition" SG_ 1603 KBI_Einheit_Verbrauch 0;
BA_ "GenSigSendType" SG_ 1603 KBI_Einheit_Verbrauch 3;
BA_ "GenSigEnvVarType" SG_ 1603 KBI_Einheit_Verbrauch 0;
BA_ "GenSigAutoGenSnd" SG_ 1603 KBI_Einheit_Verbrauch 1;
BA_ "GenSigAutoGenDsp" SG_ 1603 KBI_Einheit_Verbrauch 1;
BA_ "GenSigSwitchedByIgnition" SG_ 1603 KBI_Einheit_Volumen 0;
BA_ "GenSigSendType" SG_ 1603 KBI_Einheit_Volumen 3;
BA_ "GenSigEnvVarType" SG_ 1603 KBI_Einheit_Volumen 0;
BA_ "GenSigAutoGenSnd" SG_ 1603 KBI_Einheit_Volumen 1;
BA_ "GenSigAutoGenDsp" SG_ 1603 KBI_Einheit_Volumen 1;
BA_ "GenSigSwitchedByIgnition" SG_ 1603 KBI_Einheit_Sprache 0;
BA_ "GenSigSendType" SG_ 1603 KBI_Einheit_Sprache 3;
BA_ "GenSigEnvVarType" SG_ 1603 KBI_Einheit_Sprache 0;
BA_ "GenSigAutoGenSnd" SG_ 1603 KBI_Einheit_Sprache 1;
BA_ "GenSigAutoGenDsp" SG_ 1603 KBI_Einheit_Sprache 1;
BA_ "GenSigSwitchedByIgnition" SG_ 260 EPB_01_CRC 0;
BA_ "GenSigFuncType" SG_ 260 EPB_01_CRC 2;
BA_ "GenSigSendType" SG_ 260 EPB_01_CRC 0;
BA_ "GenSigEnvVarType" SG_ 260 EPB_01_CRC 0;
BA_ "GenSigAutoGenSnd" SG_ 260 EPB_01_CRC 1;
BA_ "GenSigAutoGenDsp" SG_ 260 EPB_01_CRC 1;
BA_ "GenSigSwitchedByIgnition" SG_ 260 EPB_01_BZ 0;
BA_ "GenSigFuncType" SG_ 260 EPB_01_BZ 1;
BA_ "GenSigSendType" SG_ 260 EPB_01_BZ 0;
BA_ "GenSigEnvVarType" SG_ 260 EPB_01_BZ 0;
BA_ "GenSigAutoGenSnd" SG_ 260 EPB_01_BZ 1;
BA_ "GenSigAutoGenDsp" SG_ 260 EPB_01_BZ 1;
BA_ "GenSigSwitchedByIgnition" SG_ 260 EPB_QBit_Laengsbeschleunigung 0;
BA_ "GenSigStartValue" SG_ 260 EPB_QBit_Laengsbeschleunigung 1;
BA_ "GenSigSendType" SG_ 260 EPB_QBit_Laengsbeschleunigung 0;
BA_ "GenSigEnvVarType" SG_ 260 EPB_QBit_Laengsbeschleunigung 0;
BA_ "GenSigAutoGenSnd" SG_ 260 EPB_QBit_Laengsbeschleunigung 1;
BA_ "GenSigAutoGenDsp" SG_ 260 EPB_QBit_Laengsbeschleunigung 1;
BA_ "GenSigSwitchedByIgnition" SG_ 260 EPB_QBit_Pedalweg_Kuppl 0;
BA_ "GenSigStartValue" SG_ 260 EPB_QBit_Pedalweg_Kuppl 1;
BA_ "GenSigSendType" SG_ 260 EPB_QBit_Pedalweg_Kuppl 0;
BA_ "GenSigEnvVarType" SG_ 260 EPB_QBit_Pedalweg_Kuppl 0;
BA_ "GenSigAutoGenSnd" SG_ 260 EPB_QBit_Pedalweg_Kuppl 1;
BA_ "GenSigAutoGenDsp" SG_ 260 EPB_QBit_Pedalweg_Kuppl 1;
BA_ "GenSigSwitchedByIgnition" SG_ 260 EPB_BCM2_Motor_Wakeup 0;
BA_ "GenSigSendType" SG_ 260 EPB_BCM2_Motor_Wakeup 0;
BA_ "GenSigEnvVarType" SG_ 260 EPB_BCM2_Motor_Wakeup 0;
BA_ "GenSigAutoGenSnd" SG_ 260 EPB_BCM2_Motor_Wakeup 1;
BA_ "GenSigAutoGenDsp" SG_ 260 EPB_BCM2_Motor_Wakeup 1;
BA_ "GenSigSwitchedByIgnition" SG_ 260 EPB_Freig_Verzoeg_Anf 0;
BA_ "GenSigSendType" SG_ 260 EPB_Freig_Verzoeg_Anf 0;
BA_ "GenSigEnvVarType" SG_ 260 EPB_Freig_Verzoeg_Anf 0;
BA_ "GenSigAutoGenSnd" SG_ 260 EPB_Freig_Verzoeg_Anf 1;
BA_ "GenSigAutoGenDsp" SG_ 260 EPB_Freig_Verzoeg_Anf 1;
BA_ "GenSigSwitchedByIgnition" SG_ 260 EPB_Verzoeg_Anf 0;
BA_ "GenSigStartValue" SG_ 260 EPB_Verzoeg_Anf 166;
BA_ "GenSigSendType" SG_ 260 EPB_Verzoeg_Anf 0;
BA_ "GenSigEnvVarType" SG_ 260 EPB_Verzoeg_Anf 1;
BA_ "GenSigAutoGenSnd" SG_ 260 EPB_Verzoeg_Anf 1;
BA_ "GenSigAutoGenDsp" SG_ 260 EPB_Verzoeg_Anf 1;
BA_ "Fehlerwert" SG_ 260 EPB_Laengsbeschleunigung 255;
BA_ "GenSigSwitchedByIgnition" SG_ 260 EPB_Laengsbeschleunigung 0;
BA_ "GenSigSendType" SG_ 260 EPB_Laengsbeschleunigung 0;
BA_ "GenSigEnvVarType" SG_ 260 EPB_Laengsbeschleunigung 0;
BA_ "GenSigAutoGenSnd" SG_ 260 EPB_Laengsbeschleunigung 1;
BA_ "GenSigAutoGenDsp" SG_ 260 EPB_Laengsbeschleunigung 1;
BA_ "Fehlerwert" SG_ 260 EPB_Pedalweg_Kuppl 255;
BA_ "GenSigSwitchedByIgnition" SG_ 260 EPB_Pedalweg_Kuppl 0;
BA_ "GenSigSendType" SG_ 260 EPB_Pedalweg_Kuppl 0;
BA_ "GenSigEnvVarType" SG_ 260 EPB_Pedalweg_Kuppl 1;
BA_ "GenSigAutoGenSnd" SG_ 260 EPB_Pedalweg_Kuppl 1;
BA_ "GenSigAutoGenDsp" SG_ 260 EPB_Pedalweg_Kuppl 1;
BA_ "GenSigSwitchedByIgnition" SG_ 260 EPB_Anfahrwunsch_erkannt 0;
BA_ "GenSigSendType" SG_ 260 EPB_Anfahrwunsch_erkannt 0;
BA_ "GenSigAutoGenSnd" SG_ 260 EPB_Anfahrwunsch_erkannt 1;
BA_ "GenSigAutoGenDsp" SG_ 260 EPB_Anfahrwunsch_erkannt 1;
BA_ "GenSigSwitchedByIgnition" SG_ 260 EPB_DAA_Randbed_erf 0;
BA_ "GenSigSendType" SG_ 260 EPB_DAA_Randbed_erf 0;
BA_ "GenSigAutoGenSnd" SG_ 260 EPB_DAA_Randbed_erf 1;
BA_ "GenSigAutoGenDsp" SG_ 260 EPB_DAA_Randbed_erf 1;
BA_ "GenSigSwitchedByIgnition" SG_ 260 EPB_Fehlerstatus 0;
BA_ "GenSigSendType" SG_ 260 EPB_Fehlerstatus 0;
BA_ "GenSigEnvVarType" SG_ 260 EPB_Fehlerstatus 0;
BA_ "GenSigAutoGenSnd" SG_ 260 EPB_Fehlerstatus 1;
BA_ "GenSigAutoGenDsp" SG_ 260 EPB_Fehlerstatus 1;
BA_ "Fehlerwert" SG_ 260 EPB_Schalterposition 3;
BA_ "GenSigSwitchedByIgnition" SG_ 260 EPB_Schalterposition 0;
BA_ "GenSigSendType" SG_ 260 EPB_Schalterposition 0;
BA_ "GenSigEnvVarType" SG_ 260 EPB_Schalterposition 0;
BA_ "GenSigAutoGenSnd" SG_ 260 EPB_Schalterposition 1;
BA_ "GenSigAutoGenDsp" SG_ 260 EPB_Schalterposition 1;
BA_ "GenSigSwitchedByIgnition" SG_ 260 EPB_QBit_Schalterpos 0;
BA_ "GenSigStartValue" SG_ 260 EPB_QBit_Schalterpos 1;
BA_ "GenSigSendType" SG_ 260 EPB_QBit_Schalterpos 0;
BA_ "GenSigEnvVarType" SG_ 260 EPB_QBit_Schalterpos 0;
BA_ "GenSigAutoGenSnd" SG_ 260 EPB_QBit_Schalterpos 1;
BA_ "GenSigAutoGenDsp" SG_ 260 EPB_QBit_Schalterpos 1;
BA_ "GenSigSwitchedByIgnition" SG_ 260 EPB_Konsistenz_ACC 0;
BA_ "GenSigSendType" SG_ 260 EPB_Konsistenz_ACC 0;
BA_ "GenSigEnvVarType" SG_ 260 EPB_Konsistenz_ACC 0;
BA_ "GenSigAutoGenSnd" SG_ 260 EPB_Konsistenz_ACC 1;
BA_ "GenSigAutoGenDsp" SG_ 260 EPB_Konsistenz_ACC 1;
BA_ "Fehlerwert" SG_ 260 EPB_Spannkraft 31;
BA_ "GenSigSwitchedByIgnition" SG_ 260 EPB_Spannkraft 0;
BA_ "GenSigStartValue" SG_ 260 EPB_Spannkraft 30;
BA_ "GenSigSendType" SG_ 260 EPB_Spannkraft 0;
BA_ "GenSigEnvVarType" SG_ 260 EPB_Spannkraft 0;
BA_ "GenSigAutoGenSnd" SG_ 260 EPB_Spannkraft 1;
BA_ "GenSigAutoGenDsp" SG_ 260 EPB_Spannkraft 1;
BA_ "GenSigSwitchedByIgnition" SG_ 260 EPB_Status 0;
BA_ "GenSigSendType" SG_ 260 EPB_Status 0;
BA_ "GenSigEnvVarType" SG_ 260 EPB_Status 0;
BA_ "GenSigAutoGenSnd" SG_ 260 EPB_Status 1;
BA_ "GenSigAutoGenDsp" SG_ 260 EPB_Status 1;
BA_ "GenSigSwitchedByIgnition" SG_ 257 ESP_02_CRC 0;
BA_ "GenSigFuncType" SG_ 257 ESP_02_CRC 2;
BA_ "GenSigSendType" SG_ 257 ESP_02_CRC 0;
BA_ "GenSigEnvVarType" SG_ 257 ESP_02_CRC 0;
BA_ "GenSigAutoGenSnd" SG_ 257 ESP_02_CRC 1;
BA_ "GenSigAutoGenDsp" SG_ 257 ESP_02_CRC 1;
BA_ "GenSigSwitchedByIgnition" SG_ 257 ESP_02_BZ 0;
BA_ "GenSigFuncType" SG_ 257 ESP_02_BZ 1;
BA_ "GenSigSendType" SG_ 257 ESP_02_BZ 0;
BA_ "GenSigEnvVarType" SG_ 257 ESP_02_BZ 0;
BA_ "GenSigAutoGenSnd" SG_ 257 ESP_02_BZ 1;
BA_ "GenSigAutoGenDsp" SG_ 257 ESP_02_BZ 1;
BA_ "GenSigSwitchedByIgnition" SG_ 257 ESP_QBit_Gierrate 0;
BA_ "GenSigStartValue" SG_ 257 ESP_QBit_Gierrate 1;
BA_ "GenSigSendType" SG_ 257 ESP_QBit_Gierrate 0;
BA_ "GenSigEnvVarType" SG_ 257 ESP_QBit_Gierrate 0;
BA_ "GenSigAutoGenSnd" SG_ 257 ESP_QBit_Gierrate 1;
BA_ "GenSigAutoGenDsp" SG_ 257 ESP_QBit_Gierrate 1;
BA_ "GenSigSwitchedByIgnition" SG_ 257 ESP_QBit_Laengsbeschl 0;
BA_ "GenSigStartValue" SG_ 257 ESP_QBit_Laengsbeschl 1;
BA_ "GenSigSendType" SG_ 257 ESP_QBit_Laengsbeschl 0;
BA_ "GenSigEnvVarType" SG_ 257 ESP_QBit_Laengsbeschl 0;
BA_ "GenSigAutoGenSnd" SG_ 257 ESP_QBit_Laengsbeschl 1;
BA_ "GenSigAutoGenDsp" SG_ 257 ESP_QBit_Laengsbeschl 1;
BA_ "GenSigSwitchedByIgnition" SG_ 257 ESP_QBit_Querb 0;
BA_ "GenSigStartValue" SG_ 257 ESP_QBit_Querb 1;
BA_ "GenSigSendType" SG_ 257 ESP_QBit_Querb 0;
BA_ "GenSigEnvVarType" SG_ 257 ESP_QBit_Querb 0;
BA_ "GenSigAutoGenSnd" SG_ 257 ESP_QBit_Querb 1;
BA_ "GenSigAutoGenDsp" SG_ 257 ESP_QBit_Querb 1;
BA_ "GenSigSwitchedByIgnition" SG_ 257 ESP_Stillstandsflag 0;
BA_ "GenSigSendType" SG_ 257 ESP_Stillstandsflag 0;
BA_ "GenSigEnvVarType" SG_ 257 ESP_Stillstandsflag 0;
BA_ "GenSigAutoGenSnd" SG_ 257 ESP_Stillstandsflag 1;
BA_ "GenSigAutoGenDsp" SG_ 257 ESP_Stillstandsflag 1;
BA_ "Fehlerwert" SG_ 257 ESP_Querbeschleunigung 255;
BA_ "GenSigSwitchedByIgnition" SG_ 257 ESP_Querbeschleunigung 0;
BA_ "GenSigStartValue" SG_ 257 ESP_Querbeschleunigung 127;
BA_ "GenSigSendType" SG_ 257 ESP_Querbeschleunigung 0;
BA_ "GenSigEnvVarType" SG_ 257 ESP_Querbeschleunigung 1;
BA_ "GenSigAutoGenSnd" SG_ 257 ESP_Querbeschleunigung 1;
BA_ "GenSigAutoGenDsp" SG_ 257 ESP_Querbeschleunigung 1;
BA_ "Fehlerwert" SG_ 257 ESP_Laengsbeschl 1023;
BA_ "GenSigSwitchedByIgnition" SG_ 257 ESP_Laengsbeschl 0;
BA_ "GenSigStartValue" SG_ 257 ESP_Laengsbeschl 512;
BA_ "GenSigSendType" SG_ 257 ESP_Laengsbeschl 0;
BA_ "GenSigEnvVarType" SG_ 257 ESP_Laengsbeschl 1;
BA_ "GenSigAutoGenSnd" SG_ 257 ESP_Laengsbeschl 1;
BA_ "GenSigAutoGenDsp" SG_ 257 ESP_Laengsbeschl 1;
BA_ "Fehlerwert" SG_ 257 ESP_Verteil_Wankmom 31;
BA_ "GenSigSwitchedByIgnition" SG_ 257 ESP_Verteil_Wankmom 0;
BA_ "GenSigStartValue" SG_ 257 ESP_Verteil_Wankmom 30;
BA_ "GenSigSendType" SG_ 257 ESP_Verteil_Wankmom 0;
BA_ "GenSigEnvVarType" SG_ 257 ESP_Verteil_Wankmom 1;
BA_ "GenSigAutoGenSnd" SG_ 257 ESP_Verteil_Wankmom 1;
BA_ "GenSigAutoGenDsp" SG_ 257 ESP_Verteil_Wankmom 1;
BA_ "GenSigSwitchedByIgnition" SG_ 257 ESP_QBit_Anf_Vert_Wank 0;
BA_ "GenSigStartValue" SG_ 257 ESP_QBit_Anf_Vert_Wank 1;
BA_ "GenSigSendType" SG_ 257 ESP_QBit_Anf_Vert_Wank 0;
BA_ "GenSigEnvVarType" SG_ 257 ESP_QBit_Anf_Vert_Wank 0;
BA_ "GenSigAutoGenSnd" SG_ 257 ESP_QBit_Anf_Vert_Wank 1;
BA_ "GenSigAutoGenDsp" SG_ 257 ESP_QBit_Anf_Vert_Wank 1;
BA_ "Fehlerwert" SG_ 257 ESP_Gierrate 16383;
BA_ "GenSigSwitchedByIgnition" SG_ 257 ESP_Gierrate 0;
BA_ "GenSigSendType" SG_ 257 ESP_Gierrate 0;
BA_ "GenSigEnvVarType" SG_ 257 ESP_Gierrate 1;
BA_ "GenSigAutoGenSnd" SG_ 257 ESP_Gierrate 1;
BA_ "GenSigAutoGenDsp" SG_ 257 ESP_Gierrate 1;
BA_ "GenSigSwitchedByIgnition" SG_ 257 ESP_VZ_Gierrate 0;
BA_ "GenSigSendType" SG_ 257 ESP_VZ_Gierrate 0;
BA_ "GenSigEnvVarType" SG_ 257 ESP_VZ_Gierrate 0;
BA_ "GenSigAutoGenSnd" SG_ 257 ESP_VZ_Gierrate 1;
BA_ "GenSigAutoGenDsp" SG_ 257 ESP_VZ_Gierrate 1;
BA_ "GenSigSwitchedByIgnition" SG_ 257 ESP_Notbremsanzeige 0;
BA_ "GenSigSendType" SG_ 257 ESP_Notbremsanzeige 0;
BA_ "GenSigEnvVarType" SG_ 257 ESP_Notbremsanzeige 0;
BA_ "GenSigAutoGenSnd" SG_ 257 ESP_Notbremsanzeige 1;
BA_ "GenSigAutoGenDsp" SG_ 257 ESP_Notbremsanzeige 1;
BA_ "GenSigSwitchedByIgnition" SG_ 257 ESP_SpannungsAnf 0;
BA_ "GenSigSendType" SG_ 257 ESP_SpannungsAnf 0;
BA_ "GenSigAutoGenSnd" SG_ 257 ESP_SpannungsAnf 1;
BA_ "GenSigAutoGenDsp" SG_ 257 ESP_SpannungsAnf 1;
BA_ "GenSigSwitchedByIgnition" SG_ 257 ESP_PLA_Abbruch 0;
BA_ "GenSigSendType" SG_ 257 ESP_PLA_Abbruch 0;
BA_ "GenSigSwitchedByIgnition" SG_ 257 ESP_Status_ESP_PLA 0;
BA_ "GenSigSendType" SG_ 257 ESP_Status_ESP_PLA 0;
BA_REL_ "GenSigTimeoutTime" BU_SG_REL_ Getriebe_DQ_Hybrid_MQB SG_ 290 ACC_06_CRC 500;
BA_REL_ "GenSigTimeoutTime" BU_SG_REL_ Getriebe_DQ_MQB SG_ 290 ACC_06_CRC 500;
BA_REL_ "GenSigTimeoutTime" BU_SG_REL_ Motor_Diesel_MQB SG_ 290 ACC_06_CRC 500;
BA_REL_ "GenSigTimeoutTime" BU_SG_REL_ Motor_Hybrid_MQB SG_ 290 ACC_06_CRC 500;
BA_REL_ "GenSigTimeoutTime" BU_SG_REL_ Motor_Otto_MQB SG_ 290 ACC_06_CRC 500;
BA_REL_ "GenSigTimeoutTime" BU_SG_REL_ Getriebe_DQ_Hybrid_MQB SG_ 290 ACC_06_BZ 500;
BA_REL_ "GenSigTimeoutTime" BU_SG_REL_ Getriebe_DQ_MQB SG_ 290 ACC_06_BZ 500;
BA_REL_ "GenSigTimeoutTime" BU_SG_REL_ Motor_Diesel_MQB SG_ 290 ACC_06_BZ 500;
BA_REL_ "GenSigTimeoutTime" BU_SG_REL_ Motor_Hybrid_MQB SG_ 290 ACC_06_BZ 500;
BA_REL_ "GenSigTimeoutTime" BU_SG_REL_ Motor_Otto_MQB SG_ 290 ACC_06_BZ 500;
BA_REL_ "GenSigTimeoutTime" BU_SG_REL_ Motor_Diesel_MQB SG_ 290 ACC_limitierte_Anfahrdyn 500;
BA_REL_ "GenSigTimeoutTime" BU_SG_REL_ Motor_Hybrid_MQB SG_ 290 ACC_limitierte_Anfahrdyn 500;
BA_REL_ "GenSigTimeoutTime" BU_SG_REL_ Motor_Otto_MQB SG_ 290 ACC_limitierte_Anfahrdyn 500;
BA_REL_ "GenSigTimeoutTime" BU_SG_REL_ Getriebe_DQ_Hybrid_MQB SG_ 290 ACC_zul_Regelabw_unten 500;
BA_REL_ "GenSigTimeoutTime" BU_SG_REL_ Getriebe_DQ_MQB SG_ 290 ACC_zul_Regelabw_unten 500;
BA_REL_ "GenSigTimeoutTime" BU_SG_REL_ Motor_Diesel_MQB SG_ 290 ACC_zul_Regelabw_unten 500;
BA_REL_ "GenSigTimeoutTime" BU_SG_REL_ Motor_Hybrid_MQB SG_ 290 ACC_zul_Regelabw_unten 500;
BA_REL_ "GenSigTimeoutTime" BU_SG_REL_ Motor_Otto_MQB SG_ 290 ACC_zul_Regelabw_unten 500;
BA_REL_ "GenSigTimeoutTime" BU_SG_REL_ Motor_Diesel_MQB SG_ 290 ACC_StartStopp_Info 500;
BA_REL_ "GenSigTimeoutTime" BU_SG_REL_ Motor_Otto_MQB SG_ 290 ACC_StartStopp_Info 500;
BA_REL_ "GenSigTimeoutTime" BU_SG_REL_ Getriebe_DQ_Hybrid_MQB SG_ 290 ACC_Sollbeschleunigung_02 500;
BA_REL_ "GenSigTimeoutTime" BU_SG_REL_ Getriebe_DQ_MQB SG_ 290 ACC_Sollbeschleunigung_02 500;
BA_REL_ "GenSigTimeoutTime" BU_SG_REL_ Motor_Diesel_MQB SG_ 290 ACC_Sollbeschleunigung_02 500;
BA_REL_ "GenSigTimeoutTime" BU_SG_REL_ Motor_Hybrid_MQB SG_ 290 ACC_Sollbeschleunigung_02 500;
BA_REL_ "GenSigTimeoutTime" BU_SG_REL_ Motor_Otto_MQB SG_ 290 ACC_Sollbeschleunigung_02 500;
BA_REL_ "GenSigTimeoutTime" BU_SG_REL_ Getriebe_DQ_Hybrid_MQB SG_ 290 ACC_zul_Regelabw_oben 500;
BA_REL_ "GenSigTimeoutTime" BU_SG_REL_ Getriebe_DQ_MQB SG_ 290 ACC_zul_Regelabw_oben 500;
BA_REL_ "GenSigTimeoutTime" BU_SG_REL_ Motor_Diesel_MQB SG_ 290 ACC_zul_Regelabw_oben 500;
BA_REL_ "GenSigTimeoutTime" BU_SG_REL_ Motor_Hybrid_MQB SG_ 290 ACC_zul_Regelabw_oben 500;
BA_REL_ "GenSigTimeoutTime" BU_SG_REL_ Motor_Otto_MQB SG_ 290 ACC_zul_Regelabw_oben 500;
BA_REL_ "GenSigTimeoutTime" BU_SG_REL_ Motor_Diesel_MQB SG_ 290 ACC_neg_Sollbeschl_Grad_02 500;
BA_REL_ "GenSigTimeoutTime" BU_SG_REL_ Motor_Hybrid_MQB SG_ 290 ACC_neg_Sollbeschl_Grad_02 500;
BA_REL_ "GenSigTimeoutTime" BU_SG_REL_ Motor_Otto_MQB SG_ 290 ACC_neg_Sollbeschl_Grad_02 500;
BA_REL_ "GenSigTimeoutTime" BU_SG_REL_ Motor_Diesel_MQB SG_ 290 ACC_pos_Sollbeschl_Grad_02 500;
BA_REL_ "GenSigTimeoutTime" BU_SG_REL_ Motor_Hybrid_MQB SG_ 290 ACC_pos_Sollbeschl_Grad_02 500;
BA_REL_ "GenSigTimeoutTime" BU_SG_REL_ Motor_Otto_MQB SG_ 290 ACC_pos_Sollbeschl_Grad_02 500;
BA_REL_ "GenSigTimeoutTime" BU_SG_REL_ Getriebe_DQ_Hybrid_MQB SG_ 290 ACC_Anfahren 500;
BA_REL_ "GenSigTimeoutTime" BU_SG_REL_ Getriebe_DQ_MQB SG_ 290 ACC_Anfahren 500;
BA_REL_ "GenSigTimeoutTime" BU_SG_REL_ Motor_Diesel_MQB SG_ 290 ACC_Anfahren 500;
BA_REL_ "GenSigTimeoutTime" BU_SG_REL_ Motor_Hybrid_MQB SG_ 290 ACC_Anfahren 500;
BA_REL_ "GenSigTimeoutTime" BU_SG_REL_ Motor_Otto_MQB SG_ 290 ACC_Anfahren 500;
BA_REL_ "GenSigTimeoutTime" BU_SG_REL_ Getriebe_DQ_Hybrid_MQB SG_ 290 ACC_Anhalten 500;
BA_REL_ "GenSigTimeoutTime" BU_SG_REL_ Getriebe_DQ_MQB SG_ 290 ACC_Anhalten 500;
BA_REL_ "GenSigTimeoutTime" BU_SG_REL_ Motor_Diesel_MQB SG_ 290 ACC_Anhalten 500;
BA_REL_ "GenSigTimeoutTime" BU_SG_REL_ Motor_Hybrid_MQB SG_ 290 ACC_Anhalten 500;
BA_REL_ "GenSigTimeoutTime" BU_SG_REL_ Motor_Otto_MQB SG_ 290 ACC_Anhalten 500;
BA_REL_ "GenSigTimeoutTime" BU_SG_REL_ Motor_Diesel_MQB SG_ 290 ACC_Typ 500;
BA_REL_ "GenSigTimeoutTime" BU_SG_REL_ Motor_Hybrid_MQB SG_ 290 ACC_Typ 500;
BA_REL_ "GenSigTimeoutTime" BU_SG_REL_ Motor_Otto_MQB SG_ 290 ACC_Typ 500;
BA_REL_ "GenSigTimeoutTime" BU_SG_REL_ Getriebe_DQ_Hybrid_MQB SG_ 290 ACC_Status_ACC 500;
BA_REL_ "GenSigTimeoutTime" BU_SG_REL_ Getriebe_DQ_MQB SG_ 290 ACC_Status_ACC 500;
BA_REL_ "GenSigTimeoutTime" BU_SG_REL_ Motor_Diesel_MQB SG_ 290 ACC_Status_ACC 500;
BA_REL_ "GenSigTimeoutTime" BU_SG_REL_ Motor_Hybrid_MQB SG_ 290 ACC_Status_ACC 500;
BA_REL_ "GenSigTimeoutTime" BU_SG_REL_ Motor_Otto_MQB SG_ 290 ACC_Status_ACC 500;
BA_REL_ "GenSigTimeoutTime" BU_SG_REL_ Motor_Diesel_MQB SG_ 290 ACC_Minimale_Bremsung 500;
BA_REL_ "GenSigTimeoutTime" BU_SG_REL_ Motor_Hybrid_MQB SG_ 290 ACC_Minimale_Bremsung 500;
BA_REL_ "GenSigTimeoutTime" BU_SG_REL_ Motor_Otto_MQB SG_ 290 ACC_Minimale_Bremsung 500;
BA_REL_ "GenSigTimeoutTime" BU_SG_REL_ Airbag_MQB SG_ 279 ACC_10_CRC 500;
BA_REL_ "GenSigTimeoutTime" BU_SG_REL_ Airbag_MQB SG_ 279 ACC_10_BZ 500;
BA_REL_ "GenSigTimeoutTime" BU_SG_REL_ Airbag_MQB SG_ 279 AWV1_Anf_Prefill 500;
BA_REL_ "GenSigTimeoutTime" BU_SG_REL_ Airbag_MQB SG_ 279 AWV2_Freigabe 500;
BA_REL_ "GenSigTimeoutTime" BU_SG_REL_ Airbag_MQB SG_ 279 ANB_CM_Anforderung 500;
BA_REL_ "GenSigTimeoutTime" BU_SG_REL_ Airbag_MQB SG_ 279 ANB_Teilbremsung_Freigabe 500;
BA_REL_ "GenSigTimeoutTime" BU_SG_REL_ Airbag_MQB SG_ 279 ANB_Zielbrems_Teilbrems_Verz_Anf 500;
BA_REL_ "GenSigTimeoutTime" BU_SG_REL_ Airbag_MQB SG_ 279 ANB_Zielbremsung_Freigabe 500;
BA_REL_ "GenSigTimeoutTime" BU_SG_REL_ BMS_MQB SG_ 64 Airbag_01_CRC 500;
BA_REL_ "GenSigTimeoutTime" BU_SG_REL_ LEH_MQB SG_ 64 Airbag_01_CRC 500;
BA_REL_ "GenSigTimeoutTime" BU_SG_REL_ Motor_Diesel_MQB SG_ 64 Airbag_01_CRC 500;
BA_REL_ "GenSigTimeoutTime" BU_SG_REL_ Motor_Diesel_MQB SG_ 64 Airbag_01_CRC 500;
BA_REL_ "GenSigTimeoutTime" BU_SG_REL_ Motor_Hybrid_MQB SG_ 64 Airbag_01_CRC 500;
BA_REL_ "GenSigTimeoutTime" BU_SG_REL_ Motor_Hybrid_MQB SG_ 64 Airbag_01_CRC 500;
BA_REL_ "GenSigTimeoutTime" BU_SG_REL_ Motor_Otto_MQB SG_ 64 Airbag_01_CRC 500;
BA_REL_ "GenSigTimeoutTime" BU_SG_REL_ Motor_Otto_MQB SG_ 64 Airbag_01_CRC 500;
BA_REL_ "GenSigTimeoutTime" BU_SG_REL_ BMS_MQB SG_ 64 Airbag_01_BZ 500;
BA_REL_ "GenSigTimeoutTime" BU_SG_REL_ LEH_MQB SG_ 64 Airbag_01_BZ 500;
BA_REL_ "GenSigTimeoutTime" BU_SG_REL_ Motor_Diesel_MQB SG_ 64 Airbag_01_BZ 500;
BA_REL_ "GenSigTimeoutTime" BU_SG_REL_ Motor_Diesel_MQB SG_ 64 Airbag_01_BZ 500;
BA_REL_ "GenSigTimeoutTime" BU_SG_REL_ Motor_Hybrid_MQB SG_ 64 Airbag_01_BZ 500;
BA_REL_ "GenSigTimeoutTime" BU_SG_REL_ Motor_Hybrid_MQB SG_ 64 Airbag_01_BZ 500;
BA_REL_ "GenSigTimeoutTime" BU_SG_REL_ Motor_Otto_MQB SG_ 64 Airbag_01_BZ 500;
BA_REL_ "GenSigTimeoutTime" BU_SG_REL_ Motor_Otto_MQB SG_ 64 Airbag_01_BZ 500;
BA_REL_ "GenSigTimeoutTime" BU_SG_REL_ BMS_MQB SG_ 64 AB_Crash_Int 500;
BA_REL_ "GenSigTimeoutTime" BU_SG_REL_ LEH_MQB SG_ 64 AB_Crash_Int 500;
BA_REL_ "GenSigTimeoutTime" BU_SG_REL_ Motor_Diesel_MQB SG_ 64 AB_Crash_Int 500;
BA_REL_ "GenSigTimeoutTime" BU_SG_REL_ Motor_Diesel_MQB SG_ 64 AB_Crash_Int 500;
BA_REL_ "GenSigTimeoutTime" BU_SG_REL_ Motor_Hybrid_MQB SG_ 64 AB_Crash_Int 500;
BA_REL_ "GenSigTimeoutTime" BU_SG_REL_ Motor_Hybrid_MQB SG_ 64 AB_Crash_Int 500;
BA_REL_ "GenSigTimeoutTime" BU_SG_REL_ Motor_Otto_MQB SG_ 64 AB_Crash_Int 500;
BA_REL_ "GenSigTimeoutTime" BU_SG_REL_ Motor_Otto_MQB SG_ 64 AB_Crash_Int 500;
BA_REL_ "GenSigTimeoutTime" BU_SG_REL_ BMS_MQB SG_ 64 AB_Systemfehler 500;
BA_REL_ "GenSigTimeoutTime" BU_SG_REL_ LEH_MQB SG_ 64 AB_Systemfehler 500;
BA_REL_ "GenSigTimeoutTime" BU_SG_REL_ BMS_MQB SG_ 64 AB_Stellgliedtest 500;
BA_REL_ "GenSigTimeoutTime" BU_SG_REL_ Motor_Diesel_MQB SG_ 64 AB_Stellgliedtest 500;
BA_REL_ "GenSigTimeoutTime" BU_SG_REL_ Motor_Hybrid_MQB SG_ 64 AB_Stellgliedtest 500;
BA_REL_ "GenSigTimeoutTime" BU_SG_REL_ Motor_Otto_MQB SG_ 64 AB_Stellgliedtest 500;
BA_REL_ "GenSigTimeoutTime" BU_SG_REL_ Gateway_MQB SG_ 1312 AB_Gurtschloss_FA 2000;
BA_REL_ "GenSigTimeoutTime" BU_SG_REL_ Gateway_MQB SG_ 1312 AB_Gurtschloss_FA 2000;
BA_REL_ "GenSigTimeoutTime" BU_SG_REL_ Motor_Diesel_MQB SG_ 1312 AB_Gurtschloss_FA 2000;
BA_REL_ "GenSigTimeoutTime" BU_SG_REL_ Motor_Otto_MQB SG_ 1312 AB_Gurtschloss_FA 2000;
BA_REL_ "GenSigTimeoutTime" BU_SG_REL_ Motor_Diesel_MQB SG_ 1633 AAG_BZ 1000;
BA_REL_ "GenSigTimeoutTime" BU_SG_REL_ Motor_Hybrid_MQB SG_ 1633 AAG_BZ 1000;
BA_REL_ "GenSigTimeoutTime" BU_SG_REL_ Motor_Otto_MQB SG_ 1633 AAG_BZ 1000;
BA_REL_ "GenSigTimeoutTime" BU_SG_REL_ Motor_Diesel_MQB SG_ 1633 AAG_Bremsl_durch_ECD 1000;
BA_REL_ "GenSigTimeoutTime" BU_SG_REL_ Motor_Hybrid_MQB SG_ 1633 AAG_Bremsl_durch_ECD 1000;
BA_REL_ "GenSigTimeoutTime" BU_SG_REL_ Motor_Otto_MQB SG_ 1633 AAG_Bremsl_durch_ECD 1000;
BA_REL_ "GenSigTimeoutTime" BU_SG_REL_ Motor_Diesel_MQB SG_ 1633 AAG_Anhaenger_erkannt 1000;
BA_REL_ "GenSigTimeoutTime" BU_SG_REL_ Motor_Hybrid_MQB SG_ 1633 AAG_Anhaenger_erkannt 1000;
BA_REL_ "GenSigTimeoutTime" BU_SG_REL_ Motor_Otto_MQB SG_ 1633 AAG_Anhaenger_erkannt 1000;
BA_REL_ "GenSigTimeoutTime" BU_SG_REL_ Motor_Diesel_MQB SG_ 1633 AAG_Bremslicht_H_def 1000;
BA_REL_ "GenSigTimeoutTime" BU_SG_REL_ Motor_Hybrid_MQB SG_ 1633 AAG_Bremslicht_H_def 1000;
BA_REL_ "GenSigTimeoutTime" BU_SG_REL_ Motor_Otto_MQB SG_ 1633 AAG_Bremslicht_H_def 1000;
BA_REL_ "GenSigTimeoutTime" BU_SG_REL_ Motor_Diesel_MQB SG_ 1626 BCM_Kuehlmittel_Sensor 5000;
BA_REL_ "GenSigTimeoutTime" BU_SG_REL_ Motor_Otto_MQB SG_ 1626 BCM_Kuehlmittel_Sensor 5000;
BA_REL_ "GenSigTimeoutTime" BU_SG_REL_ Getriebe_DQ_Hybrid_MQB SG_ 1626 BCM_Eis_Offroad_Taste 5000;
BA_REL_ "GenSigTimeoutTime" BU_SG_REL_ Getriebe_DQ_MQB SG_ 1626 BCM_Eis_Offroad_Taste 5000;
BA_REL_ "GenSigTimeoutTime" BU_SG_REL_ Motor_Diesel_MQB SG_ 1626 BCM_Eis_Offroad_Taste 5000;
BA_REL_ "GenSigTimeoutTime" BU_SG_REL_ Motor_Otto_MQB SG_ 1626 BCM_Eis_Offroad_Taste 5000;
BA_REL_ "GenSigTimeoutTime" BU_SG_REL_ Getriebe_DQ_Hybrid_MQB SG_ 1626 BCM_Hybrid_StartStopp_Taste 5000;
BA_REL_ "GenSigTimeoutTime" BU_SG_REL_ Getriebe_DQ_MQB SG_ 1626 BCM_Hybrid_StartStopp_Taste 5000;
BA_REL_ "GenSigTimeoutTime" BU_SG_REL_ Motor_Diesel_MQB SG_ 1626 BCM_Hybrid_StartStopp_Taste 5000;
BA_REL_ "GenSigTimeoutTime" BU_SG_REL_ Motor_Hybrid_MQB SG_ 1626 BCM_Hybrid_StartStopp_Taste 5000;
BA_REL_ "GenSigTimeoutTime" BU_SG_REL_ Motor_Otto_MQB SG_ 1626 BCM_Hybrid_StartStopp_Taste 5000;
BA_REL_ "GenSigTimeoutTime" BU_SG_REL_ Motor_Diesel_MQB SG_ 1626 BCM_Remotestart_Betrieb 5000;
BA_REL_ "GenSigTimeoutTime" BU_SG_REL_ Motor_Otto_MQB SG_ 1626 BCM_Remotestart_Betrieb 5000;
BA_REL_ "GenSigTimeoutTime" BU_SG_REL_ Getriebe_DQ_Hybrid_MQB SG_ 1626 BCM1_Rueckfahrlicht_Schalter 5000;
BA_REL_ "GenSigTimeoutTime" BU_SG_REL_ Getriebe_DQ_MQB SG_ 1626 BCM1_Rueckfahrlicht_Schalter 5000;
BA_REL_ "GenSigTimeoutTime" BU_SG_REL_ Motor_Diesel_MQB SG_ 1626 BCM1_Rueckfahrlicht_Schalter 5000;
BA_REL_ "GenSigTimeoutTime" BU_SG_REL_ Motor_Hybrid_MQB SG_ 1626 BCM1_Rueckfahrlicht_Schalter 5000;
BA_REL_ "GenSigTimeoutTime" BU_SG_REL_ Motor_Otto_MQB SG_ 1626 BCM1_Rueckfahrlicht_Schalter 5000;
BA_REL_ "GenSigTimeoutTime" BU_SG_REL_ Motor_Diesel_MQB SG_ 1626 BCM1_MH_Schalter 5000;
BA_REL_ "GenSigTimeoutTime" BU_SG_REL_ Motor_Otto_MQB SG_ 1626 BCM1_MH_Schalter 5000;
BA_REL_ "GenSigTimeoutTime" BU_SG_REL_ Motor_Diesel_MQB SG_ 1626 BCM1_MH_WIV_Schalter 5000;
BA_REL_ "GenSigTimeoutTime" BU_SG_REL_ Motor_Hybrid_MQB SG_ 1626 BCM1_MH_WIV_Schalter 5000;
BA_REL_ "GenSigTimeoutTime" BU_SG_REL_ Motor_Otto_MQB SG_ 1626 BCM1_MH_WIV_Schalter 5000;
BA_REL_ "GenSigTimeoutTime" BU_SG_REL_ Getriebe_DQ_Hybrid_MQB SG_ 1626 BCM_Eco_Charisma_Taste 5000;
BA_REL_ "GenSigTimeoutTime" BU_SG_REL_ Getriebe_DQ_MQB SG_ 1626 BCM_Eco_Charisma_Taste 5000;
BA_REL_ "GenSigTimeoutTime" BU_SG_REL_ Motor_Diesel_MQB SG_ 1626 BCM_Thermomanagement 5000;
BA_REL_ "GenSigTimeoutTime" BU_SG_REL_ Motor_Hybrid_MQB SG_ 1626 BCM_Thermomanagement 5000;
BA_REL_ "GenSigTimeoutTime" BU_SG_REL_ Motor_Otto_MQB SG_ 1626 BCM_Thermomanagement 5000;
BA_REL_ "GenSigTimeoutTime" BU_SG_REL_ Motor_Diesel_MQB SG_ 1626 BCM_Thermomanagement_Fehler 5000;
BA_REL_ "GenSigTimeoutTime" BU_SG_REL_ Motor_Hybrid_MQB SG_ 1626 BCM_Thermomanagement_Fehler 5000;
BA_REL_ "GenSigTimeoutTime" BU_SG_REL_ Motor_Otto_MQB SG_ 1626 BCM_Thermomanagement_Fehler 5000;
BA_REL_ "GenSigTimeoutTime" BU_SG_REL_ Motor_Diesel_MQB SG_ 1626 BCM_Thermomanagement_gueltig 5000;
BA_REL_ "GenSigTimeoutTime" BU_SG_REL_ Motor_Hybrid_MQB SG_ 1626 BCM_Thermomanagement_gueltig 5000;
BA_REL_ "GenSigTimeoutTime" BU_SG_REL_ Motor_Otto_MQB SG_ 1626 BCM_Thermomanagement_gueltig 5000;
BA_REL_ "GenSigTimeoutTime" BU_SG_REL_ Motor_Diesel_MQB SG_ 869 BEM_P_Generator 500;
BA_REL_ "GenSigTimeoutTime" BU_SG_REL_ Motor_Hybrid_MQB SG_ 869 BEM_P_Generator 500;
BA_REL_ "GenSigTimeoutTime" BU_SG_REL_ Motor_Otto_MQB SG_ 869 BEM_P_Generator 500;
BA_REL_ "GenSigTimeoutTime" BU_SG_REL_ Motor_Diesel_MQB SG_ 869 BEM_n_LLA 500;
BA_REL_ "GenSigTimeoutTime" BU_SG_REL_ Motor_Hybrid_MQB SG_ 869 BEM_n_LLA 500;
BA_REL_ "GenSigTimeoutTime" BU_SG_REL_ Motor_Otto_MQB SG_ 869 BEM_n_LLA 500;
BA_REL_ "GenSigTimeoutTime" BU_SG_REL_ Motor_Diesel_MQB SG_ 869 BEM_01_Abschaltstufen 500;
BA_REL_ "GenSigTimeoutTime" BU_SG_REL_ Motor_Hybrid_MQB SG_ 869 BEM_01_Abschaltstufen 500;
BA_REL_ "GenSigTimeoutTime" BU_SG_REL_ Motor_Otto_MQB SG_ 869 BEM_01_Abschaltstufen 500;
BA_REL_ "GenSigTimeoutTime" BU_SG_REL_ Motor_Diesel_MQB SG_ 869 BEM_Anf_KL 500;
BA_REL_ "GenSigTimeoutTime" BU_SG_REL_ Motor_Hybrid_MQB SG_ 869 BEM_Anf_KL 500;
BA_REL_ "GenSigTimeoutTime" BU_SG_REL_ Motor_Otto_MQB SG_ 869 BEM_Anf_KL 500;
BA_REL_ "GenSigTimeoutTime" BU_SG_REL_ Motor_Diesel_MQB SG_ 869 BEM_StartStopp_Info 500;
BA_REL_ "GenSigTimeoutTime" BU_SG_REL_ Motor_Otto_MQB SG_ 869 BEM_StartStopp_Info 500;
BA_REL_ "GenSigTimeoutTime" BU_SG_REL_ Motor_Diesel_MQB SG_ 869 BEM_DFM 500;
BA_REL_ "GenSigTimeoutTime" BU_SG_REL_ Motor_Hybrid_MQB SG_ 869 BEM_DFM 500;
BA_REL_ "GenSigTimeoutTime" BU_SG_REL_ Motor_Otto_MQB SG_ 869 BEM_DFM 500;
BA_REL_ "GenSigTimeoutTime" BU_SG_REL_ Motor_Diesel_MQB SG_ 869 BEM_EMLIN_ungueltig 500;
BA_REL_ "GenSigTimeoutTime" BU_SG_REL_ Motor_Hybrid_MQB SG_ 869 BEM_EMLIN_ungueltig 500;
BA_REL_ "GenSigTimeoutTime" BU_SG_REL_ Motor_Otto_MQB SG_ 869 BEM_EMLIN_ungueltig 500;
BA_REL_ "GenSigTimeoutTime" BU_SG_REL_ Motor_Diesel_MQB SG_ 869 BEM_Batt_Ab 500;
BA_REL_ "GenSigTimeoutTime" BU_SG_REL_ Motor_Hybrid_MQB SG_ 869 BEM_Batt_Ab 500;
BA_REL_ "GenSigTimeoutTime" BU_SG_REL_ Motor_Otto_MQB SG_ 869 BEM_Batt_Ab 500;
BA_REL_ "GenSigTimeoutTime" BU_SG_REL_ Getriebe_DQ_Hybrid_MQB SG_ 869 BEM_Segel_Info 500;
BA_REL_ "GenSigTimeoutTime" BU_SG_REL_ Getriebe_DQ_MQB SG_ 869 BEM_Segel_Info 500;
BA_REL_ "GenSigTimeoutTime" BU_SG_REL_ Motor_Diesel_MQB SG_ 869 BEM_Segel_Info 500;
BA_REL_ "GenSigTimeoutTime" BU_SG_REL_ Motor_Hybrid_MQB SG_ 869 BEM_Segel_Info 500;
BA_REL_ "GenSigTimeoutTime" BU_SG_REL_ Motor_Otto_MQB SG_ 869 BEM_Segel_Info 500;
BA_REL_ "GenSigTimeoutTime" BU_SG_REL_ LEH_MQB SG_ 869 BEM_HYB_DC_uSollLV 500;
BA_REL_ "GenSigTimeoutTime" BU_SG_REL_ LEH_MQB SG_ 869 BEM_HYB_DC_uMinLV 500;
BA_REL_ "GenSigTimeoutTime" BU_SG_REL_ Airbag_MQB SG_ 901 CHA_Fahrer_Umschaltung 5000;
BA_REL_ "GenSigTimeoutTime" BU_SG_REL_ Getriebe_DQ_Hybrid_MQB SG_ 901 CHA_Fahrer_Umschaltung 5000;
BA_REL_ "GenSigTimeoutTime" BU_SG_REL_ Getriebe_DQ_MQB SG_ 901 CHA_Fahrer_Umschaltung 5000;
BA_REL_ "GenSigTimeoutTime" BU_SG_REL_ Motor_Diesel_MQB SG_ 901 CHA_Fahrer_Umschaltung 5000;
BA_REL_ "GenSigTimeoutTime" BU_SG_REL_ Motor_Hybrid_MQB SG_ 901 CHA_Fahrer_Umschaltung 5000;
BA_REL_ "GenSigTimeoutTime" BU_SG_REL_ Motor_Otto_MQB SG_ 901 CHA_Fahrer_Umschaltung 5000;
BA_REL_ "GenSigTimeoutTime" BU_SG_REL_ SAK_MQB SG_ 901 CHA_Fahrer_Umschaltung 5000;
BA_REL_ "GenSigTimeoutTime" BU_SG_REL_ Motor_Diesel_MQB SG_ 901 CHA_Ziel_FahrPr_MO 5000;
BA_REL_ "GenSigTimeoutTime" BU_SG_REL_ Motor_Hybrid_MQB SG_ 901 CHA_Ziel_FahrPr_MO 5000;
BA_REL_ "GenSigTimeoutTime" BU_SG_REL_ Motor_Otto_MQB SG_ 901 CHA_Ziel_FahrPr_MO 5000;
BA_REL_ "GenSigTimeoutTime" BU_SG_REL_ Getriebe_DQ_Hybrid_MQB SG_ 901 CHA_Ziel_FahrPr_GE 5000;
BA_REL_ "GenSigTimeoutTime" BU_SG_REL_ Getriebe_DQ_MQB SG_ 901 CHA_Ziel_FahrPr_GE 5000;
BA_REL_ "GenSigTimeoutTime" BU_SG_REL_ Airbag_MQB SG_ 901 CHA_Ziel_FahrPr_RGS 5000;
BA_REL_ "GenSigTimeoutTime" BU_SG_REL_ SAK_MQB SG_ 901 CHA_Ziel_FahrPr_SAK 5000;
BA_REL_ "GenSigTimeoutTime" BU_SG_REL_ Gateway_MQB SG_ 945 DC_HYB_iAktLV 1000;
BA_REL_ "GenSigTimeoutTime" BU_SG_REL_ Gateway_MQB SG_ 945 DC_HYB_iAktReserveLV 1000;
BA_REL_ "GenSigTimeoutTime" BU_SG_REL_ Gateway_MQB SG_ 945 DC_HYB_uAktLV 1000;
BA_REL_ "GenSigTimeoutTime" BU_SG_REL_ Gateway_MQB SG_ 945 DC_HYB_LangsRegelung 1000;
BA_REL_ "GenSigTimeoutTime" BU_SG_REL_ Gateway_MQB SG_ 945 DC_HYB_Abregelung_Temperatur 1000;
BA_REL_ "GenSigTimeoutTime" BU_SG_REL_ Gateway_MQB SG_ 945 DC_HYB_Fehler_RedLeistung 1000;
BA_REL_ "GenSigTimeoutTime" BU_SG_REL_ Gateway_MQB SG_ 945 DC_HYB_Fehler_intern 1000;
BA_REL_ "GenSigTimeoutTime" BU_SG_REL_ Gateway_MQB SG_ 945 DC_HYB_Fehler_Spannung 1000;
BA_REL_ "GenSigTimeoutTime" BU_SG_REL_ Gateway_MQB SG_ 945 DC_HYB_Auslastungsgrad 1000;
BA_REL_ "GenSigTimeoutTime" BU_SG_REL_ Airbag_MQB SG_ 1714 DGN_Verlernzaehler 5000;
BA_REL_ "GenSigTimeoutTime" BU_SG_REL_ BMS_MQB SG_ 1714 DGN_Verlernzaehler 5000;
BA_REL_ "GenSigTimeoutTime" BU_SG_REL_ Getriebe_DQ_Hybrid_MQB SG_ 1714 DGN_Verlernzaehler 5000;
BA_REL_ "GenSigTimeoutTime" BU_SG_REL_ Getriebe_DQ_MQB SG_ 1714 DGN_Verlernzaehler 5000;
BA_REL_ "GenSigTimeoutTime" BU_SG_REL_ LEH_MQB SG_ 1714 DGN_Verlernzaehler 5000;
BA_REL_ "GenSigTimeoutTime" BU_SG_REL_ SAK_MQB SG_ 1714 DGN_Verlernzaehler 5000;
BA_REL_ "GenSigTimeoutTime" BU_SG_REL_ Airbag_MQB SG_ 1714 KBI_Kilometerstand 5000;
BA_REL_ "GenSigTimeoutTime" BU_SG_REL_ BMS_MQB SG_ 1714 KBI_Kilometerstand 5000;
BA_REL_ "GenSigTimeoutTime" BU_SG_REL_ Getriebe_DQ_Hybrid_MQB SG_ 1714 KBI_Kilometerstand 5000;
BA_REL_ "GenSigTimeoutTime" BU_SG_REL_ Getriebe_DQ_MQB SG_ 1714 KBI_Kilometerstand 5000;
BA_REL_ "GenSigTimeoutTime" BU_SG_REL_ LEH_MQB SG_ 1714 KBI_Kilometerstand 5000;
BA_REL_ "GenSigTimeoutTime" BU_SG_REL_ Motor_Diesel_MQB SG_ 1714 KBI_Kilometerstand 5000;
BA_REL_ "GenSigTimeoutTime" BU_SG_REL_ Motor_Hybrid_MQB SG_ 1714 KBI_Kilometerstand 5000;
BA_REL_ "GenSigTimeoutTime" BU_SG_REL_ Motor_Otto_MQB SG_ 1714 KBI_Kilometerstand 5000;
BA_REL_ "GenSigTimeoutTime" BU_SG_REL_ SAK_MQB SG_ 1714 KBI_Kilometerstand 5000;
BA_REL_ "GenSigTimeoutTime" BU_SG_REL_ Airbag_MQB SG_ 1714 UH_Jahr 5000;
BA_REL_ "GenSigTimeoutTime" BU_SG_REL_ BMS_MQB SG_ 1714 UH_Jahr 5000;
BA_REL_ "GenSigTimeoutTime" BU_SG_REL_ Getriebe_DQ_Hybrid_MQB SG_ 1714 UH_Jahr 5000;
BA_REL_ "GenSigTimeoutTime" BU_SG_REL_ Getriebe_DQ_MQB SG_ 1714 UH_Jahr 5000;
BA_REL_ "GenSigTimeoutTime" BU_SG_REL_ LEH_MQB SG_ 1714 UH_Jahr 5000;
BA_REL_ "GenSigTimeoutTime" BU_SG_REL_ Motor_Diesel_MQB SG_ 1714 UH_Jahr 5000;
BA_REL_ "GenSigTimeoutTime" BU_SG_REL_ Motor_Hybrid_MQB SG_ 1714 UH_Jahr 5000;
BA_REL_ "GenSigTimeoutTime" BU_SG_REL_ Motor_Otto_MQB SG_ 1714 UH_Jahr 5000;
BA_REL_ "GenSigTimeoutTime" BU_SG_REL_ SAK_MQB SG_ 1714 UH_Jahr 5000;
BA_REL_ "GenSigTimeoutTime" BU_SG_REL_ Airbag_MQB SG_ 1714 UH_Monat 5000;
BA_REL_ "GenSigTimeoutTime" BU_SG_REL_ BMS_MQB SG_ 1714 UH_Monat 5000;
BA_REL_ "GenSigTimeoutTime" BU_SG_REL_ Getriebe_DQ_Hybrid_MQB SG_ 1714 UH_Monat 5000;
BA_REL_ "GenSigTimeoutTime" BU_SG_REL_ Getriebe_DQ_MQB SG_ 1714 UH_Monat 5000;
BA_REL_ "GenSigTimeoutTime" BU_SG_REL_ LEH_MQB SG_ 1714 UH_Monat 5000;
BA_REL_ "GenSigTimeoutTime" BU_SG_REL_ Motor_Diesel_MQB SG_ 1714 UH_Monat 5000;
BA_REL_ "GenSigTimeoutTime" BU_SG_REL_ Motor_Hybrid_MQB SG_ 1714 UH_Monat 5000;
BA_REL_ "GenSigTimeoutTime" BU_SG_REL_ Motor_Otto_MQB SG_ 1714 UH_Monat 5000;
BA_REL_ "GenSigTimeoutTime" BU_SG_REL_ SAK_MQB SG_ 1714 UH_Monat 5000;
BA_REL_ "GenSigTimeoutTime" BU_SG_REL_ Airbag_MQB SG_ 1714 UH_Tag 5000;
BA_REL_ "GenSigTimeoutTime" BU_SG_REL_ BMS_MQB SG_ 1714 UH_Tag 5000;
BA_REL_ "GenSigTimeoutTime" BU_SG_REL_ Getriebe_DQ_Hybrid_MQB SG_ 1714 UH_Tag 5000;
BA_REL_ "GenSigTimeoutTime" BU_SG_REL_ Getriebe_DQ_MQB SG_ 1714 UH_Tag 5000;
BA_REL_ "GenSigTimeoutTime" BU_SG_REL_ LEH_MQB SG_ 1714 UH_Tag 5000;
BA_REL_ "GenSigTimeoutTime" BU_SG_REL_ Motor_Diesel_MQB SG_ 1714 UH_Tag 5000;
BA_REL_ "GenSigTimeoutTime" BU_SG_REL_ Motor_Hybrid_MQB SG_ 1714 UH_Tag 5000;
BA_REL_ "GenSigTimeoutTime" BU_SG_REL_ Motor_Otto_MQB SG_ 1714 UH_Tag 5000;
BA_REL_ "GenSigTimeoutTime" BU_SG_REL_ SAK_MQB SG_ 1714 UH_Tag 5000;
BA_REL_ "GenSigTimeoutTime" BU_SG_REL_ Airbag_MQB SG_ 1714 UH_Stunde 5000;
BA_REL_ "GenSigTimeoutTime" BU_SG_REL_ BMS_MQB SG_ 1714 UH_Stunde 5000;
BA_REL_ "GenSigTimeoutTime" BU_SG_REL_ Getriebe_DQ_Hybrid_MQB SG_ 1714 UH_Stunde 5000;
BA_REL_ "GenSigTimeoutTime" BU_SG_REL_ Getriebe_DQ_MQB SG_ 1714 UH_Stunde 5000;
BA_REL_ "GenSigTimeoutTime" BU_SG_REL_ LEH_MQB SG_ 1714 UH_Stunde 5000;
BA_REL_ "GenSigTimeoutTime" BU_SG_REL_ Motor_Diesel_MQB SG_ 1714 UH_Stunde 5000;
BA_REL_ "GenSigTimeoutTime" BU_SG_REL_ Motor_Hybrid_MQB SG_ 1714 UH_Stunde 5000;
BA_REL_ "GenSigTimeoutTime" BU_SG_REL_ Motor_Otto_MQB SG_ 1714 UH_Stunde 5000;
BA_REL_ "GenSigTimeoutTime" BU_SG_REL_ SAK_MQB SG_ 1714 UH_Stunde 5000;
BA_REL_ "GenSigTimeoutTime" BU_SG_REL_ Airbag_MQB SG_ 1714 UH_Minute 5000;
BA_REL_ "GenSigTimeoutTime" BU_SG_REL_ BMS_MQB SG_ 1714 UH_Minute 5000;
BA_REL_ "GenSigTimeoutTime" BU_SG_REL_ Getriebe_DQ_Hybrid_MQB SG_ 1714 UH_Minute 5000;
BA_REL_ "GenSigTimeoutTime" BU_SG_REL_ Getriebe_DQ_MQB SG_ 1714 UH_Minute 5000;
BA_REL_ "GenSigTimeoutTime" BU_SG_REL_ LEH_MQB SG_ 1714 UH_Minute 5000;
BA_REL_ "GenSigTimeoutTime" BU_SG_REL_ Motor_Diesel_MQB SG_ 1714 UH_Minute 5000;
BA_REL_ "GenSigTimeoutTime" BU_SG_REL_ Motor_Hybrid_MQB SG_ 1714 UH_Minute 5000;
BA_REL_ "GenSigTimeoutTime" BU_SG_REL_ Motor_Otto_MQB SG_ 1714 UH_Minute 5000;
BA_REL_ "GenSigTimeoutTime" BU_SG_REL_ SAK_MQB SG_ 1714 UH_Minute 5000;
BA_REL_ "GenSigTimeoutTime" BU_SG_REL_ Airbag_MQB SG_ 1714 UH_Sekunde 5000;
BA_REL_ "GenSigTimeoutTime" BU_SG_REL_ BMS_MQB SG_ 1714 UH_Sekunde 5000;
BA_REL_ "GenSigTimeoutTime" BU_SG_REL_ Getriebe_DQ_Hybrid_MQB SG_ 1714 UH_Sekunde 5000;
BA_REL_ "GenSigTimeoutTime" BU_SG_REL_ Getriebe_DQ_MQB SG_ 1714 UH_Sekunde 5000;
BA_REL_ "GenSigTimeoutTime" BU_SG_REL_ LEH_MQB SG_ 1714 UH_Sekunde 5000;
BA_REL_ "GenSigTimeoutTime" BU_SG_REL_ Motor_Diesel_MQB SG_ 1714 UH_Sekunde 5000;
BA_REL_ "GenSigTimeoutTime" BU_SG_REL_ Motor_Hybrid_MQB SG_ 1714 UH_Sekunde 5000;
BA_REL_ "GenSigTimeoutTime" BU_SG_REL_ Motor_Otto_MQB SG_ 1714 UH_Sekunde 5000;
BA_REL_ "GenSigTimeoutTime" BU_SG_REL_ SAK_MQB SG_ 1714 UH_Sekunde 5000;
BA_REL_ "GenSigTimeoutTime" BU_SG_REL_ Airbag_MQB SG_ 1714 Kombi_02_alt 5000;
BA_REL_ "GenSigTimeoutTime" BU_SG_REL_ BMS_MQB SG_ 1714 Kombi_02_alt 5000;
BA_REL_ "GenSigTimeoutTime" BU_SG_REL_ LEH_MQB SG_ 1714 Kombi_02_alt 5000;
BA_REL_ "GenSigTimeoutTime" BU_SG_REL_ Airbag_MQB SG_ 1714 Uhrzeit_01_alt 5000;
BA_REL_ "GenSigTimeoutTime" BU_SG_REL_ BMS_MQB SG_ 1714 Uhrzeit_01_alt 5000;
BA_REL_ "GenSigTimeoutTime" BU_SG_REL_ LEH_MQB SG_ 1714 Uhrzeit_01_alt 5000;
BA_REL_ "GenSigTimeoutTime" BU_SG_REL_ Airbag_MQB SG_ 1520 DI_KL_58xd 2000;
BA_REL_ "GenSigTimeoutTime" BU_SG_REL_ Motor_Diesel_MQB SG_ 1603 KBI_Einheit_Streckenanz 5000;
BA_REL_ "GenSigTimeoutTime" BU_SG_REL_ Getriebe_DQ_Hybrid_MQB SG_ 260 EPB_01_CRC 500;
BA_REL_ "GenSigTimeoutTime" BU_SG_REL_ Getriebe_DQ_MQB SG_ 260 EPB_01_CRC 500;
BA_REL_ "GenSigTimeoutTime" BU_SG_REL_ Motor_Diesel_MQB SG_ 260 EPB_01_CRC 500;
BA_REL_ "GenSigTimeoutTime" BU_SG_REL_ Motor_Diesel_MQB SG_ 260 EPB_01_CRC 500;
BA_REL_ "GenSigTimeoutTime" BU_SG_REL_ Motor_Hybrid_MQB SG_ 260 EPB_01_CRC 500;
BA_REL_ "GenSigTimeoutTime" BU_SG_REL_ Motor_Hybrid_MQB SG_ 260 EPB_01_CRC 500;
BA_REL_ "GenSigTimeoutTime" BU_SG_REL_ Motor_Otto_MQB SG_ 260 EPB_01_CRC 500;
BA_REL_ "GenSigTimeoutTime" BU_SG_REL_ Motor_Otto_MQB SG_ 260 EPB_01_CRC 500;
BA_REL_ "GenSigTimeoutTime" BU_SG_REL_ Getriebe_DQ_Hybrid_MQB SG_ 260 EPB_01_BZ 500;
BA_REL_ "GenSigTimeoutTime" BU_SG_REL_ Getriebe_DQ_MQB SG_ 260 EPB_01_BZ 500;
BA_REL_ "GenSigTimeoutTime" BU_SG_REL_ Motor_Diesel_MQB SG_ 260 EPB_01_BZ 500;
BA_REL_ "GenSigTimeoutTime" BU_SG_REL_ Motor_Diesel_MQB SG_ 260 EPB_01_BZ 500;
BA_REL_ "GenSigTimeoutTime" BU_SG_REL_ Motor_Hybrid_MQB SG_ 260 EPB_01_BZ 500;
BA_REL_ "GenSigTimeoutTime" BU_SG_REL_ Motor_Hybrid_MQB SG_ 260 EPB_01_BZ 500;
BA_REL_ "GenSigTimeoutTime" BU_SG_REL_ Motor_Otto_MQB SG_ 260 EPB_01_BZ 500;
BA_REL_ "GenSigTimeoutTime" BU_SG_REL_ Motor_Otto_MQB SG_ 260 EPB_01_BZ 500;
BA_REL_ "GenSigTimeoutTime" BU_SG_REL_ Motor_Diesel_MQB SG_ 260 EPB_Freig_Verzoeg_Anf 500;
BA_REL_ "GenSigTimeoutTime" BU_SG_REL_ Motor_Hybrid_MQB SG_ 260 EPB_Freig_Verzoeg_Anf 500;
BA_REL_ "GenSigTimeoutTime" BU_SG_REL_ Motor_Otto_MQB SG_ 260 EPB_Freig_Verzoeg_Anf 500;
BA_REL_ "GenSigTimeoutTime" BU_SG_REL_ Getriebe_DQ_Hybrid_MQB SG_ 260 EPB_DAA_Randbed_erf 500;
BA_REL_ "GenSigTimeoutTime" BU_SG_REL_ Getriebe_DQ_MQB SG_ 260 EPB_DAA_Randbed_erf 500;
BA_REL_ "GenSigTimeoutTime" BU_SG_REL_ Motor_Diesel_MQB SG_ 260 EPB_Schalterposition 500;
BA_REL_ "GenSigTimeoutTime" BU_SG_REL_ Motor_Diesel_MQB SG_ 260 EPB_Schalterposition 500;
BA_REL_ "GenSigTimeoutTime" BU_SG_REL_ Motor_Hybrid_MQB SG_ 260 EPB_Schalterposition 500;
BA_REL_ "GenSigTimeoutTime" BU_SG_REL_ Motor_Hybrid_MQB SG_ 260 EPB_Schalterposition 500;
BA_REL_ "GenSigTimeoutTime" BU_SG_REL_ Motor_Otto_MQB SG_ 260 EPB_Schalterposition 500;
BA_REL_ "GenSigTimeoutTime" BU_SG_REL_ Motor_Otto_MQB SG_ 260 EPB_Schalterposition 500;
BA_REL_ "GenSigTimeoutTime" BU_SG_REL_ Motor_Diesel_MQB SG_ 260 EPB_QBit_Schalterpos 500;
BA_REL_ "GenSigTimeoutTime" BU_SG_REL_ Motor_Hybrid_MQB SG_ 260 EPB_QBit_Schalterpos 500;
BA_REL_ "GenSigTimeoutTime" BU_SG_REL_ Motor_Otto_MQB SG_ 260 EPB_QBit_Schalterpos 500;
BA_REL_ "GenSigTimeoutTime" BU_SG_REL_ Getriebe_DQ_Hybrid_MQB SG_ 260 EPB_Spannkraft 500;
BA_REL_ "GenSigTimeoutTime" BU_SG_REL_ Getriebe_DQ_MQB SG_ 260 EPB_Spannkraft 500;
BA_REL_ "GenSigTimeoutTime" BU_SG_REL_ Getriebe_DQ_Hybrid_MQB SG_ 260 EPB_Status 500;
BA_REL_ "GenSigTimeoutTime" BU_SG_REL_ Getriebe_DQ_MQB SG_ 260 EPB_Status 500;
BA_REL_ "GenSigTimeoutTime" BU_SG_REL_ Motor_Diesel_MQB SG_ 260 EPB_Status 500;
BA_REL_ "GenSigTimeoutTime" BU_SG_REL_ Motor_Diesel_MQB SG_ 260 EPB_Status 500;
BA_REL_ "GenSigTimeoutTime" BU_SG_REL_ Motor_Hybrid_MQB SG_ 260 EPB_Status 500;
BA_REL_ "GenSigTimeoutTime" BU_SG_REL_ Motor_Hybrid_MQB SG_ 260 EPB_Status 500;
BA_REL_ "GenSigTimeoutTime" BU_SG_REL_ Motor_Otto_MQB SG_ 260 EPB_Status 500;
BA_REL_ "GenSigTimeoutTime" BU_SG_REL_ Motor_Otto_MQB SG_ 260 EPB_Status 500;
BA_REL_ "GenSigTimeoutTime" BU_SG_REL_ Airbag_MQB SG_ 257 ESP_02_CRC 500;
BA_REL_ "GenSigTimeoutTime" BU_SG_REL_ Getriebe_DQ_Hybrid_MQB SG_ 257 ESP_02_CRC 500;
BA_REL_ "GenSigTimeoutTime" BU_SG_REL_ Getriebe_DQ_MQB SG_ 257 ESP_02_CRC 500;
BA_REL_ "GenSigTimeoutTime" BU_SG_REL_ Motor_Diesel_MQB SG_ 257 ESP_02_CRC 500;
BA_REL_ "GenSigTimeoutTime" BU_SG_REL_ Motor_Diesel_MQB SG_ 257 ESP_02_CRC 500;
BA_REL_ "GenSigTimeoutTime" BU_SG_REL_ Motor_Hybrid_MQB SG_ 257 ESP_02_CRC 500;
BA_REL_ "GenSigTimeoutTime" BU_SG_REL_ Motor_Hybrid_MQB SG_ 257 ESP_02_CRC 500;
BA_REL_ "GenSigTimeoutTime" BU_SG_REL_ Motor_Otto_MQB SG_ 257 ESP_02_CRC 500;
BA_REL_ "GenSigTimeoutTime" BU_SG_REL_ Motor_Otto_MQB SG_ 257 ESP_02_CRC 500;
BA_REL_ "GenSigTimeoutTime" BU_SG_REL_ Airbag_MQB SG_ 257 ESP_02_BZ 500;
BA_REL_ "GenSigTimeoutTime" BU_SG_REL_ Getriebe_DQ_Hybrid_MQB SG_ 257 ESP_02_BZ 500;
BA_REL_ "GenSigTimeoutTime" BU_SG_REL_ Getriebe_DQ_MQB SG_ 257 ESP_02_BZ 500;
BA_REL_ "GenSigTimeoutTime" BU_SG_REL_ Motor_Diesel_MQB SG_ 257 ESP_02_BZ 500;
BA_REL_ "GenSigTimeoutTime" BU_SG_REL_ Motor_Diesel_MQB SG_ 257 ESP_02_BZ 500;
BA_REL_ "GenSigTimeoutTime" BU_SG_REL_ Motor_Hybrid_MQB SG_ 257 ESP_02_BZ 500;
BA_REL_ "GenSigTimeoutTime" BU_SG_REL_ Motor_Hybrid_MQB SG_ 257 ESP_02_BZ 500;
BA_REL_ "GenSigTimeoutTime" BU_SG_REL_ Motor_Otto_MQB SG_ 257 ESP_02_BZ 500;
BA_REL_ "GenSigTimeoutTime" BU_SG_REL_ Motor_Otto_MQB SG_ 257 ESP_02_BZ 500;
BA_REL_ "GenSigTimeoutTime" BU_SG_REL_ Airbag_MQB SG_ 257 ESP_QBit_Gierrate 500;
BA_REL_ "GenSigTimeoutTime" BU_SG_REL_ Getriebe_DQ_Hybrid_MQB SG_ 257 ESP_QBit_Gierrate 500;
BA_REL_ "GenSigTimeoutTime" BU_SG_REL_ Getriebe_DQ_MQB SG_ 257 ESP_QBit_Gierrate 500;
BA_REL_ "GenSigTimeoutTime" BU_SG_REL_ Airbag_MQB SG_ 257 ESP_QBit_Laengsbeschl 500;
BA_REL_ "GenSigTimeoutTime" BU_SG_REL_ Getriebe_DQ_Hybrid_MQB SG_ 257 ESP_QBit_Laengsbeschl 500;
BA_REL_ "GenSigTimeoutTime" BU_SG_REL_ Getriebe_DQ_MQB SG_ 257 ESP_QBit_Laengsbeschl 500;
BA_REL_ "GenSigTimeoutTime" BU_SG_REL_ Motor_Diesel_MQB SG_ 257 ESP_QBit_Laengsbeschl 500;
BA_REL_ "GenSigTimeoutTime" BU_SG_REL_ Motor_Diesel_MQB SG_ 257 ESP_QBit_Laengsbeschl 500;
BA_REL_ "GenSigTimeoutTime" BU_SG_REL_ Motor_Hybrid_MQB SG_ 257 ESP_QBit_Laengsbeschl 500;
BA_REL_ "GenSigTimeoutTime" BU_SG_REL_ Motor_Hybrid_MQB SG_ 257 ESP_QBit_Laengsbeschl 500;
BA_REL_ "GenSigTimeoutTime" BU_SG_REL_ Motor_Otto_MQB SG_ 257 ESP_QBit_Laengsbeschl 500;
BA_REL_ "GenSigTimeoutTime" BU_SG_REL_ Motor_Otto_MQB SG_ 257 ESP_QBit_Laengsbeschl 500;
BA_REL_ "GenSigTimeoutTime" BU_SG_REL_ Airbag_MQB SG_ 257 ESP_QBit_Querb 500;
BA_REL_ "GenSigTimeoutTime" BU_SG_REL_ Getriebe_DQ_Hybrid_MQB SG_ 257 ESP_QBit_Querb 500;
BA_REL_ "GenSigTimeoutTime" BU_SG_REL_ Getriebe_DQ_MQB SG_ 257 ESP_QBit_Querb 500;
BA_REL_ "GenSigTimeoutTime" BU_SG_REL_ Motor_Diesel_MQB SG_ 257 ESP_QBit_Querb 500;
BA_REL_ "GenSigTimeoutTime" BU_SG_REL_ Motor_Diesel_MQB SG_ 257 ESP_QBit_Querb 500;
BA_REL_ "GenSigTimeoutTime" BU_SG_REL_ Motor_Hybrid_MQB SG_ 257 ESP_QBit_Querb 500;
BA_REL_ "GenSigTimeoutTime" BU_SG_REL_ Motor_Hybrid_MQB SG_ 257 ESP_QBit_Querb 500;
BA_REL_ "GenSigTimeoutTime" BU_SG_REL_ Motor_Otto_MQB SG_ 257 ESP_QBit_Querb 500;
BA_REL_ "GenSigTimeoutTime" BU_SG_REL_ Motor_Otto_MQB SG_ 257 ESP_QBit_Querb 500;
BA_REL_ "GenSigTimeoutTime" BU_SG_REL_ Airbag_MQB SG_ 257 ESP_Querbeschleunigung 500;
BA_REL_ "GenSigTimeoutTime" BU_SG_REL_ Getriebe_DQ_Hybrid_MQB SG_ 257 ESP_Querbeschleunigung 500;
BA_REL_ "GenSigTimeoutTime" BU_SG_REL_ Getriebe_DQ_MQB SG_ 257 ESP_Querbeschleunigung 500;
BA_REL_ "GenSigTimeoutTime" BU_SG_REL_ Motor_Diesel_MQB SG_ 257 ESP_Querbeschleunigung 500;
BA_REL_ "GenSigTimeoutTime" BU_SG_REL_ Motor_Diesel_MQB SG_ 257 ESP_Querbeschleunigung 500;
BA_REL_ "GenSigTimeoutTime" BU_SG_REL_ Motor_Hybrid_MQB SG_ 257 ESP_Querbeschleunigung 500;
BA_REL_ "GenSigTimeoutTime" BU_SG_REL_ Motor_Hybrid_MQB SG_ 257 ESP_Querbeschleunigung 500;
BA_REL_ "GenSigTimeoutTime" BU_SG_REL_ Motor_Otto_MQB SG_ 257 ESP_Querbeschleunigung 500;
BA_REL_ "GenSigTimeoutTime" BU_SG_REL_ Motor_Otto_MQB SG_ 257 ESP_Querbeschleunigung 500;
BA_REL_ "GenSigTimeoutTime" BU_SG_REL_ Airbag_MQB SG_ 257 ESP_Laengsbeschl 500;
BA_REL_ "GenSigTimeoutTime" BU_SG_REL_ Getriebe_DQ_Hybrid_MQB SG_ 257 ESP_Laengsbeschl 500;
BA_REL_ "GenSigTimeoutTime" BU_SG_REL_ Getriebe_DQ_MQB SG_ 257 ESP_Laengsbeschl 500;
BA_REL_ "GenSigTimeoutTime" BU_SG_REL_ Motor_Diesel_MQB SG_ 257 ESP_Laengsbeschl 500;
BA_REL_ "GenSigTimeoutTime" BU_SG_REL_ Motor_Diesel_MQB SG_ 257 ESP_Laengsbeschl 500;
BA_REL_ "GenSigTimeoutTime" BU_SG_REL_ Motor_Hybrid_MQB SG_ 257 ESP_Laengsbeschl 500;
BA_REL_ "GenSigTimeoutTime" BU_SG_REL_ Motor_Hybrid_MQB SG_ 257 ESP_Laengsbeschl 500;
BA_REL_ "GenSigTimeoutTime" BU_SG_REL_ Motor_Otto_MQB SG_ 257 ESP_Laengsbeschl 500;
BA_REL_ "GenSigTimeoutTime" BU_SG_REL_ Motor_Otto_MQB SG_ 257 ESP_Laengsbeschl 500;
BA_REL_ "GenSigTimeoutTime" BU_SG_REL_ Airbag_MQB SG_ 257 ESP_Gierrate 500;
BA_REL_ "GenSigTimeoutTime" BU_SG_REL_ Getriebe_DQ_Hybrid_MQB SG_ 257 ESP_Gierrate 500;
BA_REL_ "GenSigTimeoutTime" BU_SG_REL_ Getriebe_DQ_MQB SG_ 257 ESP_Gierrate 500;
BA_REL_ "GenSigTimeoutTime" BU_SG_REL_ Airbag_MQB SG_ 257 ESP_VZ_Gierrate 500;
BA_REL_ "GenSigTimeoutTime" BU_SG_REL_ Getriebe_DQ_Hybrid_MQB SG_ 257 ESP_VZ_Gierrate 500;
BA_REL_ "GenSigTimeoutTime" BU_SG_REL_ Getriebe_DQ_MQB SG_ 257 ESP_VZ_Gierrate 500;
BA_REL_ "GenSigTimeoutTime" BU_SG_REL_ Airbag_MQB SG_ 257 ESP_Notbremsanzeige 500;
BA_REL_ "GenSigTimeoutTime" BU_SG_REL_ Getriebe_DQ_Hybrid_MQB SG_ 257 ESP_Status_ESP_PLA 500;
BA_REL_ "GenSigTimeoutTime" BU_SG_REL_ Getriebe_DQ_MQB SG_ 257 ESP_Status_ESP_PLA 500;
VAL_ 290 ACC_limitierte_Anfahrdyn 0 "keine_Limitierung" 1 "Limitierung_Anfahrdynamik_angefordert" ;
VAL_ 290 ACC_StartStopp_Info 0 "Motorlauf_langfristig_nicht_notwendig_Stoppfreigabe" 1 "Motoranlauf_nicht_zwingend_notwendig_Stoppverbot_keine_Startanforderung" 2 "Motoranlauf_zwingend_notwendig_Startanforderung" 3 "Systemfehler" ;
VAL_ 290 ACC_Sollbeschleunigung_02 2046 "Neutralwert" 2047 "Fehler" ;
VAL_ 290 ACC_Anfahren 0 "keine_Anforderung_Anfahren" 1 "Anforderung_Anfahren" ;
VAL_ 290 ACC_Anhalten 0 "kein_Anhalten_gewuenscht" 1 "Anhalten_gewuenscht" ;
VAL_ 290 ACC_Typ 0 "Basis_ACC" 1 "ACC_mit_FollowToStop" 2 "ACC_mit_StopAndGo" ;
VAL_ 290 ACC_Status_ACC 0 "ACC_OFF_Hauptschalter_aus" 1 "ACC_INIT" 2 "ACC_STANDBY" 3 "ACC_AKTIV_regelt" 4 "ACC_OVERRIDE" 5 "nicht_definiert" 6 "reversibler_Fehler_im_ACC_System" 7 "irreversibler_Fehler_im_ACC_System" ;
VAL_ 290 ACC_Minimale_Bremsung 0 "Anforderung Minimale Bremsung nicht aktiv" 1 "Anforderung Minimale Bremsung aktiv" ;
VAL_ 279 AWV1_Anf_Prefill 0 "Prefill_nicht_aktivieren" 1 "Prefill_aktivieren" ;
VAL_ 279 ANB_CM_Info 0 "Standard" 1 "Erweitert" ;
VAL_ 279 AWV2_Freigabe 0 "keine_Freigabe" 1 "Freigabe" ;
VAL_ 279 AWV1_HBA_Param 0 "Defaultparametersatz" 1 "Parametersatz_mit_leicht_erhoehter_Empfindlichkeit" 2 "Parametersatz_mit_erhoehter_Empfindlichkeit" 3 "Parametersatz_mit_hoechster_Empfindlichkeit" ;
VAL_ 279 AWV2_Priowarnung 0 "Anzeige_Verlassen_der_Fahrspur_wird_nicht_unterdrueckt" 1 "Anzeige_Verlassen_der_Fahrspur_wird_unterdrueckt" ;
VAL_ 279 ANB_CM_Anforderung 0 "keine_Anforderung" 1 "Anforderung_aktiv" ;
VAL_ 279 ANB_Info_Teilbremsung 0 "Auspraegung_Standard" 1 "Auspraegung_Erweitert" ;
VAL_ 279 ANB_Notfallblinken 0 "kein_ANB_Notfallblinken" 1 "Notfallblinken_ANB_angefordert" ;
VAL_ 279 ANB_Teilbremsung_Freigabe 0 "Teilbremsung_nicht_freigegeben" 1 "Teilbremsung_freigegeben" ;
VAL_ 279 ANB_Zielbremsung_Freigabe 0 "Zielbremsung_nicht_freigegeben" 1 "Zielbremsung_freigegeben" ;
VAL_ 279 AWV_Vorstufe 0 "keine_Notbremsung_erwartet" 1 "Notbremsung_in_Kuerze" ;
VAL_ 279 AWV_Halten 0 "keine_Anforderung" 1 "Anforderung_das_Fzg_im_Stillstand_zu_halten" ;
VAL_ 64 AB_RGS_Anst 4 "aktiv_Niveau_1" 5 "aktiv_Niveau_2" 6 "aktiv_Niveau_3" 7 "aktiv_Niveau_4" 8 "deaktiviert" ;
VAL_ 64 AB_Front_Crash 0 "kein_Front_Crash" 1 "Front_Crash" ;
VAL_ 64 AB_Heck_Crash 0 "kein_Heck_Crash" 1 "Heck_Crash" ;
VAL_ 64 AB_SF_Crash 0 "kein_Seiten_Crash_Fahrer" 1 "Seiten_Crash_Fahrer" ;
VAL_ 64 AB_SB_Crash 0 "kein_Seiten_Crash_Beifahrer" 1 "Seiten_Crash_Beifahrer" ;
VAL_ 64 AB_Rollover_Crash 0 "kein_Rollover" 1 "Rollover" ;
VAL_ 64 AB_Crash_Int 0 "kein_Crash" 1 "Crash_Intensitaet_1" 2 "Crash_Intensitaet_2_(nur_Stellgliedtest_B8)" 3 "Crash_Intensitaet_2_(nur_D4_C7_Colorado_NF_PAG__Crash_im_B8)" 4 "Crash_Intensitaet_3_(alt_VW/AUDI__Stellgiedtest_B8)" 5 "Crash_Intensitaet_3_(alt_PAG)" 7 "Crash_Intensitaet_3" ;
VAL_ 64 AB_Lampe 0 "Aus" 1 "Ein" ;
VAL_ 64 AB_Deaktiviert 0 "aktiv" 1 "deaktiviert" ;
VAL_ 64 AB_VB_deaktiviert 0 "Beifahrerairbag_aktiv" 1 "Beifahrerairbag_deaktiviert" ;
VAL_ 64 AB_Systemfehler 0 "kein_Fehler" 1 "Airbag_Systemfehler" ;
VAL_ 64 AB_Diagnose 0 "nicht_in_Diagnose" 1 "in_Diagnose" ;
VAL_ 64 AB_Stellgliedtest 0 "nicht_im_Stellgliedtest" 1 "Airbag_im_Stellgliedtest" ;
VAL_ 64 AB_Erh_Auf_VB 0 "keine_Anzeige" 1 "Beifahrerairbag_deaktiviert" 2 "Beifahrerairbag_aktiviert" 3 "nicht_definiert" ;
VAL_ 64 AB_Gurtwarn_VF 0 "keine_Warnung" 1 "Gurtwarnung_ausloesen" ;
VAL_ 64 AB_Gurtwarn_VB 0 "keine_Warnung" 1 "Gurtwarnung_ausloesen" ;
VAL_ 64 AB_Anzeige_Fussg 0 "keine_FSG_Aktion_ausgeloest" 1 "Motorhaube_offen" 2 "Systemfehler" ;
VAL_ 64 AB_Texte_AKS 0 "keine_AKS_Ausloesung" 1 "AKS_ausgeloest" 2 "AKS_Systemfehler" ;
VAL_ 64 AB_PAO_Leuchte_Anf 0 "Leuchte_ausschalten" 1 "Leuchte_einschalten" ;
VAL_ 64 AB_MKB_gueltig 0 "Multikollisionsbremsung_nicht_freigeschaltet" 1 "Multikollisionsbremsung_freigeschaltet" ;
VAL_ 64 AB_MKB_Anforderung 0 "Multikollisionsbremsung_nicht_angefordert" 1 "Multikollisionsbremsung_angefordert" ;
VAL_ 64 AB_Versorgungsspannung 0 "plausibel" 1 "unplausibel" ;
VAL_ 1312 AB_Belegung_VB 0 "nicht_verfuegbar" 1 "Fehler" 2 "nicht_belegt" 3 "belegt" ;
VAL_ 1312 AB_Gurtschloss_FA 0 "nicht_verbaut" 1 "nicht_verfügbar (Fehler oder Init)" 2 "nicht_gesteckt" 3 "gesteckt" ;
VAL_ 1312 AB_Gurtschloss_BF 0 "nicht_verbaut" 1 "nicht_verfügbar (Fehler oder Init)" 2 "nicht_gesteckt" 3 "gesteckt" ;
VAL_ 1312 AB_Gurtschloss_Reihe2_FA 0 "nicht_verbaut" 1 "nicht_verfügbar (Fehler oder Init)" 2 "nicht_gesteckt" 3 "gesteckt" ;
VAL_ 1312 AB_Gurtschloss_Reihe2_MI 0 "nicht_verbaut" 1 "nicht_verfügbar (Fehler oder Init)" 2 "nicht_gesteckt" 3 "gesteckt" ;
VAL_ 1312 AB_Gurtschloss_Reihe2_BF 0 "nicht_verbaut" 1 "nicht_verfügbar (Fehler oder Init)" 2 "nicht_gesteckt" 3 "gesteckt" ;
VAL_ 1312 AB_Gurtschloss_Reihe3_FA 0 "nicht_verbaut" 1 "nicht_verfügbar (Fehler oder Init)" 2 "nicht_gesteckt" 3 "gesteckt" ;
VAL_ 1312 AB_Gurtschloss_Reihe3_MI 0 "nicht_verbaut" 1 "nicht_verfügbar (Fehler oder Init)" 2 "nicht_gesteckt" 3 "gesteckt" ;
VAL_ 1312 AB_Gurtschloss_Reihe3_BF 0 "nicht_verbaut" 1 "nicht_verfügbar (Fehler oder Init)" 2 "nicht_gesteckt" 3 "gesteckt" ;
VAL_ 1312 AB_Sitzpos_Sens_FA 0 "nicht verfügbar" 1 "Fehler" 2 "Sitz nicht vorne" 3 "Sitz vorne" ;
VAL_ 1312 AB_Sitzpos_Sens_BF 0 "nicht verfügbar" 1 "Fehler" 2 "Sitz nicht vorne" 3 "Sitz vorne" ;
VAL_ 65 AB_MKB_Safing 0 "Multikollisionsbremsung_nicht_bestaetigt" 1 "Multikollisionsbremsung_bestaetigt" ;
VAL_ 1633 AAG_Bremsl_durch_ECD 0 "Bremslicht_ist_aus" 1 "Bremslicht_durch_ECD_aktiv" ;
VAL_ 1633 AAG_Anhaenger_abgesteckt 1 "Anhaenger_wurde_bei_KL15_aus_abgesteckt" ;
VAL_ 1633 AAG_NSL_aktiv 1 "Anhaenger_Nebelschusslicht_aktiv" ;
VAL_ 1633 AAG_Anhaenger_erkannt 0 "kein_Anhaenger_erkannt" 1 "AAG_Anhaenger_erkannt" ;
VAL_ 1633 AAG_Blinker_H_aktiv 1 "Anhaenger_Blinker_aktiv" ;
VAL_ 1633 AAG_Blinker_HL_def 1 "Anhaenger_Blinker_links_defekt" ;
VAL_ 1633 AAG_Blinker_HR_def 1 "Anhaenger_Blinker_rechts_defekt" ;
VAL_ 1633 AAG_Bremslicht_H_def 1 "Anhaenger_Bremslicht_defekt" ;
VAL_ 1633 AAG_Schlusslicht_HL_def 1 "Anhaenger_Schlusslicht_links_defekt" ;
VAL_ 1633 AAG_Schlusslicht_HR_def 1 "Anhaenger_Schlusslicht_rechts_defekt" ;
VAL_ 1633 AAG_AVS_Fehler_02 0 "kein_Fehler" 1 "Fehler" ;
VAL_ 1633 AAG_AVS_Stati 0 "endlage eingefahren erreicht" 1 "endlage ausgefahren erreicht" 2 "ausfahren automatik " 3 "einfahren automatik" 4 "ausfahren manuell " 5 "einfahren manuell" 6 "zwischenposition" 7 "nicht initialisiert" ;
VAL_ 1626 BCM_Bremsbelag_Sensor 0 "OK" 1 "Bremsbelag_unter_min" ;
VAL_ 1626 BCM_Bremsfluessigkeit_Sensor 0 "OK" 1 "Bremsfluessigkeit_unter_min" ;
VAL_ 1626 BCM1_Licht_Warn 0 "OK" 1 "Lichtwarnung aktiv" ;
VAL_ 1626 BCM_Waschwasser_Sensor 0 "OK" 1 "Waschwasser_unter_min" ;
VAL_ 1626 BCM_Kuehlmittel_Sensor 0 "OK" 1 "Kuehlmittel_unter_min" ;
VAL_ 1626 BCM1_Kl_15_HW_erkannt 1 "Klemme 15 erkannt" ;
VAL_ 1626 BCM_Eis_Offroad_Taste 0 "nicht_betaetigt" 1 "betaetigt" ;
VAL_ 1626 ZZH_Endlage_oben 0 "ZZH_nicht_in_oberer_Endlage" 1 "ZZH in Endlage oben" ;
VAL_ 1626 ZZH_Endlage_unten 0 "ZZH_nicht_in_unterer_Endlage" 1 "ZZH in Endlage unten" ;
VAL_ 1626 ZZH_Endlage_unplausibel 0 "Endlage_ZZH_plausibel" 1 "unplausible Endlage der ZZH erkannt" ;
VAL_ 1626 BCM2_EZS_gedrueckt 1 "EZS gedrueckt" ;
VAL_ 1626 BCM2_SST_gedrueckt 1 "SST gedrueckt" ;
VAL_ 1626 BCM_Hybrid_StartStopp_Taste 0 "nicht_betaetigt" 1 "betaetigt" ;
VAL_ 1626 BCM1_Warnblink_Taster 0 "nicht_betaetigt" 1 "betaetigt" ;
VAL_ 1626 BCM1_Valet_Parking_Taster 0 "nicht_betaetigt" 1 "betaetigt" ;
VAL_ 1626 BCM_Remotestart_Betrieb 0 "kein_RS_Betrieb" 1 "RS_Betrieb" ;
VAL_ 1626 BCM1_HSK_Taster 0 "nicht_betaetigt" 1 "betaetigt" ;
VAL_ 1626 BCM1_Heckrollo_Taster 0 "nicht_betaetigt" 1 "betaetigt" ;
VAL_ 1626 BCM1_Rueckfahrlicht_Schalter 0 "nicht_betaetigt" 1 "betaetigt" ;
VAL_ 1626 BCM1_MH_Schalter 0 "MH_geschlossen" 1 "MH_offen" ;
VAL_ 1626 BCM1_MH_WIV_Schalter 0 "MH_geschlossen" 1 "MH_offen" ;
VAL_ 1626 BCM_Eco_Charisma_Taste 0 "nicht_betaetigt" 1 "betaetigt" ;
VAL_ 1626 BCM_Thermomanagement 0 "keine_Freigabe_TMM__max_Heizbedarf" 1 "kleine_Freigabe_TMM" 2 "mittlere_Freigabe_TMM" 3 "volle_Freigabe_TMM__kein_Heizbedarf" ;
VAL_ 1626 BCM_Thermomanagement_Fehler 0 "gueltiger_Bereich" 1 "ungueltiger_Bereich" ;
VAL_ 1626 BCM_Thermomanagement_gueltig 0 "ungueltig" 1 "gueltig" ;
VAL_ 1626 BCM1_Lichtwarn_Texte 0 "keine_Warnung" 1 "Standlichtwarnung" 2 "Parklichtwarnung" 3 "Nebelschlusslichtwarnung" ;
VAL_ 869 BEM_P_Generator 255 "Fehler" ;
VAL_ 869 BEM_n_LLA 0 "keine_Erhoehung" 1 "Stufe_1" 2 "Stufe_2" 3 "Stufe_3" ;
VAL_ 869 BEM_01_Abschaltstufen 0 "Stufe_0_keine_Einschraenkung" 1 "Stufe_1" 2 "Stufe_2" 3 "Stufe_3" 4 "Transportmodus" 7 "Ruhestrommessmodus" ;
VAL_ 869 BEM_Anf_KL 0 "keine Anforderung" 1 "Anforderung Kühlerlüfter Ansteuerung" ;
VAL_ 869 BEM_StartStopp_Info 0 "Motorlauf_nicht_notwendig_(Stoppfreigabe)" 1 "Motoranlauf_nicht_zwingend_notwendig_(Stoppverbot,keine_Startanforderung)" 2 "Motoranlauf_zwingend_notwendig_(Startanforderung)" 3 "Systemfehler" ;
VAL_ 869 BEM_EMLIN_ungueltig 0 "Signale_gueltig" 1 "Signale_ungueltig" ;
VAL_ 869 BEM_Batt_Ab 0 "verbunden" 1 "nicht_verbunden" ;
VAL_ 869 BEM_Segel_Info 0 "keine_Anforderung" 1 "Mindestdrehzahl_1" 2 "Mindestdrehzahl_2" 3 "Segelveto" ;
VAL_ 869 BEM_HYB_DC_uMinLV 254 "Init" 255 "Fehler" ;
VAL_ 1628 BMS_HYB_ASV_hinten_Status 0 "Ventil_offen" 1 "Ventil_geschlossen" ;
VAL_ 1628 BMS_HYB_ASV_vorne_Status 0 "Ventil_offen" 1 "Ventil_geschlossen" ;
VAL_ 1628 BMS_HYB_KD_Fehler 0 "kein_KD_Fehler" 1 "KD_Fehler" ;
VAL_ 1628 BMS_HYB_BattFanSpd 14 "Init" 15 "Fehler" ;
VAL_ 1628 BMS_HYB_VentilationReq 1 "Ventilation_Request" ;
VAL_ 1628 BMS_HYB_Spuelbetrieb_Status 0 "Umluftbetrieb" 1 "Spuelbetrieb" ;
VAL_ 1628 BMS_HYB_Kuehlung_Anf 0 "keine_Kuehlanforderung" 1 "aktive_Kuehlung_Stufe_1" 2 "aktive_Kuehlung_Stufe_2" 3 "Kuehlung_max" ;
VAL_ 1628 BMS_HYB_Temp_vor_Verd 254 "Init" 255 "Fehler" ;
VAL_ 1628 BMS_HYB_Temp_nach_Verd 254 "Init" 255 "Fehler" ;
VAL_ 1628 BMS_Temperatur 254 "Init" 255 "Fehler" ;
VAL_ 1628 BMS_Temperatur_Ansaugluft 254 "Init" 255 "Fehler" ;
VAL_ 1628 BMS_IstSpannung_HV 255 "Fehler" ;
VAL_ 901 CHA_Ziel_FahrPr_ALR 0 "nicht_belegt" 1 "Programm_1" 2 "Programm_2" 3 "Programm_3" 4 "Programm_4" 5 "Programm_5" 6 "Programm_6" 7 "Programm_7" 8 "Programm_8" 9 "Programm_9" 10 "Programm_10" 11 "Programm_11" 12 "Programm_12" 13 "Programm_13" 14 "Programm_14" 15 "Programm_15" ;
VAL_ 901 CHA_Ziel_FahrPr_ESP 0 "nicht_belegt" 1 "Programm_1" 2 "Programm_2" 3 "Programm_3" 4 "Programm_4" 5 "Programm_5" 6 "Programm_6" 7 "Programm_7" 8 "Programm_8" 9 "Programm_9" 10 "Programm_10" 11 "Programm_11" 12 "Programm_12" 13 "Programm_13" 14 "Programm_14" 15 "Programm_15" ;
VAL_ 901 CHA_Ziel_FahrPr_FL 0 "nicht_belegt" 1 "Programm_1" 2 "Programm_2" 3 "Programm_3" 4 "Programm_4" 5 "Programm_5" 6 "Programm_6" 7 "Programm_7" 8 "Programm_8" 9 "Programm_9" 10 "Programm_10" 11 "Programm_11" 12 "Programm_12" 13 "Programm_13" 14 "Programm_14" 15 "Programm_15" ;
VAL_ 901 CHA_Fahrer_Umschaltung 0 "keine_oder_automatische_Umschaltung" 1 "manuelle_Umschaltung" ;
VAL_ 901 CHA_Ziel_FahrPr_MO 0 "nicht_belegt" 1 "Programm_1" 2 "Programm_2" 3 "Programm_3" 4 "Programm_4" 5 "Programm_5" 6 "Programm_6" 7 "Programm_7" 8 "Programm_8" 9 "Programm_9" 10 "Programm_10" 11 "Programm_11" 12 "Programm_12" 13 "Programm_13" 14 "Programm_14" 15 "Programm_15" ;
VAL_ 901 CHA_Ziel_FahrPr_GE 0 "nicht_belegt" 1 "Programm_1" 2 "Programm_2" 3 "Programm_3" 4 "Programm_4" 5 "Programm_5" 6 "Programm_6" 7 "Programm_7" 8 "Programm_8" 9 "Programm_9" 10 "Programm_10" 11 "Programm_11" 12 "Programm_12" 13 "Programm_13" 14 "Programm_14" 15 "Programm_15" ;
VAL_ 901 CHA_Ziel_FahrPr_ST 0 "nicht_belegt" 1 "Programm_1" 2 "Programm_2" 3 "Programm_3" 4 "Programm_4" 5 "Programm_5" 6 "Programm_6" 7 "Programm_7" 8 "Programm_8" 9 "Programm_9" 10 "Programm_10" 11 "Programm_11" 12 "Programm_12" 13 "Programm_13" 14 "Programm_14" 15 "Programm_15" ;
VAL_ 901 CHA_Ziel_FahrPr_SCU 0 "nicht_belegt" 1 "Programm_1" 2 "Programm_2" 3 "Programm_3" 4 "Programm_4" 5 "Programm_5" 6 "Programm_6" 7 "Programm_7" 8 "Programm_8" 9 "Programm_9" 10 "Programm_10" 11 "Programm_11" 12 "Programm_12" 13 "Programm_13" 14 "Programm_14" 15 "Programm_15" ;
VAL_ 901 CHA_Ziel_FahrPr_DR 0 "nicht_belegt" 1 "Programm_1" 2 "Programm_2" 3 "Programm_3" 4 "Programm_4" 5 "Programm_5" 6 "Programm_6" 7 "Programm_7" 8 "Programm_8" 9 "Programm_9" 10 "Programm_10" 11 "Programm_11" 12 "Programm_12" 13 "Programm_13" 14 "Programm_14" 15 "Programm_15" ;
VAL_ 901 CHA_Ziel_FahrPr_QS 0 "nicht_belegt" 1 "Programm_1" 2 "Programm_2" 3 "Programm_3" 4 "Programm_4" 5 "Programm_5" 6 "Programm_6" 7 "Programm_7" 8 "Programm_8" 9 "Programm_9" 10 "Programm_10" 11 "Programm_11" 12 "Programm_12" 13 "Programm_13" 14 "Programm_14" 15 "Programm_15" ;
VAL_ 901 CHA_Ziel_FahrPr_AFS 0 "nicht_belegt" 1 "Programm_1" 2 "Programm_2" 3 "Programm_3" 4 "Programm_4" 5 "Programm_5" 6 "Programm_6" 7 "Programm_7" 8 "Programm_8" 9 "Programm_9" 10 "Programm_10" 11 "Programm_11" 12 "Programm_12" 13 "Programm_13" 14 "Programm_14" 15 "Programm_15" ;
VAL_ 901 CHA_Ziel_FahrPr_RGS 0 "nicht_belegt" 1 "Programm_1" 2 "Programm_2" 3 "Programm_3" 4 "Programm_4" 5 "Programm_5" 6 "Programm_6" 7 "Programm_7" 8 "Programm_8" 9 "Programm_9" 10 "Programm_10" 11 "Programm_11" 12 "Programm_12" 13 "Programm_13" 14 "Programm_14" 15 "Programm_15" ;
VAL_ 901 CHA_Ziel_FahrPr_EPS 0 "nicht_belegt" 1 "Programm_1" 2 "Programm_2" 3 "Programm_3" 4 "Programm_4" 5 "Programm_5" 6 "Programm_6" 7 "Programm_7" 8 "Programm_8" 9 "Programm_9" 10 "Programm_10" 11 "Programm_11" 12 "Programm_12" 13 "Programm_13" 14 "Programm_14" 15 "Programm_15" ;
VAL_ 901 CHA_Ziel_FahrPr_ACC 0 "nicht_belegt" 1 "Programm_1" 2 "Programm_2" 3 "Programm_3" 4 "Programm_4" 5 "Programm_5" 6 "Programm_6" 7 "Programm_7" 8 "Programm_8" 9 "Programm_9" 10 "Programm_10" 11 "Programm_11" 12 "Programm_12" 13 "Programm_13" 14 "Programm_14" 15 "Programm_15" ;
VAL_ 901 CHA_Ziel_FahrPr_SAK 0 "nicht_belegt" 1 "Programm_1" 2 "Programm_2" 3 "Programm_3" 4 "Programm_4" 5 "Programm_5" 6 "Programm_6" 7 "Programm_7" 8 "Programm_8" 9 "Programm_9" 10 "Programm_10" 11 "Programm_11" 12 "Programm_12" 13 "Programm_13" 14 "Programm_14" 15 "Programm_15" ;
VAL_ 901 CHA_Ziel_FahrPr_MStSt 0 "nicht_belegt" 1 "Programm_1" 2 "Programm_2" 3 "Programm_3" 4 "Programm_4" 5 "Programm_5" 6 "Programm_6" 7 "Programm_7" 8 "Programm_8" 9 "Programm_9" 10 "Programm_10" 11 "Programm_11" 12 "Programm_12" 13 "Programm_13" 14 "Programm_14" 15 "Programm_15" ;
VAL_ 945 DC_HYB_iAktLV 1022 "Init" 1023 "Fehler" ;
VAL_ 945 DC_HYB_iAktReserveLV 1022 "Init" 1023 "Fehler" ;
VAL_ 945 DC_HYB_uAktLV 254 "Init" 255 "Fehler" ;
VAL_ 945 DC_HYB_LangsRegelung 0 "normale_Regelung" 1 "langsame_Regelung" ;
VAL_ 945 DC_HYB_Abregelung_Temperatur 0 "keine_Begrenzung" 1 "Abregelung_Temperatur" ;
VAL_ 945 DC_HYB_Fehler_RedLeistung 0 "kein_Fehler" 1 "Fehler_RedLeistung" ;
VAL_ 945 DC_HYB_Fehler_intern 0 "kein_Fehler" 1 "Fehler_intern" ;
VAL_ 945 DC_HYB_Fehler_Spannung 0 "kein_Fehler" 1 "Fehler_Spannung" ;
VAL_ 945 DC_HYB_Auslastungsgrad 255 "Fehler" ;
VAL_ 1714 DGN_Verlernzaehler 255 "ungültiger Zählerstand oder kein gültiger Fahrzyklus" ;
VAL_ 1714 KBI_Kilometerstand 1048574 "Init" 1048575 "Fehler" ;
VAL_ 1714 UH_Monat 14 "reserviert" ;
VAL_ 1714 UH_Tag 0 "reserviert" ;
VAL_ 1714 Kombi_02_alt 0 "aktuell" 1 "veraltet" ;
VAL_ 1714 Uhrzeit_01_alt 0 "aktuell" 1 "veraltet" ;
VAL_ 1520 DI_KL_58xd 254 "Init" 255 "Fehler" ;
VAL_ 1520 DI_KL_58xs 126 "Init" 127 "Fehler" ;
VAL_ 1520 DI_KL_58xt 126 "Init" 127 "Fehler" ;
VAL_ 1603 KBI_Einheit_Datum 0 "Tag/Monat/Jahr" 1 "Monat/Tag/Jahr" 2 "Jahr/Monat/Tag" 3 "reserviert" ;
VAL_ 1603 KBI_Einheit_Druck 0 "Druckangabe in bar" 1 "Druckangabe in psi" 2 "Druckangabe in kPa" 3 "tbd." ;
VAL_ 1603 KBI_Einheit_Streckenanz 0 "Kilometer" 1 "Meilen" ;
VAL_ 1603 KBI_MFA_v_Einheit_02 0 "kmh" 1 "mph" ;
VAL_ 1603 KBI_Einheit_Temp 0 "Grad Celsius °C" 1 "Grad Fahrenheit °F" ;
VAL_ 1603 KBI_Einheit_Uhrzeit 0 "24h" 1 " 12h AM/PM" ;
VAL_ 1603 KBI_Einheit_Verbrauch 0 "mpg UK" 1 "mpg USA" 2 "Liter/100km" 3 "km/Liter" ;
VAL_ 1603 KBI_Einheit_Volumen 0 "Liter" 1 "Gallonen UK" 2 "Gallonen USA" 3 "reserviert" ;
VAL_ 260 EPB_QBit_Laengsbeschleunigung 0 "gültiger Wert" 1 "Ersatz-, Init- oder Fehlerwert" ;
VAL_ 260 EPB_QBit_Pedalweg_Kuppl 0 "gültiger Wert" 1 "Ersatz-, Init- oder Fehlerwert" ;
VAL_ 260 EPB_BCM2_Motor_Wakeup 0 "keine Anforderung" 1 "Anforderung an BCM2 Wakeupleitung zum Motor hochzuziehen aufgrund von Car-Wakeup" ;
VAL_ 260 EPB_Freig_Verzoeg_Anf 0 "nicht freigegeben" 1 "freigegeben" ;
VAL_ 260 EPB_Laengsbeschleunigung 255 "Fehler" ;
VAL_ 260 EPB_Pedalweg_Kuppl 0 "Init" 255 "Fehler" ;
VAL_ 260 EPB_Anfahrwunsch_erkannt 0 "kein Anfahrwunsch erkannt" 1 "Anfahrwunsch erkannt" ;
VAL_ 260 EPB_DAA_Randbed_erf 0 "Randbed_nicht_erfuellt" 1 "Randbed_erfuellt" ;
VAL_ 260 EPB_Fehlerstatus 0 "kein Fehler in EPB - AVH darf von ESP ausgeführt werden" 1 "nur VW526: temporärer Fehler" 2 "nur VW526: EPB in Diagnose" 3 "Fehler in EPB - AVH darf von ESP nicht ausgeführt werden" ;
VAL_ 260 EPB_Schalterposition 0 "keine Fahreranforderung" 1 "Fahreranforderung Öffnen" 2 "Fahreranforderung Schließen" 3 "Fehler" ;
VAL_ 260 EPB_QBit_Schalterpos 0 "gültiger Wert (volle Funktion)" 1 " Ersatz-, Init- oder Fehlerwert (Schalter ausser Funktion)" ;
VAL_ 260 EPB_Konsistenz_ACC 0 "kein Fehler erkannt" 1 "Fehler erkannt" ;
VAL_ 260 EPB_Spannkraft 30 "Init" 31 "Fehler" ;
VAL_ 260 EPB_Status 0 "offen" 1 "Bremse_geschl_(Spannkraft_voll/reduziert)" 2 "Aktuator im Lauf" 3 "Fehler" ;
VAL_ 257 ESP_QBit_Gierrate 0 "gueltiger_Wert" 1 "Ersatz_Init_oder_Fehlerwert" ;
VAL_ 257 ESP_QBit_Laengsbeschl 0 "gueltiger_Wert" 1 "Ersatz_Init_oder_Fehlerwert" ;
VAL_ 257 ESP_QBit_Querb 0 "gueltiger_Wert" 1 "Ersatz_Init_oder_Fehlerwert" ;
VAL_ 257 ESP_Stillstandsflag 0 "kein_Stillstand_erkannt" 1 "Stillstand_erkannt" ;
VAL_ 257 ESP_Querbeschleunigung 255 "Fehler" ;
VAL_ 257 ESP_Laengsbeschl 1022 "Signal_nicht_vorhanden" 1023 "Fehler" ;
VAL_ 257 ESP_Verteil_Wankmom 30 "Init" 31 "Fehler" ;
VAL_ 257 ESP_QBit_Anf_Vert_Wank 0 "gueltiger_Wert" 1 "Ersatz_Init_oder_Fehlerwert" ;
VAL_ 257 ESP_Gierrate 16383 "Fehler" ;
VAL_ 257 ESP_VZ_Gierrate 0 "positiv" 1 "negativ" ;
VAL_ 257 ESP_Notbremsanzeige 0 "keine_Notbremsung_erkannt" 1 "Notbremsung_erkannt" ;
VAL_ 257 ESP_SpannungsAnf 0 "keine_Anforderung" 1 "Anforderung_Spannungswert_1" ;
VAL_ 257 ESP_PLA_Abbruch 0 "Init" 1 "Geschwindigkeitsueberschreitung" 2 "Falscher_PLA_Status" 3 "Deaktivierung_durch_Abbruch_Lenkung" 4 "PLA_Bremsanforderung_nach_Stillstand" 5 "Abbruch_durch_Kl15_aus" 6 "Abbruch_durch_FT_offen" ;
VAL_ 257 ESP_Status_ESP_PLA 0 "ESP_PLA_deaktiv" 1 "ESP_PLA_Init" 2 "ESP_PLA_Fehler" 4 "ESP_PLA_aktivierbar" 6 "ESP_PLA_Bremse_aktiv" 8 "ESP_PLA_funktionsbereit" 9 "ESP_PLA_Neustart" 10 "ESP_PLA_Abbruch" ;
